VERSION ""

NS_ :

BS_:

BU_: ZCU_CL LRCF PAM ZCU_F HPC_MAIN_IVI

BO_ 121 FD15_ACK_EVT_DEF: 16 ZCU_CL
 SG_ ECU_Code_ACK : 15|8@0+ (1,0) [0|255] "" LRCF,PAM
 SG_ Rep_UCE : 7|1@0+ (1,0) [0|1] "" LRCF,PAM

BO_ 592 FD15_BSM_DATA_3: 32 ZCU_F
 SG_ ESC_STATUS : 132|3@0+ (1,0) [0|0] "" HPC_MAIN_IVI,LRCF,PAM
 SG_ TCS_STATUS : 22|1@0+ (1,0) [0|0] "" HPC_MAIN_IVI,LRCF,PAM
 SG_ DTC_STATE : 113|1@0+ (1,0) [0|0] "" HPC_MAIN_IVI,LRCF,PAM
 SG_ ESC_BRAKE_STATE : 112|1@0+ (1,0) [0|0] "" HPC_MAIN_IVI,LRCF,PAM
 SG_ ESC_TCS_STATE : 127|1@0+ (1,0) [0|0] "" HPC_MAIN_IVI,LRCF,PAM
 SG_ TCS_BRAKE_STATE : 126|1@0+ (1,0) [0|0] "" HPC_MAIN_IVI,LRCF,PAM
 SG_ TCS_STATE : 125|1@0+ (1,0) [0|0] "" HPC_MAIN_IVI,LRCF,PAM
 SG_ FREE_4 : 15|4@0+ (1,0) [0|0] "" HPC_MAIN_IVI,LRCF,PAM
 SG_ EPB_FAILSTATUS : 21|2@0+ (1,0) [0|0] "" HPC_MAIN_IVI,LRCF,PAM
 SG_ EPB_SECUREMENT_RELEASE_STATUS : 31|1@0+ (1,0) [0|0] "" HPC_MAIN_IVI,LRCF,PAM
 SG_ EPB_STATE : 19|4@0+ (1,0) [0|0] "" HPC_MAIN_IVI,LRCF,PAM
 SG_ EPB_SWITCH_POSITION_STATE : 30|2@0+ (1,0) [0|0] "" HPC_MAIN_IVI,LRCF,PAM
 SG_ VEHICLE_SECUREMENT_STATE : 28|2@0+ (1,0) [0|0] "" HPC_MAIN_IVI,LRCF,PAM
 SG_ E2E_ALIVE_BSM_DATA_3 : 11|4@0+ (1,0) [0|15] "-" HPC_MAIN_IVI,LRCF,PAM
 SG_ EPB_WHEEL_TORQUE_LIMITATION_REQ : 26|1@0+ (1,0) [0|0] "" HPC_MAIN_IVI,LRCF,PAM
 SG_ EPB_WHEEL_TORQUE_LIMITATION_VAL : 25|10@0+ (100,-51100) [-51100|51100] "N.m" HPC_MAIN_IVI,LRCF,PAM
 SG_ ROAD_SLOPE_ESTIMATED_VALUE : 47|8@0+ (1,-127) [-127|126] "%" HPC_MAIN_IVI,LRCF,PAM
 SG_ BRAKE_EMERGENCY_SIGNAL_REQUEST : 71|1@0+ (1,0) [0|0] "" HPC_MAIN_IVI,LRCF,PAM
 SG_ BRAKE_ASSISTANCE_FAILSTATUS : 57|2@0+ (1,0) [0|0] "" HPC_MAIN_IVI,LRCF,PAM
 SG_ AUTO_HOLD_STATE : 135|3@0+ (1,0) [0|0] "" HPC_MAIN_IVI,LRCF,PAM
 SG_ AEB_BRAKING_STATUS : 60|3@0+ (1,0) [0|0] "" HPC_MAIN_IVI,LRCF,PAM
 SG_ AEB_BRAKING_ACKNOWLEDGE : 63|3@0+ (1,0) [0|0] "" HPC_MAIN_IVI,LRCF,PAM
 SG_ DRIVERBRAKEPEDAL_WHEELTRQ_REQ : 55|8@0+ (50,-12650) [-12650|0] "N.m" HPC_MAIN_IVI,LRCF,PAM
 SG_ LXA_SAFETY_DYNVHL_STATE : 104|1@0+ (1,0) [0|0] "" HPC_MAIN_IVI,LRCF,PAM
 SG_ STEERING_COLLABORATI_YAWCTRL_REQ : 119|2@0+ (1,0) [0|0] "" HPC_MAIN_IVI,LRCF,PAM
 SG_ STEERING_CONTROL_AUTOMATIC_REQ : 117|2@0+ (1,0) [0|0] "" HPC_MAIN_IVI,LRCF,PAM
 SG_ STEERING_CONTROL_COLLABORATI_REQ : 115|2@0+ (1,0) [0|0] "" HPC_MAIN_IVI,LRCF,PAM
 SG_ VEHICLE_PATH_CURVATURE : 87|16@0+ (1E-05,-0.32766) [-0.32766|0.32767] "m-1" HPC_MAIN_IVI,LRCF,PAM
 SG_ STEERING_RACKPOSITI_YAWCTRL_STPT : 70|15@0+ (0.01,-164) [-164|163.65] "mm" HPC_MAIN_IVI,LRCF,PAM
 SG_ STEERING_RACKPOSITION_SETPOINT : 103|15@0+ (0.01,-164) [-164|163.65] "mm" HPC_MAIN_IVI,LRCF,PAM
 SG_ SBA_TRIGGER : 124|2@0+ (1,0) [0|0] "" HPC_MAIN_IVI,LRCF,PAM
 SG_ ACC_MOTION_CONTROL_STATE : 122|3@0+ (1,0) [0|0] "" HPC_MAIN_IVI,LRCF,PAM
 SG_ E2E_CRC_BSM_DATA_3 : 7|8@0+ (1,0) [0|0] "-" HPC_MAIN_IVI,LRCF,PAM

BO_ 337 FD15_BSM_DATA_4: 64 ZCU_F
 SG_ CARBODY_LAT_ACCEL_CORRECTED : 103|12@0+ (0.02,-40.94) [-40.94|40.92] "m/s2" HPC_MAIN_IVI,LRCF,PAM
 SG_ WHEEL_LONGI_SPEED_CALCUL_FL : 39|16@0+ (0.01,0) [0|655.33] "km/h" HPC_MAIN_IVI,LRCF,PAM
 SG_ WHEEL_LONGI_SPEED_CALCUL_FR : 55|16@0+ (0.01,0) [0|655.33] "km/h" HPC_MAIN_IVI,LRCF,PAM
 SG_ WHEEL_LONGI_SPEED_CALCUL_RL : 71|16@0+ (0.01,0) [0|655.33] "km/h" HPC_MAIN_IVI,LRCF,PAM
 SG_ WHEEL_LONGI_SPEED_CALCUL_RR : 87|16@0+ (0.01,0) [0|655.33] "km/h" HPC_MAIN_IVI,LRCF,PAM
 SG_ FREE_4 : 15|4@0+ (1,0) [0|0] "" HPC_MAIN_IVI,LRCF,PAM
 SG_ CARBODY_LONG_ACCEL_CORRECTED : 107|12@0+ (0.02,-40.94) [-40.94|40.92] "m/s2" HPC_MAIN_IVI,LRCF,PAM
 SG_ CARBODY_YAW_VELOCITY_FILTERED : 127|11@0+ (0.1,-102.4) [-102.4|102.1] "Degree/s" HPC_MAIN_IVI,LRCF,PAM
 SG_ VEHICLE_LONGI_ACCEL_CALCULATED : 215|10@0+ (0.08,-40.96) [-40.96|40.72] "m/s2" HPC_MAIN_IVI,LRCF,PAM
 SG_ VEHICLE_LONG_SPEED_COMPUTED_VAL : 143|16@0+ (0.01,0) [0|655.33] "km/h" HPC_MAIN_IVI,LRCF,PAM
 SG_ VEHICLE_LONG_SPEED_REFERENCE_VAL : 159|16@0+ (0.01,0) [0|655.33] "km/h" HPC_MAIN_IVI,LRCF,PAM
 SG_ VEHICLE_MOTION_DIRECTION : 254|3@0+ (1,0) [0|0] "" HPC_MAIN_IVI,LRCF,PAM
 SG_ WHEEL_ROLLING_DIRECTION_FL : 175|2@0+ (1,0) [0|0] "" HPC_MAIN_IVI,LRCF,PAM
 SG_ WHEEL_ROLLING_DIRECTION_FR : 173|2@0+ (1,0) [0|0] "" HPC_MAIN_IVI,LRCF,PAM
 SG_ WHEEL_ROLLING_DIRECTION_RL : 171|2@0+ (1,0) [0|0] "" HPC_MAIN_IVI,LRCF,PAM
 SG_ WHEEL_ROLLING_DIRECTION_RR : 169|2@0+ (1,0) [0|0] "" HPC_MAIN_IVI,LRCF,PAM
 SG_ WHEEL_ROTATION_PULSE_FL_COUNTER : 183|8@0+ (1,0) [0|253] "" HPC_MAIN_IVI,LRCF,PAM
 SG_ WHEEL_ROTATION_PULSE_FR_COUNTER : 191|8@0+ (1,0) [0|253] "" HPC_MAIN_IVI,LRCF,PAM
 SG_ WHEEL_ROTATION_PULSE_RL_COUNTER : 199|8@0+ (1,0) [0|253] "" HPC_MAIN_IVI,LRCF,PAM
 SG_ WHEEL_ROTATION_PULSE_RR_COUNTER : 207|8@0+ (1,0) [0|253] "" HPC_MAIN_IVI,LRCF,PAM
 SG_ WHEEL_ROTATION_PULSE_FL_FAIL_STS : 132|1@0+ (1,0) [0|0] "" HPC_MAIN_IVI,LRCF,PAM
 SG_ WHEEL_ROTATION_PULSE_FR_FAIL_STS : 131|1@0+ (1,0) [0|0] "" HPC_MAIN_IVI,LRCF,PAM
 SG_ WHEEL_ROTATION_PULSE_RL_FAIL_STS : 130|1@0+ (1,0) [0|0] "" HPC_MAIN_IVI,LRCF,PAM
 SG_ WHEEL_ROTATION_PULSE_RR_FAIL_STS : 129|1@0+ (1,0) [0|0] "" HPC_MAIN_IVI,LRCF,PAM
 SG_ E2E_ALIVE_BSM_DATA_4_151 : 11|4@0+ (1,0) [0|15] "-" HPC_MAIN_IVI,LRCF,PAM
 SG_ E2E_CRC_BSM_DATA_4_151 : 7|8@0+ (1,0) [0|0] "-" HPC_MAIN_IVI,LRCF,PAM
 SG_ BRAKE_STATE : 217|2@0+ (1,0) [0|0] "" HPC_MAIN_IVI,LRCF,PAM
 SG_ STOP_LIGHTS_ACTIVATION_REQUEST : 241|1@0+ (1,0) [0|0] "" HPC_MAIN_IVI,LRCF,PAM
 SG_ SAFESTOP_BRAKING_STATE : 228|3@0+ (1,0) [0|0] "" HPC_MAIN_IVI,LRCF,PAM
 SG_ BRAKE_PEDAL_PRESSED_STATE : 219|2@0+ (1,0) [0|0] "" HPC_MAIN_IVI,LRCF,PAM
 SG_ BAS_STATE : 25|1@0+ (1,0) [0|0] "" HPC_MAIN_IVI,LRCF,PAM
 SG_ ABS_STATE : 24|1@0+ (1,0) [0|0] "" HPC_MAIN_IVI,LRCF,PAM
 SG_ EBD_STATE : 128|1@0+ (1,0) [0|0] "" HPC_MAIN_IVI,LRCF,PAM
 SG_ ABS_WHEEL_FRONT_LEFT_STATE : 225|1@0+ (1,0) [0|0] "" HPC_MAIN_IVI,LRCF,PAM
 SG_ ABS_WHEEL_FRONT_RIGHT_STATE : 224|1@0+ (1,0) [0|0] "" HPC_MAIN_IVI,LRCF,PAM
 SG_ ABS_WHEEL_REAR_LEFT_STATE : 239|1@0+ (1,0) [0|0] "" HPC_MAIN_IVI,LRCF,PAM
 SG_ ABS_WHEEL_REAR_RIGHT_STATE : 238|1@0+ (1,0) [0|0] "" HPC_MAIN_IVI,LRCF,PAM
 SG_ BRAKE_ASSISTANCE_PRESSURE_VALUE : 237|12@0+ (0.1,-10) [-10|399.3] "bar" HPC_MAIN_IVI,LRCF,PAM
 SG_ ROAD_SLOPE_ACCURACY_STATE : 240|2@0+ (1,0) [0|0] "" HPC_MAIN_IVI,LRCF,PAM
 SG_ FREE_4_2 : 271|4@0+ (1,0) [0|0] "" HPC_MAIN_IVI,LRCF,PAM
 SG_ E2E_CRC_BSM_DATA_4_2 : 263|8@0+ (1,0) [0|0] "-" HPC_MAIN_IVI,LRCF,PAM
 SG_ E2E_ALIVE_BSM_DATA_4_2 : 267|4@0+ (1,0) [0|15] "-" HPC_MAIN_IVI,LRCF,PAM
 SG_ EBD_FAILSTATUS : 23|1@0+ (1,0) [0|0] "" HPC_MAIN_IVI,LRCF,PAM
 SG_ ABS_FAILSTATUS : 22|1@0+ (1,0) [0|0] "" HPC_MAIN_IVI,LRCF,PAM

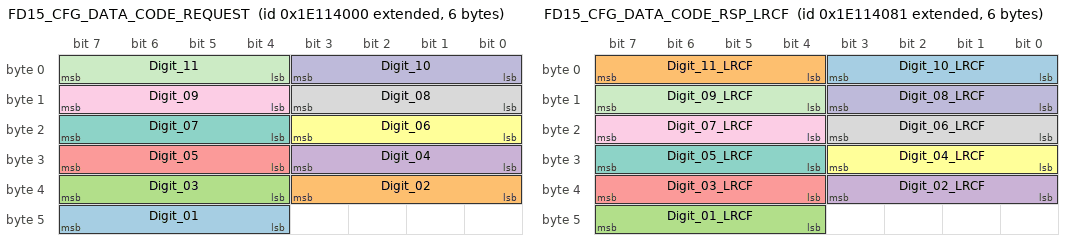
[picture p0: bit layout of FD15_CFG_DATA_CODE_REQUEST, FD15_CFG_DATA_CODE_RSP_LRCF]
BO_ 2651930624 FD15_CFG_DATA_CODE_REQUEST: 6 ZCU_CL
 SG_ Digit_01 : 47|4@0+ (1,0) [0|15] "" LRCF,PAM,ZCU_F
 SG_ Digit_02 : 35|4@0+ (1,0) [0|15] "" LRCF,PAM,ZCU_F
 SG_ Digit_03 : 39|4@0+ (1,0) [0|15] "" LRCF,PAM,ZCU_F
 SG_ Digit_04 : 27|4@0+ (1,0) [0|15] "" LRCF,PAM,ZCU_F
 SG_ Digit_05 : 31|4@0+ (1,0) [0|15] "" LRCF,PAM,ZCU_F
 SG_ Digit_06 : 19|4@0+ (1,0) [0|15] "" LRCF,PAM,ZCU_F
 SG_ Digit_07 : 23|4@0+ (1,0) [0|15] "" LRCF,PAM,ZCU_F
 SG_ Digit_08 : 11|4@0+ (1,0) [0|15] "" LRCF,PAM,ZCU_F
 SG_ Digit_09 : 15|4@0+ (1,0) [0|15] "" LRCF,PAM,ZCU_F
 SG_ Digit_10 : 3|4@0+ (1,0) [0|15] "" LRCF,PAM,ZCU_F
 SG_ Digit_11 : 7|4@0+ (1,0) [0|15] "" LRCF,PAM,ZCU_F

BO_ 2651930753 FD15_CFG_DATA_CODE_RSP_LRCF: 6 LRCF
 SG_ Digit_10_LRCF : 3|4@0+ (1,0) [0|15] "-" ZCU_CL
 SG_ Digit_11_LRCF : 7|4@0+ (1,0) [0|15] "-" ZCU_CL
 SG_ Digit_01_LRCF : 47|4@0+ (1,0) [0|15] "-" ZCU_CL
 SG_ Digit_02_LRCF : 35|4@0+ (1,0) [0|15] "-" ZCU_CL
 SG_ Digit_03_LRCF : 39|4@0+ (1,0) [0|15] "-" ZCU_CL
 SG_ Digit_04_LRCF : 27|4@0+ (1,0) [0|15] "-" ZCU_CL
 SG_ Digit_05_LRCF : 31|4@0+ (1,0) [0|15] "-" ZCU_CL
 SG_ Digit_06_LRCF : 19|4@0+ (1,0) [0|15] "-" ZCU_CL
 SG_ Digit_07_LRCF : 23|4@0+ (1,0) [0|15] "-" ZCU_CL
 SG_ Digit_08_LRCF : 11|4@0+ (1,0) [0|15] "-" ZCU_CL
 SG_ Digit_09_LRCF : 15|4@0+ (1,0) [0|15] "-" ZCU_CL

BO_ 2679898131 FD15_DEV_LRCF_1: 64 LRCF
 SG_ SIG_DEV_LRCF_1 : 7|512@0+ (1,0) [0|0] "" Vector__XXX

BO_ 2679898132 FD15_DEV_LRCF_2: 64 LRCF
 SG_ SIG_DEV_LRCF_2 : 7|512@0+ (1,0) [0|0] "" Vector__XXX

BO_ 2564476661 FD15_DIAG_REQUEST_FD_FOTA_LRCF: 64 HPC_MAIN_IVI
 SG_ N_PDU : 7|64@0+ (1,0) [0|0] "" LRCF

BO_ 2564484085 FD15_DIAG_REQUEST_FD_FOTA_SCRRL: 64 HPC_MAIN_IVI
 SG_ N_PDU : 7|64@0+ (1,0) [0|0] "" LRCF

BO_ 2564483829 FD15_DIAG_REQUEST_FD_FOTA_SCRRR: 64 HPC_MAIN_IVI
 SG_ N_PDU : 7|64@0+ (1,0) [0|0] "" LRCF

BO_ 2564481781 FD15_DIAG_REQUEST_FD_FOTA_SFRM: 64 HPC_MAIN_IVI
 SG_ N_PDU : 7|64@0+ (1,0) [0|0] "" LRCF

BO_ 2564554485 FD15_DIAG_REQUEST_FD_FUNC_FOTA: 64 HPC_MAIN_IVI
 SG_ N_PDU : 7|64@0+ (1,0) [0|0] "" LRCF,PAM,ZCU_F

BO_ 2564554482 FD15_DIAG_REQUEST_FD_FUNCTIONAL: 64 HPC_MAIN_IVI
 SG_ N_PDU : 7|64@0+ (1,0) [0|0] "" LRCF,PAM,ZCU_F

BO_ 2564476658 FD15_DIAG_REQUEST_FD_LRCF: 64 HPC_MAIN_IVI
 SG_ N_PDU : 7|64@0+ (1,0) [0|0] "" LRCF

BO_ 2564484082 FD15_DIAG_REQUEST_FD_SCRRL: 64 HPC_MAIN_IVI
 SG_ N_PDU : 7|64@0+ (1,0) [0|0] "" LRCF

BO_ 2564483826 FD15_DIAG_REQUEST_FD_SCRRR: 64 HPC_MAIN_IVI
 SG_ N_PDU : 7|64@0+ (1,0) [0|0] "" LRCF

BO_ 2564481778 FD15_DIAG_REQUEST_FD_SFRM: 64 HPC_MAIN_IVI
 SG_ N_PDU : 7|64@0+ (1,0) [0|0] "" LRCF

BO_ 2564486606 FD15_DIAG_RESPONSE_FD_FOTA_LRCF: 64 LRCF
 SG_ N_PDU : 7|64@0+ (1,0) [0|0] "" HPC_MAIN_IVI

BO_ 2564486635 FD15_DIAG_RESPONSE_FD_FOTA_SCRRL: 64 LRCF
 SG_ N_PDU : 7|64@0+ (1,0) [0|0] "" HPC_MAIN_IVI

BO_ 2564486634 FD15_DIAG_RESPONSE_FD_FOTA_SCRRR: 64 LRCF
 SG_ N_PDU : 7|64@0+ (1,0) [0|0] "" HPC_MAIN_IVI

BO_ 2564486626 FD15_DIAG_RESPONSE_FD_FOTA_SFRM: 64 LRCF
 SG_ N_PDU : 7|64@0+ (1,0) [0|0] "" HPC_MAIN_IVI

BO_ 2564485838 FD15_DIAG_RESPONSE_FD_LRCF: 64 LRCF
 SG_ N_PDU : 7|64@0+ (1,0) [0|0] "" HPC_MAIN_IVI

BO_ 2564485867 FD15_DIAG_RESPONSE_FD_SCRRL: 64 LRCF
 SG_ N_PDU : 7|64@0+ (1,0) [0|0] "" HPC_MAIN_IVI

BO_ 2564485866 FD15_DIAG_RESPONSE_FD_SCRRR: 64 LRCF
 SG_ N_PDU : 7|64@0+ (1,0) [0|0] "" HPC_MAIN_IVI

BO_ 2564485858 FD15_DIAG_RESPONSE_FD_SFRM: 64 LRCF
 SG_ N_PDU : 7|64@0+ (1,0) [0|0] "" HPC_MAIN_IVI

BO_ 2564682219 FD15_DIAGNOSTIC_ROE_SCRRL: 8 LRCF
 SG_ N_PDU : 7|64@0+ (1,0) [0|0] "" HPC_MAIN_IVI

BO_ 2564682218 FD15_DIAGNOSTIC_ROE_SCRRR: 8 LRCF
 SG_ N_PDU : 7|64@0+ (1,0) [0|0] "" HPC_MAIN_IVI

BO_ 2564682210 FD15_DIAGNOSTIC_ROE_SFRM: 8 LRCF
 SG_ N_PDU : 7|64@0+ (1,0) [0|0] "" HPC_MAIN_IVI

BO_ 340 FD15_EPS_DATA_1: 32 ZCU_F
 SG_ FREE_4 : 15|4@0+ (1,0) [0|0] "" LRCF
 SG_ STEERING_ASSIST_FAILSTATUS : 135|3@0+ (1,0) [0|0] "" LRCF
 SG_ STEERING_ASSIST_STATUS : 103|3@0+ (1,0) [0|0] "" LRCF
 SG_ STEERING_POWERSUPPLY_BOOST_REQ : 129|2@0+ (1,0) [0|0] "" LRCF
 SG_ LKA_STEERING_ACTUATION_STATE : 40|1@0+ (1,0) [0|0] "" LRCF
 SG_ LKA_STEERING_AVAILABILITY_STATE : 73|2@0+ (1,0) [0|0] "" LRCF
 SG_ LXA_STEERING_LIMITATION_STATE : 24|1@0+ (1,0) [0|0] "" LRCF
 SG_ LXA_STEERING_STATE : 91|2@0+ (1,0) [0|0] "" LRCF
 SG_ STEERINGWHEEL_ANGLE_CAL_FRT_STS : 89|2@0+ (1,0) [0|0] "" LRCF
 SG_ STEERINGWHEEL_ANGLE_REL_FRT_STE : 132|3@0+ (1,0) [0|0] "" LRCF
 SG_ STEERINGWHEEL_ANGLE_FRONT_TYPE : 57|2@0+ (1,0) [0|0] "" LRCF
 SG_ HANDWHEEL_STEERING_TRQ_MEASURED : 100|11@0+ (0.01,-10.2) [-10.2|10.27] "N.m" LRCF
 SG_ LXA_STEERING_TORQUE_ADDON_VALUE : 127|8@0+ (0.1,-12.5) [-12.5|13] "N.m" LRCF
 SG_ HANDWHEEL_STEERING_ANGLE_VALUE : 71|14@0+ (0.1,-820) [-820|818.2] "Degree" LRCF
 SG_ STEERINGWHEEL_ANGLE_FRT_ACCURACY : 105|10@0+ (0.1,-51) [-51|51.2] "Degree" LRCF
 SG_ STEERINGWHEEL_ANGLE_FRONT_VAL : 55|14@0+ (0.1,-820) [-820|818.2] "Degree" LRCF
 SG_ STEERINGWHEEL_ANGLE_REL_FRT_VA : 39|15@0+ (0.1,-1638) [-1638|1638.6] "Degree" LRCF
 SG_ WHEEL_STEERINGANGLE_FRONT_VAL : 23|15@0+ (0.005,-82) [-82|81.83] "Degree" LRCF
 SG_ STEERINGWHEEL_ROT_VELOCITY_FRT : 87|12@0+ (1,-2050) [-2050|2044] "Degree/s" LRCF
 SG_ E2E_CRC_EPS_DATA_1 : 7|8@0+ (1,0) [0|0] "-" LRCF
 SG_ E2E_ALIVE_EPS_DATA_1 : 11|4@0+ (1,0) [0|15] "-" LRCF

BO_ 596 FD15_EPS_DATA_2: 32 ZCU_F
 SG_ FREE_4 : 15|4@0+ (1,0) [0|0] "" LRCF
 SG_ STEERING_RACK_POSITION_VALUE : 23|15@0+ (0.01,-164) [-164|163.65] "mm" LRCF
 SG_ E2E_ALIVE_EPS_DATA_2 : 11|4@0+ (1,0) [0|15] "-" LRCF
 SG_ E2E_CRC_EPS_DATA_2 : 7|8@0+ (1,0) [0|0] "-" LRCF

BO_ 1406 FD15_FLT_EVT_LRCF: 24 LRCF
 SG_ ECU_CODE : 123|8@0+ (1,0) [0|255] "No Unit" ZCU_CL
 SG_ RELEVANCE_OF_DATE : 2|1@0+ (1,0) [0|0] "-" ZCU_CL
 SG_ NM_Frames : 7|2@0+ (1,0) [0|3] "" ZCU_CL
 SG_ Status_DTC : 3|1@0+ (1,0) [0|1] "" ZCU_CL
 SG_ Fault_Code : 15|24@0+ (1,0) [0|16777215] "" ZCU_CL
 SG_ DTC_Format_Identifier : 131|8@0+ (1,0) [0|255] "" ZCU_CL
 SG_ KM_DEH : 103|24@0+ (0.1,0) [0|1677721.4] "km" ZCU_CL
 SG_ Absolute_Defect_Event_Year : 39|16@0+ (1,0) [0|65534] "Year" ZCU_CL
 SG_ Absolute_Defect_Event_Month : 55|4@0+ (1,1) [1|15] "month" ZCU_CL
 SG_ Absolute_Defect_Event_Day : 63|5@0+ (1,1) [1|31] "day" ZCU_CL
 SG_ Absolute_Defect_Event_Hour : 71|5@0+ (1,0) [0|30] "h" ZCU_CL
 SG_ Absolute_Defect_Event_Minute : 79|6@0+ (1,0) [0|62] "min" ZCU_CL
 SG_ Absolute_Defect_Event_Second : 87|6@0+ (1,0) [0|62] "Sec" ZCU_CL
 SG_ Abs_Defect_Event_Tenth_Of_Sec : 95|8@0+ (0.1,0) [0|25.4] "Sec" ZCU_CL

BO_ 951 FD15_HPC_DATA_1: 32 ZCU_CL
 SG_ FREE_4 : 15|4@0+ (1,0) [0|0] "" LRCF,PAM,ZCU_F
 SG_ AEB_HAPTIC_REQUEST : 23|1@0+ (1,0) [0|0] "" LRCF,PAM,ZCU_F
 SG_ ACC_MODE_CHOICE_REQ : 55|2@0+ (1,0) [0|0] "" LRCF,PAM,ZCU_F
 SG_ ACC_AVAILABILITY_FOR_SWITCH : 71|1@0+ (1,0) [0|0] "" LRCF,PAM,ZCU_F
 SG_ ACC_TAKEOVER_REQUEST : 70|2@0+ (1,0) [0|0] "" LRCF,PAM,ZCU_F
 SG_ BLINDSPOTDETECTION_DRIVERREQUEST : 102|1@0+ (1,0) [0|0] "" LRCF,PAM,ZCU_F
 SG_ MAIN_LATERAL_ST_INFO : 22|3@0+ (1,0) [0|0] "" LRCF,PAM,ZCU_F
 SG_ MAIN_LONGITUDINAL_STINFO : 19|3@0+ (1,0) [0|0] "" LRCF,PAM,ZCU_F
 SG_ WPP_DRIVER_INHIBITION_REQUEST : 26|1@0+ (1,0) [0|0] "" LRCF,PAM,ZCU_F
 SG_ AEB_HMI_READY : 30|1@0+ (1,0) [0|0] "" LRCF,PAM,ZCU_F
 SG_ FCW_HMI_READY : 29|1@0+ (1,0) [0|0] "" LRCF,PAM,ZCU_F
 SG_ FCW_HMI_SETTING : 28|2@0+ (1,0) [0|0] "" LRCF,PAM,ZCU_F
 SG_ AEB_DRIVER_ATTENTIVE : 16|1@0+ (1,0) [0|0] "" LRCF,PAM,ZCU_F
 SG_ AEB_ROAD_FRICTION : 31|1@0+ (1,0) [0|0] "" LRCF,PAM,ZCU_F
 SG_ E2E_CRC_HPC_DATA_1 : 7|8@0+ (1,0) [0|0] "-" LRCF,PAM,ZCU_F
 SG_ E2E_ALIVE_HPC_DATA_1 : 11|4@0+ (1,0) [0|15] "-" LRCF,PAM,ZCU_F
 SG_ AEB_HMI_LIMITATION : 25|2@0+ (1,0) [0|0] "" LRCF,PAM,ZCU_F
 SG_ LONGITUDINAL_SPEED_SETPOINT : 39|15@0+ (0.01,0) [0|327.66] "km/h" LRCF,PAM,ZCU_F
 SG_ ELKS_SELECTION_REQ : 40|1@0+ (1,0) [0|0] "" LRCF,PAM,ZCU_F
 SG_ FCW_SETTING : 53|2@0+ (1,0) [0|0] "" LRCF,PAM,ZCU_F
 SG_ LRCF_CANCEL_REQ : 51|1@0+ (1,0) [0|0] "" LRCF,PAM,ZCU_F
 SG_ LRCF_DCTYPE : 49|2@0+ (1,0) [0|0] "" LRCF,PAM,ZCU_F
 SG_ LRCF_NUMBEROFDC : 63|8@0+ (1,0) [0|100] "" LRCF,PAM,ZCU_F
 SG_ LRCF_TRANSFER_READINESS_REQ : 50|1@0+ (1,0) [0|0] "" LRCF,PAM,ZCU_F
 SG_ LPA_STATE_INFO : 73|2@0+ (1,0) [0|0] "" LRCF,PAM,ZCU_F
 SG_ VHL_DL_OR_TX_ACTIVE : 68|2@0+ (1,0) [0|0] "" LRCF,PAM,ZCU_F
 SG_ OTA_UPDATE_STATUS : 66|4@0+ (1,0) [0|0] "" LRCF,PAM,ZCU_F
 SG_ ELKS_COCKPIT_FAILURE : 78|1@0+ (1,0) [0|0] "" LRCF,PAM,ZCU_F
 SG_ ACC_MAIN_ST_INFO : 77|4@0+ (1,0) [0|0] "" LRCF,PAM,ZCU_F
 SG_ ALERT_SOUND_LOCALIZATION : 87|4@0+ (1,0) [0|0] "" LRCF,PAM,ZCU_F
 SG_ ALERT_SOUND_LEVEL : 83|8@0+ (1,0) [0|255] "" LRCF,PAM,ZCU_F
 SG_ ALERT_SOUND_NUMBER : 91|5@0+ (1,0) [0|30] "" LRCF,PAM,ZCU_F
 SG_ SL_SPEED_SETPOINT_DUA : 107|8@0+ (1,0) [0|254] "km/h" LRCF,PAM,ZCU_F
 SG_ SL_ACTIVATION_REQUEST : 108|1@0+ (1,0) [0|1] "" LRCF,PAM,ZCU_F
 SG_ CC_ACTIVATION_REQUEST : 101|1@0+ (1,0) [0|1] "" LRCF,PAM,ZCU_F
 SG_ CC_SPEED_SETPOINT_DUA : 100|8@0+ (1,0) [0|254] "km/h" LRCF,PAM,ZCU_F
 SG_ REGULATION_LONGI_TYPE : 115|2@0+ (1,0) [0|3] "" LRCF,PAM,ZCU_F
 SG_ LPA_ST_INFO : 113|2@0+ (1,0) [0|3] "" LRCF,PAM,ZCU_F
 SG_ DDMS_STATE : 127|3@0+ (1,0) [0|7] "" LRCF,PAM,ZCU_F
 SG_ DDMS_FOV_AREA : 124|3@0+ (1,0) [0|7] "" LRCF,PAM,ZCU_F
 SG_ DDMS_EYE_STATUS : 121|3@0+ (1,0) [0|7] "" LRCF,PAM,ZCU_F
 SG_ DDMS_DROWSINESS_LEVEL : 134|3@0+ (1,0) [0|7] "" LRCF,PAM,ZCU_F
 SG_ DDMS_DISTRACTION_LEVEL : 131|3@0+ (1,0) [0|7] "" LRCF,PAM,ZCU_F
 SG_ DDM_SAFETY_MODE_REQUEST : 128|3@0+ (1,0) [0|7] "" LRCF,PAM,ZCU_F

BO_ 1719 FD15_HPC_DATA_2: 32 ZCU_CL
 SG_ RCTA_DRIVER_INHIBITION_REQUEST : 56|1@0+ (1,0) [0|0] "" LRCF,PAM
 SG_ ACC_TIV_SETPOINT : 22|2@0+ (1,0) [0|0] "" LRCF,PAM
 SG_ MAIN_AUTOMATION_ST_INFO : 20|3@0+ (1,0) [0|0] "" LRCF,PAM
 SG_ COUNTRY_CODE_MERGED : 31|24@0+ (1,0) [0|16777215] "" LRCF,PAM
 SG_ ACC_SPEED_SET_POINT : 55|15@0+ (0.01,0) [0|327.67] "km/h" LRCF,PAM

BO_ 633 FD15_HPC_DATA_3: 32 ZCU_CL
 SG_ ACC_STATE_INFO_FOR_CHASSIS : 33|2@0+ (1,0) [0|0] "" LRCF
 SG_ PACC_ACCEL_LONGI_REQUEST : 28|10@0+ (0.01,-5) [-5|5.23] "m/s2" LRCF
 SG_ PACC_BEVENT_IN_PROGRESS : 34|1@0+ (1,0) [0|0] "" LRCF
 SG_ GPAC_BINHIB_ACCEL_BEND_REQ : 29|1@0+ (0,0) [0|0] "" LRCF
 SG_ PACC_POTACCEL_LONGI_REQUEST : 23|10@0+ (0.01,-5) [-5|5.23] "m/s2" LRCF

BO_ 1154 FD15_LRCF_DATA_10: 64 LRCF
 SG_ IHM_R2_POSITION : 279|6@0+ (1,0) [0|0] "" ZCU_CL
 SG_ FRONTCAM_EGO_OBJ_TYPE : 299|3@0+ (1,0) [0|0] "" ZCU_CL
 SG_ FRONTCAM_EGO2_OBJ_TYPE : 296|3@0+ (1,0) [0|0] "" ZCU_CL
 SG_ FRONTCAM_L1_OBJ_TYPE : 309|3@0+ (1,0) [0|0] "" ZCU_CL
 SG_ FRONTCAM_L2_OBJ_TYPE : 306|3@0+ (1,0) [0|0] "" ZCU_CL
 SG_ FRONTCAM_L3_OBJ_TYPE : 319|3@0+ (1,0) [0|0] "" ZCU_CL
 SG_ FRONTCAM_R1_OBJ_TYPE : 316|3@0+ (1,0) [0|0] "" ZCU_CL
 SG_ FRONTCAM_R2_OBJ_TYPE : 313|3@0+ (1,0) [0|0] "" ZCU_CL
 SG_ FRONTCAM_R3_OBJ_TYPE : 326|3@0+ (1,0) [0|0] "" ZCU_CL
 SG_ FRONTCAM_EGO_OBJ_CONFID_OBJ : 283|2@0+ (1,0) [0|0] "" ZCU_CL
 SG_ FRONTCAM_EGO2_OBJ_CONFID_OBJ : 281|2@0+ (1,0) [0|0] "" ZCU_CL
 SG_ FRONTCAM_L1_OBJ_CONFID_OBJ : 295|2@0+ (1,0) [0|0] "" ZCU_CL
 SG_ FRONTCAM_L2_OBJ_CONFID_OBJ : 293|2@0+ (1,0) [0|0] "" ZCU_CL
 SG_ FRONTCAM_L3_OBJ_CONFID_OBJ : 291|2@0+ (1,0) [0|0] "" ZCU_CL
 SG_ FRONTCAM_R1_OBJ_CONFID_OBJ : 289|2@0+ (1,0) [0|0] "" ZCU_CL
 SG_ FRONTCAM_R2_OBJ_CONFID_OBJ : 303|2@0+ (1,0) [0|0] "" ZCU_CL
 SG_ FRONTCAM_R3_OBJ_CONFID_OBJ : 301|2@0+ (1,0) [0|0] "" ZCU_CL
 SG_ FRONTCAM_EGO_OBJ_LAT_DISTANCE : 29|6@0+ (0.5,-16) [-16|15.5] "m" ZCU_CL
 SG_ FRONTCAM_EGO2_OBJ_LAT_DISTANCE : 45|6@0+ (0.5,-16) [-16|15.5] "m" ZCU_CL
 SG_ FRONTCAM_L1_OBJ_LAT_DISTANCE : 61|6@0+ (0.5,-16) [-16|15.5] "m" ZCU_CL
 SG_ FRONTCAM_L2_OBJ_LAT_DISTANCE : 77|6@0+ (0.5,-16) [-16|15.5] "m" ZCU_CL
 SG_ FRONTCAM_L3_OBJ_LAT_DISTANCE : 93|6@0+ (0.5,-16) [-16|15.5] "m" ZCU_CL
 SG_ FRONTCAM_R1_OBJ_LAT_DISTANCE : 109|6@0+ (0.5,-16) [-16|15.5] "m" ZCU_CL
 SG_ FRONTCAM_R2_OBJ_LAT_DISTANCE : 125|6@0+ (0.5,-16) [-16|15.5] "m" ZCU_CL
 SG_ FRONTCAM_R3_OBJ_LAT_DISTANCE : 141|6@0+ (0.5,-16) [-16|15.5] "m" ZCU_CL
 SG_ FRONTCAM_EGO_OBJ_LONGI_REL_SPD : 23|10@0+ (0.5,-256) [-256|255.5] "m/s" ZCU_CL
 SG_ FRONTCAM_EGO2_OBJ_LONGI_REL_SPD : 39|10@0+ (0.5,-256) [-256|255.5] "m/s" ZCU_CL
 SG_ FRONTCAM_L1_OBJ_LONGI_REL_SPD : 55|10@0+ (0.5,-256) [-256|255.5] "m/s" ZCU_CL
 SG_ FRONTCAM_L2_OBJ_LONGI_REL_SPD : 71|10@0+ (0.5,-256) [-256|255.5] "m/s" ZCU_CL
 SG_ FRONTCAM_L3_OBJ_LONGI_REL_SPD : 87|10@0+ (0.5,-256) [-256|255.5] "m/s" ZCU_CL
 SG_ FRONTCAM_R1_OBJ_LONGI_REL_SPD : 103|10@0+ (0.5,-256) [-256|255.5] "m/s" ZCU_CL
 SG_ FRONTCAM_R2_OBJ_LONGI_REL_SPD : 119|10@0+ (0.5,-256) [-256|255.5] "m/s" ZCU_CL
 SG_ FRONTCAM_R3_OBJ_LONGI_REL_SPD : 135|10@0+ (0.5,-256) [-256|255.5] "m/s" ZCU_CL
 SG_ FRONTCAM_L2_OBJ_LAT_REL_SPD : 151|7@0+ (0.5,-32) [-32|31.5] "m/s" ZCU_CL
 SG_ FRONTCAM_L3_OBJ_LAT_REL_SPD : 190|7@0+ (0.5,-32) [-32|31.5] "m/s" ZCU_CL
 SG_ FRONTCAM_R1_OBJ_LAT_REL_SPD : 154|7@0+ (0.5,-32) [-32|31.5] "m/s" ZCU_CL
 SG_ FRONTCAM_R2_OBJ_LAT_REL_SPD : 163|7@0+ (0.5,-32) [-32|31.5] "m/s" ZCU_CL
 SG_ FRONTCAM_R3_OBJ_LAT_REL_SPD : 172|7@0+ (0.5,-32) [-32|31.5] "m/s" ZCU_CL
 SG_ FRONTCAM_EGO_OBJ_HANDLE : 181|7@0+ (1,0) [0|127] "" ZCU_CL
 SG_ FRONTCAM_EGO2_OBJ_HANDLE : 199|7@0+ (1,0) [0|127] "" ZCU_CL
 SG_ FRONTCAM_L1_OBJ_HANDLE : 192|7@0+ (1,0) [0|127] "" ZCU_CL
 SG_ FRONTCAM_L2_OBJ_HANDLE : 201|7@0+ (1,0) [0|127] "" ZCU_CL
 SG_ FRONTCAM_L3_OBJ_HANDLE : 210|7@0+ (1,0) [0|127] "" ZCU_CL
 SG_ FRONTCAM_R1_OBJ_HANDLE : 219|7@0+ (1,0) [0|127] "" ZCU_CL
 SG_ FRONTCAM_R2_OBJ_HANDLE : 228|7@0+ (1,0) [0|127] "" ZCU_CL
 SG_ FRONTCAM_R3_OBJ_HANDLE : 247|7@0+ (1,0) [0|127] "" ZCU_CL
 SG_ IHM_EGO_POSITION : 273|6@0+ (1,0) [0|0] "" ZCU_CL
 SG_ IHM_L1_POSITION : 255|6@0+ (1,0) [0|0] "" ZCU_CL
 SG_ IHM_L2_POSITION : 144|6@0+ (1,0) [0|0] "" ZCU_CL
 SG_ IHM_R1_POSITION : 237|6@0+ (1,0) [0|0] "" ZCU_CL

BO_ 661 FD15_LRCF_DATA_11: 64 LRCF
 SG_ FCAM_VRU4_TYPE : 500|2@0+ (1,0) [0|0] "" ZCU_CL
 SG_ FCAM_VRU5_TYPE : 498|2@0+ (1,0) [0|0] "" ZCU_CL
 SG_ FCAM_VRU1_TYPE : 490|2@0+ (1,0) [0|0] "" ZCU_CL
 SG_ FCAM_VRU2_TYPE : 488|2@0+ (1,0) [0|0] "" ZCU_CL
 SG_ FCAM_VRU3_TYPE : 502|2@0+ (1,0) [0|0] "" ZCU_CL
 SG_ FCAM_VRU4_LONG_DIST : 439|8@0+ (0.5,0) [0|127.5] "m" ZCU_CL
 SG_ FCAM_VRU2_LONG_DIST : 423|8@0+ (0.5,0) [0|127.5] "m" ZCU_CL
 SG_ FCAM_VRU3_LAT_DIST : 459|6@0+ (0.5,-16) [-16|15.5] "" ZCU_CL
 SG_ FCAM_VRU5_LAT_DIST : 479|6@0+ (0.5,-16) [-16|15.5] "" ZCU_CL
 SG_ FCAM_VRU1_LONG_DIST : 415|8@0+ (0.5,0) [0|127.5] "m" ZCU_CL
 SG_ FCAM_VRU3_LONG_DIST : 431|8@0+ (0.5,0) [0|127.5] "m" ZCU_CL
 SG_ FCAM_VRU5_LONG_DIST : 447|8@0+ (0.5,0) [0|127.5] "m" ZCU_CL
 SG_ FCAM_VRU1_LAT_DIST : 455|6@0+ (0.5,-16) [-16|15.5] "" ZCU_CL
 SG_ FCAM_VRU2_LAT_DIST : 449|6@0+ (0.5,-16) [-16|15.5] "" ZCU_CL
 SG_ FCAM_VRU4_LAT_DIST : 469|6@0+ (0.5,-16) [-16|15.5] "" ZCU_CL
 SG_ EGO_DIR_ROAD_LANENUMBER : 20|3@0+ (1,0) [0|7] "" ZCU_CL
 SG_ FCAM_LEFTRIGHT_CONFIDENCE_MEA : 31|7@0+ (0.01,0) [0|1.27] "" ZCU_CL
 SG_ FCAM_LEFTRIGHT_LINE_DIS_ACTUAL : 71|11@0+ (0.016,-16.384) [-16.384|16.336] "m" ZCU_CL
 SG_ FCAM_LEFTRIGHT_LINE_LAT_DIST : 63|6@0+ (0.5,-16) [-16|15.5] "m" ZCU_CL
 SG_ FCAM_LEFTRIGHT_LINECOLOR : 17|2@0+ (1,0) [0|3] "" ZCU_CL
 SG_ FCAM_LEFTRIGHT_LINECURVATURE_EST : 47|16@0+ (2E-06,-0.065536) [-0.065536|0.065530] "m-1" ZCU_CL
 SG_ FCAM_LEFTRIGHT_LINECURVATURE_DER : 87|17@0+ (4E-09,-0.000131072) [-0.000131072|0.00013106] "m-2" ZCU_CL
 SG_ FCAM_LLANE_ROADEDG_CURVATURE_DER : 119|17@0+ (4E-09,-0.000131072) [-0.000131072|0.00013106] "m-2" ZCU_CL
 SG_ FCAM_RIGHTLEFT_LINECURVATURE_DER : 303|17@0+ (4E-09,-0.000131072) [-0.000131072|0.00013106] "m-2" ZCU_CL
 SG_ FCAM_RLANE_ROADEDG_CURVATURE_DER : 279|17@0+ (4E-09,-0.000131072) [-0.000131072|0.00013106] "m-2" ZCU_CL
 SG_ FCAM_LLANE_ROADEDG_CURVATURE_EST : 143|16@0+ (2E-06,-0.065536) [-0.065536|0.065530] "m-1" ZCU_CL
 SG_ FCAM_RIGHTLEFT_LINECURVATURE_EST : 327|16@0+ (2E-06,-0.065536) [-0.065536|0.065530] "m-1" ZCU_CL
 SG_ FCAM_RLANE_ROADEDG_CURVATURE_EST : 343|16@0+ (2E-06,-0.065536) [-0.065536|0.065530] "m-1" ZCU_CL
 SG_ FCAM_LLANE_ROADEDG_DIST_ACTUAL : 153|11@0+ (0.016,-16.384) [-16.384|16.336] "m" ZCU_CL
 SG_ FCAM_RIGHTLEFT_LINE_DIST_ACTUAL : 247|11@0+ (0.016,-16.384) [-16.384|16.336] "m" ZCU_CL
 SG_ FCAM_RLANE_ROADEDG_DIST_ACTUAL : 359|11@0+ (0.016,-16.384) [-16.384|16.336] "m" ZCU_CL
 SG_ FCAM_LEFTRIGHT_LINEHEADINGANGLE : 102|12@0+ (0.015,-30) [-30|31.395] "Degree" ZCU_CL
 SG_ FCAM_LLANE_ROADEDG_HEADINGANGLE : 174|12@0+ (0.015,-30) [-30|31.395] "Degree" ZCU_CL
 SG_ FCAM_RIGHTLEFT_LINEHEADINGANGLE : 391|12@0+ (0.015,-30) [-30|31.395] "Degree" ZCU_CL
 SG_ FCAM_RLANE_ROADEDG_HEADINGANGLE : 395|12@0+ (0.015,-30) [-30|31.395] "Degree" ZCU_CL
 SG_ FCAM_RIGHTLEFT_LINE_LAT_DIST : 159|6@0+ (0.5,-16) [-16|15.5] "m" ZCU_CL
 SG_ FCAM_LEFTRIGHT_LINEVIEW_RANGEEND : 231|9@0+ (0.5,0) [0|255.5] "m" ZCU_CL
 SG_ FCAM_LEFTRIGHT_LINEVIEW_RANGESTR : 238|7@0+ (0.5,0) [0|63.5] "m" ZCU_CL
 SG_ FCAM_LLANE_ROADEDG_CONFIDENC_MEA : 191|7@0+ (0.01,0) [0|1.27] "" ZCU_CL
 SG_ FCAM_LLANE_ROADEDG_VIEW_RANGEEND : 199|9@0+ (0.5,0) [0|255.5] "m" ZCU_CL
 SG_ FCAM_LLINE_CONFIDENCE_MEA : 206|7@0+ (0.01,0) [0|1.27] "" ZCU_CL
 SG_ FCAM_NEXTLEFTLINE_CONFIDENCE_MEA : 134|7@0+ (0.01,0) [0|1.27] "" ZCU_CL
 SG_ FCAM_NEXTRIGHTLINE_CONFIDENC_MEA : 294|7@0+ (0.01,0) [0|1.27] "" ZCU_CL
 SG_ FCAM_RIGHTLEFT_CONFIDENCE_MEA : 318|7@0+ (0.01,0) [0|1.27] "" ZCU_CL
 SG_ FCAM_RLANE_ROADEDG_CONFIDENC_MEA : 382|7@0+ (0.01,0) [0|1.27] "" ZCU_CL
 SG_ FCAM_RLANE_ROADEDG_VIEW_RANGEEND : 375|9@0+ (0.5,0) [0|255.5] "m" ZCU_CL
 SG_ FCAM_RLINE_CONFIDENCE_MEA : 472|7@0+ (0.01,0) [0|1.27] "" ZCU_CL
 SG_ FCAM_LEFTRIGHT_LINEDETECTIONSTS : 24|1@0+ (1,0) [0|1] "" ZCU_CL
 SG_ FCAM_LEFTRIGHT_LINEMARKERQUALITY : 57|2@0+ (1,0) [0|3] "" ZCU_CL
 SG_ FCAM_LEFTRIGHT_LINETYPE : 23|3@0+ (1,0) [0|7] "" ZCU_CL
 SG_ FCAM_RIGHTLEFT_LINETYPE : 252|3@0+ (1,0) [0|7] "" ZCU_CL
 SG_ FCAM_RIGHTLEFT_LINEDETECTIONSTS : 364|1@0+ (1,0) [0|1] "" ZCU_CL
 SG_ FCAM_RIGHTLEFT_LINECOLOR : 249|2@0+ (1,0) [0|3] "" ZCU_CL
 SG_ FCAM_LLANE_ROADEDG_MARKERQUALITY : 73|2@0+ (1,0) [0|3] "" ZCU_CL
 SG_ FCAM_RIGHTLEFT_LINEMARKERQUALITY : 363|2@0+ (1,0) [0|3] "" ZCU_CL
 SG_ FCAM_RLANE_ROADEDG_MARKERQUALITY : 361|2@0+ (1,0) [0|3] "" ZCU_CL
 SG_ FCAM_LLANE_ROADEDG_DET_STATUS : 32|1@0+ (1,0) [0|1] "" ZCU_CL
 SG_ FCAM_LLANE_ROADEDG_VIEW_RANSTART : 39|7@0+ (0.5,0) [0|63.5] "m" ZCU_CL
 SG_ FCAM_RLANE_ROADEDG_VIEW_RANSTART : 481|7@0+ (0.5,0) [0|63.5] "m" ZCU_CL
 SG_ FCAM_LLANE_ROADEDGETYPE : 76|3@0+ (1,0) [0|7] "" ZCU_CL
 SG_ FCAM_LLINE_VALIDFORLKA : 184|1@0+ (1,0) [0|1] "" ZCU_CL
 SG_ FCAM_RIGHTLEFT_LINEVIEW_RANGEEND : 215|9@0+ (0.5,0) [0|255.5] "m" ZCU_CL
 SG_ FCAM_RIGHTLEFT_LINEVIEW_RANGESTR : 222|7@0+ (0.5,0) [0|63.5] "m" ZCU_CL
 SG_ FCAM_OBJECTCROSSING : 178|2@0+ (1,0) [0|3] "" ZCU_CL
 SG_ FCAM_RLANE_ROADEDG_DET_STATUS : 176|1@0+ (1,0) [0|1] "" ZCU_CL
 SG_ FCAM_RLANE_ROADEDGETYPE : 106|3@0+ (1,0) [0|7] "" ZCU_CL
 SG_ FCAM_RLINE_VALIDFORLKA : 473|1@0+ (1,0) [0|1] "" ZCU_CL

BO_ 641 FD15_LRCF_DATA_2: 32 LRCF
 SG_ FREE_4 : 15|4@0+ (1,0) [0|0] "" ZCU_CL,ZCU_F
 SG_ AEB_PREFILL_REQUEST : 19|1@0+ (1,0) [0|0] "" ZCU_CL,ZCU_F
 SG_ AEB_STATE_A : 22|3@0+ (1,0) [0|0] "" ZCU_CL,ZCU_F
 SG_ ADAS_LONGI_ACCEL_REQUEST : 31|11@0+ (0.01,-12) [-12|8.47] "m/s2" ZCU_CL,ZCU_F
 SG_ E2E_ALIVE_LRCF_DATA_2 : 11|4@0+ (1,0) [0|15] "-" ZCU_CL,ZCU_F
 SG_ E2E_CRC_LRCF_DATA_2 : 7|8@0+ (1,0) [0|0] "-" ZCU_CL,ZCU_F
 SG_ DRIVER_STEERING_WHEEL_INTERACT : 34|3@0+ (1,0) [0|0] "" ZCU_CL,ZCU_F
 SG_ YAW_RATE_REQUEST_SETPOINT : 47|11@0+ (0.05,-50) [-50|52.25] "Degree/s" ZCU_CL,ZCU_F
 SG_ TORQUE_FACTOR_REQUEST : 52|7@0+ (0.01,0) [0|1.25] "" ZCU_CL,ZCU_F
 SG_ DST_WIDTH_EGO_LINE : 69|11@0+ (0.01,0) [0|20.45] "m" ZCU_CL,ZCU_F
 SG_ ACTIVATED_LATERAL_ASSIST_MODE : 87|1@0+ (1,0) [0|0] "" ZCU_CL,ZCU_F
 SG_ PERCEPTION_SYSTEM_STATE : 61|4@0+ (1,0) [0|0] "" ZCU_CL,ZCU_F
 SG_ LANE_ASSIST_STATE : 74|3@0+ (1,0) [0|0] "" ZCU_CL,ZCU_F
 SG_ PERCEPTION_STATE : 57|4@0+ (1,0) [0|0] "" ZCU_CL,ZCU_F
 SG_ ACC_POTENTIAL_ACCELERATION_REQ : 95|11@0+ (0.01,-11) [-11|9.47] "m/s2" ZCU_CL,ZCU_F
 SG_ ACC_JERK_MIN_SETPOINT : 84|5@0+ (0.2,-5) [-5|1.2] "m/s3" ZCU_CL,ZCU_F
 SG_ ADAS_LONGI_ACCEL_TYPE : 18|3@0+ (1,0) [0|0] "" ZCU_CL,ZCU_F
 SG_ LPA_PERCEPTION_STATE : 36|2@0+ (1,0) [0|0] "" ZCU_CL,ZCU_F

BO_ 1153 FD15_LRCF_DATA_3: 32 LRCF
 SG_ FREE_4 : 15|4@0+ (1,0) [0|0] "" ZCU_CL
 SG_ AEB_LIMITED : 23|1@0+ (1,0) [0|0] "" ZCU_CL
 SG_ FCW2_REQUEST : 16|1@0+ (1,0) [0|0] "" ZCU_CL
 SG_ FRONT_CAMERA_BLIND : 31|1@0+ (1,0) [0|0] "" ZCU_CL
 SG_ FRONT_RADAR_BLIND : 30|1@0+ (1,0) [0|0] "" ZCU_CL
 SG_ HMI_AEB_BRAKING_ACTIVE : 29|1@0+ (1,0) [0|0] "" ZCU_CL
 SG_ FCW2_SIDEALERT : 22|2@0+ (1,0) [0|0] "" ZCU_CL
 SG_ FCW_STATE_A : 20|3@0+ (1,0) [0|0] "" ZCU_CL
 SG_ EBF_ACCELERATION_TYPE : 28|3@0+ (1,0) [0|0] "" ZCU_CL
 SG_ E2E_CRC_LRCF_DATA_3 : 7|8@0+ (1,0) [0|0] "-" ZCU_CL
 SG_ E2E_ALIVE_LRCF_DATA_3 : 11|4@0+ (1,0) [0|15] "-" ZCU_CL
 SG_ FCW1_TARGET_PRESENT : 24|1@0+ (1,0) [0|0] "" ZCU_CL
 SG_ FCW1_TARGET_SPEED : 39|8@0+ (1,0) [0|255] "" ZCU_CL
 SG_ FCW1_HEADWAY : 47|8@0+ (0.02,0) [0|5.1] "" ZCU_CL
 SG_ AEB_HAPTIC_CRITICAL : 25|1@0+ (1,0) [0|0] "" ZCU_CL
 SG_ AEB_DETECTION_LIMITED : 17|1@0+ (1,0) [0|0] "" ZCU_CL
 SG_ DATA_TRANSFER_STATUS : 50|2@0+ (1,0) [0|0] "" ZCU_CL
 SG_ ERROR_TYPE : 61|2@0+ (1,0) [0|0] "" ZCU_CL
 SG_ READINESS_STATUS : 48|1@0+ (1,0) [0|0] "" ZCU_CL
 SG_ ERROR_REASON : 63|2@0+ (1,0) [0|0] "" ZCU_CL
 SG_ SAFETY_LRCF_READY_STATE : 59|1@0+ (1,0) [0|1] "" ZCU_CL
 SG_ LRCF_UPDATE_STATUS : 52|2@0+ (1,0) [0|3] "" ZCU_CL

BO_ 1409 FD15_LRCF_DATA_4: 32 LRCF
 SG_ LKA_STATE : 128|3@0+ (1,0) [0|0] "" HPC_MAIN_IVI,ZCU_CL,ZCU_F
 SG_ RCTA_STATE : 39|3@0+ (1,0) [0|0] "" HPC_MAIN_IVI,ZCU_CL,ZCU_F
 SG_ FREE_4 : 15|4@0+ (1,0) [0|0] "" ZCU_CL,ZCU_F
 SG_ RCTA_WARNINGSTATE_LEFT : 27|2@0+ (1,0) [0|0] "" ZCU_CL,ZCU_F
 SG_ RCTA_WARNINGSTATE_RIGHT : 25|2@0+ (1,0) [0|0] "" ZCU_CL,ZCU_F
 SG_ BLINDSPOT_DETECTION_STATUS : 118|3@0+ (1,0) [0|0] "" ZCU_CL,ZCU_F
 SG_ BLINDSPOTDETECTIONLEFTALERTRQST : 115|2@0+ (1,0) [0|0] "" ZCU_CL,ZCU_F
 SG_ BLINDSPOTDETECTIONRIGHTALERTRQST : 113|2@0+ (1,0) [0|0] "" ZCU_CL,ZCU_F
 SG_ FRONT_CAMERA_SPEED_LIMIT : 47|8@0+ (1,0) [0|255] "" ZCU_CL,ZCU_F
 SG_ FRONT_CAMERA_TRAFFIC_SIGN_DIST : 79|9@0+ (0.5,-210) [-210|45] "" ZCU_CL,ZCU_F
 SG_ FRONT_CAMERA_SPEED_LIMIT_AGE : 111|9@0+ (20,0) [0|10220] "" ZCU_CL,ZCU_F
 SG_ FRONT_CAMERA_SPEED_LIMIT_SOURCE : 103|3@0+ (1,0) [0|0] "" ZCU_CL,ZCU_F
 SG_ FRONT_CAMERA_SPEED_LIMIT_SHAPE : 100|3@0+ (1,0) [0|0] "" ZCU_CL,ZCU_F
 SG_ FRONT_CAMERA_CONDSPEED_LIMIT : 95|8@0+ (1,0) [0|255] "" ZCU_CL,ZCU_F
 SG_ FRONT_CAMERA_CONDSPEED_LIMIT_AGE : 63|9@0+ (20,0) [0|10220] "" ZCU_CL,ZCU_F
 SG_ FRONT_CAMERA_CONDSPEED_LIMIT_TYP : 36|5@0+ (1,0) [0|0] "" ZCU_CL,ZCU_F
 SG_ FRONT_CAMERA_SIGN_STATUS : 65|2@0+ (1,0) [0|0] "" ZCU_CL,ZCU_F
 SG_ FRONT_CAMERA_TRAFFICSIGN_RAW : 55|8@0+ (1,0) [0|255] "" ZCU_CL,ZCU_F
 SG_ FRONT_CAMERA_TRAFFICSIGN_RAW_SUP : 70|5@0+ (1,0) [0|31] "" ZCU_CL,ZCU_F
 SG_ FRONT_CAMERA_ROAD_TYPE_RAW : 97|2@0+ (1,0) [0|0] "" ZCU_CL,ZCU_F
 SG_ FRONT_CAMERA_ROAD_TYPE : 86|4@0+ (1,0) [0|0] "" ZCU_CL,ZCU_F
 SG_ FRONT_CAMERA_TRAFFIC_SIGN : 82|3@0+ (1,0) [0|0] "" ZCU_CL,ZCU_F
 SG_ LONGITUDINAL_DRIVING_STINFO : 127|4@0+ (1,0) [0|0] "" ZCU_CL,ZCU_F
 SG_ LAS_LEFT_LINE_STATE : 134|3@0+ (1,0) [0|0] "" ZCU_CL,ZCU_F
 SG_ LAS_RIGHT_LINE_STATE : 121|3@0+ (1,0) [0|0] "" ZCU_CL,ZCU_F
 SG_ LAS_INTERRUPT_ALERT : 131|1@0+ (1,0) [0|0] "" ZCU_CL,ZCU_F
 SG_ LAS_DRIVER_CONTROL_ALERT : 130|2@0+ (1,0) [0|0] "" ZCU_CL,ZCU_F
 SG_ HIGH_BEAM_ASSIST_REQ_FROM_CAMERA : 141|1@0+ (1,0) [0|0] "" ZCU_CL,ZCU_F
 SG_ HIGH_BEAM_ASSIST_CONDITION : 140|1@0+ (1,0) [0|0] "" ZCU_CL,ZCU_F
 SG_ HIGH_BEAM_ASSIST_FAULT : 139|1@0+ (1,0) [0|0] "" ZCU_CL,ZCU_F
 SG_ LIGHTED_ZONE_DETECTED : 138|3@0+ (1,0) [0|0] "" ZCU_CL,ZCU_F
 SG_ LAS_FRONT_SENSOR_BLOCKAGE_STATUS : 151|2@0+ (1,0) [0|0] "" ZCU_CL,ZCU_F
 SG_ LAS_REAR_SENSOR_BLOKAGE_STS : 147|2@0+ (1,0) [0|0] "" ZCU_CL,ZCU_F
 SG_ LAS_HAPTIC_ALERT_REQ : 149|2@0+ (1,0) [0|0] "" ZCU_CL,ZCU_F
 SG_ E2E_CRC_LRCF_DATA_4 : 7|8@0+ (1,0) [0|0] "-" ZCU_CL,ZCU_F
 SG_ E2E_ALIVE_LRCF_DATA_4 : 11|4@0+ (1,0) [0|15] "-" ZCU_CL,ZCU_F
 SG_ VRU_IN_EXTENDED_FRONT_AREA : 31|1@0+ (1,0) [0|0] "" ZCU_CL,ZCU_F

CM_ "Standard_STLA Brain V1";
CM_ SG_ 121 ECU_Code_ACK "ECU code of the defect sender";
CM_ SG_ 121 Rep_UCE "Acknowledgement of a request for read the defect event history";
CM_ SG_ 592 ESC_STATUS "It provides the status of Active Trajectory Control deactivation in standard use phase.";
CM_ SG_ 592 TCS_STATUS "it provides the status of Traction Control deactivation in standard use phase";
CM_ SG_ 592 DTC_STATE "Indicates that a DTC regulation by Engine System is on going";
CM_ SG_ 592 ESC_BRAKE_STATE "It indicates that an ESC regulation by Braking System is on going";
CM_ SG_ 592 ESC_TCS_STATE "It indicates that an ESC or TCS regulation by Braking System or Engine System is on going.";
CM_ SG_ 592 TCS_BRAKE_STATE "Indicates that a TCS regulation by Braking System is on going";
CM_ SG_ 592 TCS_STATE "it indicates that a TCS regulation by Braking System or Engine System is on going";
CM_ SG_ 592 EPB_FAILSTATUS "It provides the failure status of the EPB system or a part of the system.";
CM_ SG_ 592 EPB_SECUREMENT_RELEASE_STATUS "it provides the EPB system approval to leave the vehicle motion securement.";
CM_ SG_ 592 EPB_STATE "It provides the state of the EPB.";
CM_ SG_ 592 EPB_SWITCH_POSITION_STATE "It provides the position of the EPB switch.";
CM_ SG_ 592 VEHICLE_SECUREMENT_STATE "it provides the information if the vehicle motion is secure or not.";
CM_ SG_ 592 E2E_ALIVE_BSM_DATA_3 " E2E Process Counter for FD14_BSM_DATA_3 frame";
CM_ SG_ 592 EPB_WHEEL_TORQUE_LIMITATION_REQ "It provides the request of EPB system to limit the wheel torque during the automatic EPB release stage.";
CM_ SG_ 592 EPB_WHEEL_TORQUE_LIMITATION_VAL "It provides the value of the wheel torque limitation requested by the EPB system.";
CM_ SG_ 592 ROAD_SLOPE_ESTIMATED_VALUE "Value of the estimated road slope";
CM_ SG_ 592 BRAKE_EMERGENCY_SIGNAL_REQUEST "emergency braking signalisation request according to the braking situation and vehicle deceleration";
CM_ SG_ 592 BRAKE_ASSISTANCE_FAILSTATUS "It provides the fail status of the braking assistance and the braking system
";
CM_ SG_ 592 AUTO_HOLD_STATE "It provides the Auto Hold hydraulic maintain state
";
CM_ SG_ 592 AEB_BRAKING_STATUS "It provides the status of the AEB function for Brake contribution
";
CM_ SG_ 592 AEB_BRAKING_ACKNOWLEDGE " acknowlegement value of the AEB function for Brake contribution";
CM_ SG_ 592 DRIVERBRAKEPEDAL_WHEELTRQ_REQ "wheel brake torque requested by the driver at brake pedal";
CM_ SG_ 592 LXA_SAFETY_DYNVHL_STATE "LxA safety mechanism state relative to the Vehicle Motion Yaw Controller.
Inactive : the safety mechanism has not been triggered.
Active : the safety mechanism has been triggered.";
CM_ SG_ 592 STEERING_COLLABORATI_YAWCTRL_REQ "state request from ESC to EPS for perform the yaw control by rack position control";
CM_ SG_ 592 STEERING_CONTROL_AUTOMATIC_REQ "BSM CPK status.";
CM_ SG_ 592 STEERING_CONTROL_COLLABORATI_REQ "BSM LxA status.";
CM_ SG_ 592 VEHICLE_PATH_CURVATURE "image of the vehicle path curvature at the midle of the rear axle. Positive when vehicle turn right.";
CM_ SG_ 592 STEERING_RACKPOSITI_YAWCTRL_STPT "It provides the steering rack position setpoint for yaw rate control";
CM_ SG_ 592 STEERING_RACKPOSITION_SETPOINT "It provides the steering rack position setpoint for Yaw Rate or Automatic control.";
CM_ SG_ 592 SBA_TRIGGER "It provides the SBA trigger of the AEB function for assessment of the deceleration requested
";
CM_ SG_ 592 ACC_MOTION_CONTROL_STATE "It provides the state of ACC vehicle motion control by brake/chassis”";
CM_ SG_ 592 E2E_CRC_BSM_DATA_3 "Description : 
DATA_ID =0x00CB
From byte 1 to byte 32(PSA Convention) / DATA_ID = 0x00CB
From byte 1 to byte 32 (PSA Convention)
 / 

Commentaires : 
Please refer to reference specification. / Please refer to reference specification.";
CM_ SG_ 337 CARBODY_LAT_ACCEL_CORRECTED "Calculated Carbody Lateral acceleration based on the IMU Raw value, with the static offset corrected in plant and  with all the dynamic information (including vehicle banking impact, ...).";
CM_ SG_ 337 WHEEL_LONGI_SPEED_CALCUL_FL "it provides the calculated unfiltered speed of the front left wheel";
CM_ SG_ 337 WHEEL_LONGI_SPEED_CALCUL_FR "it provides the calculated unfiltered speed of the front right wheel";
CM_ SG_ 337 WHEEL_LONGI_SPEED_CALCUL_RL "it provides the calculated unfiltered speed of the rear left wheel";
CM_ SG_ 337 WHEEL_LONGI_SPEED_CALCUL_RR "it provides the calculated unfiltered speed of the rear right wheel";
CM_ SG_ 337 CARBODY_LONG_ACCEL_CORRECTED " Calculated Carbody Longitudinal acceleration based on the IMU Raw value, with the static offset corrected in plant and  with all the dynamic information.";
CM_ SG_ 337 CARBODY_YAW_VELOCITY_FILTERED "Calculated Carbody Yaw Velocity based on IMU raw value with the static offset corrected in plant and a permanent high filter to remove the static drifting, and with all the dynamic information (including vehicle banking impact, ...).";
CM_ SG_ 337 VEHICLE_LONGI_ACCEL_CALCULATED "Calculated Vehicle Longitudinal acceleration based on the derivated vehicle speed computed by the wheel speed sensors.";
CM_ SG_ 337 VEHICLE_LONG_SPEED_COMPUTED_VAL "Longitudinal speed of the Vehicle calculated from the wheel speed on the front or rear drive axle depending on the maximum traction level and selected by Proxy (xF approach)";
CM_ SG_ 337 VEHICLE_LONG_SPEED_REFERENCE_VAL "Longitudinal speed of the vehicle calculated by ESC supplier, for powertrain functions management, mainly improved for traction features and AWD road situations";
CM_ SG_ 337 VEHICLE_MOTION_DIRECTION "It provides the direction of vehicle movement
";
CM_ SG_ 337 WHEEL_ROLLING_DIRECTION_FL "direction of motion of the front left wheel";
CM_ SG_ 337 WHEEL_ROLLING_DIRECTION_FR "direction of motion of the front right wheel";
CM_ SG_ 337 WHEEL_ROLLING_DIRECTION_RL "direction of motion of the rear left wheel";
CM_ SG_ 337 WHEEL_ROLLING_DIRECTION_RR "direction of motion of the rear right wheel";
CM_ SG_ 337 WHEEL_ROTATION_PULSE_FL_COUNTER "Pulse counter on the front left wheel (96 counts/rev)";
CM_ SG_ 337 WHEEL_ROTATION_PULSE_FR_COUNTER "Pulse counter on the front right wheel (96 counts/rev)";
CM_ SG_ 337 WHEEL_ROTATION_PULSE_RL_COUNTER "Pulse counter on the right left wheel (96 counts/rev)";
CM_ SG_ 337 WHEEL_ROTATION_PULSE_RR_COUNTER "Pulse counter on the rear right wheel (96 counts/rev)";
CM_ SG_ 337 WHEEL_ROTATION_PULSE_FL_FAIL_STS "Front left wheel pulses counter failure status";
CM_ SG_ 337 WHEEL_ROTATION_PULSE_FR_FAIL_STS "Front right wheel pulses counter failure status";
CM_ SG_ 337 WHEEL_ROTATION_PULSE_RL_FAIL_STS "Rear left wheel pulses counter failure status";
CM_ SG_ 337 WHEEL_ROTATION_PULSE_RR_FAIL_STS "Rear right wheel pulses counter failure status";
CM_ SG_ 337 E2E_ALIVE_BSM_DATA_4_151 " E2E Process Counter for FD14_BSM_DATA_4 frame";
CM_ SG_ 337 E2E_CRC_BSM_DATA_4_151 "Description : 
DATA_ID = 0x00CC
From byte 1 to byte 32(PSA Convention) / DATA_ID = 0x00CC
From byte 1 to byte 32 (PSA Convention)
 / 

Commentaires : 
Please refer to reference specification. / Please refer to reference specification.";
CM_ SG_ 337 BRAKE_STATE "It provides the Brake state of activation (Braking in progress or not) regardless of the requester.
";
CM_ SG_ 337 STOP_LIGHTS_ACTIVATION_REQUEST "rear stop lights activation request";
CM_ SG_ 337 SAFESTOP_BRAKING_STATE " state of the SafeStop function for Brake contribution";
CM_ SG_ 337 BRAKE_PEDAL_PRESSED_STATE "Brake Pedal State";
CM_ SG_ 337 BAS_STATE "It indicates that an BAS regulation is on going";
CM_ SG_ 337 ABS_STATE " ABS regulation is on going";
CM_ SG_ 337 EBD_STATE "indicates that a REF distribution by Braking System is on going";
CM_ SG_ 337 ABS_WHEEL_FRONT_LEFT_STATE "It indicates that an ABS regulation is on going at front left wheel";
CM_ SG_ 337 ABS_WHEEL_FRONT_RIGHT_STATE "It indicates that an ABS regulation is on going at front right wheel";
CM_ SG_ 337 ABS_WHEEL_REAR_LEFT_STATE "It indicates that an ABS regulation is on going at Rear left wheel";
CM_ SG_ 337 ABS_WHEEL_REAR_RIGHT_STATE "It indicates that an ABS regulation is on going at rear right wheel";
CM_ SG_ 337 BRAKE_ASSISTANCE_PRESSURE_VALUE "braking hydraulic pressure generated by driver or automatic function request and after amplification (booster). ";
CM_ SG_ 337 ROAD_SLOPE_ACCURACY_STATE "It provides the accuracy of the road slope estimated";
CM_ SG_ 337 E2E_CRC_BSM_DATA_4_2 "Description : 
DATA_ID = 0x0121
From byte 33 to byte 64(PSA Convention) / DATA_ID = 0x0121
From byte 33 to byte 64 (PSA Convention)
 / 

Commentaires : 
Please refer to reference specification. / Please refer to reference specification.";
CM_ SG_ 337 E2E_ALIVE_BSM_DATA_4_2 " E2E Process Counter for FD14_BSM_DATA_4 frame";
CM_ SG_ 337 EBD_FAILSTATUS "It provides the failure status of the EBD (REF) function, request to turn the telltale ON for example.";
CM_ SG_ 337 ABS_FAILSTATUS "It provides the failure status of the ABS function, request to turn the telltale ON for example.";
CM_ SG_ 2564476661 N_PDU "This signal is used for diagnostic purposes";
CM_ SG_ 2564484085 N_PDU "This signal is used for diagnostic purposes";
CM_ SG_ 2564483829 N_PDU "This signal is used for diagnostic purposes";
CM_ SG_ 2564481781 N_PDU "This signal is used for diagnostic purposes";
CM_ SG_ 2564554485 N_PDU "This signal is used for diagnostic purposes";
CM_ SG_ 2564554482 N_PDU "This signal is used for diagnostic purposes";
CM_ SG_ 2564476658 N_PDU "This signal is used for diagnostic purposes";
CM_ SG_ 2564484082 N_PDU "This signal is used for diagnostic purposes";
CM_ SG_ 2564483826 N_PDU "This signal is used for diagnostic purposes";
CM_ SG_ 2564481778 N_PDU "This signal is used for diagnostic purposes";
CM_ SG_ 2564486606 N_PDU "This signal is used for diagnostic purposes";
CM_ SG_ 2564486635 N_PDU "This signal is used for diagnostic purposes";
CM_ SG_ 2564486634 N_PDU "This signal is used for diagnostic purposes";
CM_ SG_ 2564486626 N_PDU "This signal is used for diagnostic purposes";
CM_ SG_ 2564485838 N_PDU "This signal is used for diagnostic purposes";
CM_ SG_ 2564485867 N_PDU "This signal is used for diagnostic purposes";
CM_ SG_ 2564485866 N_PDU "This signal is used for diagnostic purposes";
CM_ SG_ 2564485858 N_PDU "This signal is used for diagnostic purposes";
CM_ SG_ 2564682219 N_PDU "This signal is used for diagnostic purposes";
CM_ SG_ 2564682218 N_PDU "This signal is used for diagnostic purposes";
CM_ SG_ 2564682210 N_PDU "This signal is used for diagnostic purposes";
CM_ SG_ 340 STEERING_ASSIST_FAILSTATUS "failure status of the steering system";
CM_ SG_ 340 STEERING_ASSIST_STATUS " functional state of the Steering system";
CM_ SG_ 340 STEERING_POWERSUPPLY_BOOST_REQ "steering system request for a power supply boost";
CM_ SG_ 340 LKA_STEERING_ACTUATION_STATE "state of torque actuation for the LKA function from a steering system";
CM_ SG_ 340 LKA_STEERING_AVAILABILITY_STATE "ynthesis of steering system availability for the LKA function";
CM_ SG_ 340 LXA_STEERING_LIMITATION_STATE "State of torque limitation for the LxA function from Steering System.";
CM_ SG_ 340 LXA_STEERING_STATE "EPS/SBW LxA status.";
CM_ SG_ 340 STEERINGWHEEL_ANGLE_CAL_FRT_STS " learning status of the front steering wheel angle whatever the type is Absolute or Relative";
CM_ SG_ 340 STEERINGWHEEL_ANGLE_REL_FRT_STE "Steering System request to Brake System to know if Brake System Offset calculator is ready. Validated back by Brake System acknowledgement.";
CM_ SG_ 340 STEERINGWHEEL_ANGLE_FRONT_TYPE "Type of technology for front steering wheel angle information production.";
CM_ SG_ 340 HANDWHEEL_STEERING_TRQ_MEASURED " Steering Column Torque applied and measured at the steering actuator level";
CM_ SG_ 340 LXA_STEERING_TORQUE_ADDON_VALUE "torque add on value for the LxA rack position control";
CM_ SG_ 340 HANDWHEEL_STEERING_ANGLE_VALUE " Handwheel rotation angle applied by the drive.
Only for Steering By Wire";
CM_ SG_ 340 STEERINGWHEEL_ANGLE_FRT_ACCURACY "accuracy of the Steering Wheel Angle";
CM_ SG_ 340 STEERINGWHEEL_ANGLE_FRONT_VAL "Front steering wheel angle (absolute value or Relative value corrected). Counterclockwise positive.";
CM_ SG_ 340 STEERINGWHEEL_ANGLE_REL_FRT_VA "Front relative steering wheel angle with no correction (raw).";
CM_ SG_ 340 WHEEL_STEERINGANGLE_FRONT_VAL "Average front wheels steering angle calculated by extrapolation of rack position (bicycle model calibration in Steering System).";
CM_ SG_ 340 STEERINGWHEEL_ROT_VELOCITY_FRT "Front steering wheel velocity angle (Absolute value or Relative value corrected).";
CM_ SG_ 340 E2E_CRC_EPS_DATA_1 "Description : 
DATA_ID = 0x00D5
From byte 1 to byte 32(PSA Convention) / DATA_ID = 0x00D5
From byte 1 to byte 32 (PSA Convention)
 ";
CM_ SG_ 340 E2E_ALIVE_EPS_DATA_1 " E2E Process Counter for FD14_EPS_DATA_1 frame";
CM_ SG_ 596 STEERING_RACK_POSITION_VALUE "Estimated absolute value of the steering rack position.";
CM_ SG_ 596 E2E_ALIVE_EPS_DATA_2 " E2E Process Counter for FD14_EPS_DATA_2 frame";
CM_ SG_ 596 E2E_CRC_EPS_DATA_2 "Description : 
DATA_ID = 0x00D6
From byte 1 to byte 32(PSA Convention) / DATA_ID = 0x00D6
From byte 1 to byte 32 (PSA Convention)
 ";
CM_ SG_ 1406 ECU_CODE "Description : 
DATA_ID = Not applicable 
 
Code station / ECU code

Commentaires : 
0 / 0";
CM_ SG_ 1406 RELEVANCE_OF_DATE "Description : 
DATA_ID = Not applicable 
 
Pertinence de l'information date bit (b2) pour les message evenements defaut 2010 / Relevance of the Date information \" bit (b2) for the 2010 Fault Event Message

Commentaires : 
0 / 0";
CM_ SG_ 1406 NM_Frames "Number of The frames";
CM_ SG_ 1406 Status_DTC "Default state";
CM_ SG_ 1406 Fault_Code "The default encoding is:
The fault code conforms to SAE J2012:
Octet 1 : MSB,
Octet 2 : LSB (for KWP),
Octet 3 : LSB (for UDS), 0x00 (for KWP)";
CM_ SG_ 1406 DTC_Format_Identifier "DTC_Format";
CM_ SG_ 1406 KM_DEH "Absolute distance is done by the vehicle";
CM_ SG_ 1406 Absolute_Defect_Event_Year "Year";
CM_ SG_ 1406 Absolute_Defect_Event_Month "Month";
CM_ SG_ 1406 Absolute_Defect_Event_Day "Day";
CM_ SG_ 1406 Absolute_Defect_Event_Hour "Hour";
CM_ SG_ 1406 Absolute_Defect_Event_Minute "Minute";
CM_ SG_ 1406 Absolute_Defect_Event_Second "Second";
CM_ SG_ 1406 Abs_Defect_Event_Tenth_Of_Sec "tenth of second";
CM_ SG_ 951 ACC_MODE_CHOICE_REQ "ACC/NCC choice";
CM_ SG_ 951 ACC_AVAILABILITY_FOR_SWITCH "ACC availability for ACC/NCC switch";
CM_ SG_ 951 ACC_TAKEOVER_REQUEST "Take over request to the driver following failure";
CM_ SG_ 951 BLINDSPOTDETECTION_DRIVERREQUEST "Specifies the status of Blind Spot Detection function activation request";
CM_ SG_ 951 MAIN_LONGITUDINAL_STINFO "Comfort Longitudinal Control State";
CM_ SG_ 951 WPP_DRIVER_INHIBITION_REQUEST "Driver request to enable/inhibit WPP";
CM_ SG_ 951 AEB_HMI_READY "HMI Authorisation to run AEB from a cockpit standpoint";
CM_ SG_ 951 FCW_HMI_READY "HMI Authorisation to run FCW from a cockpit standpoint";
CM_ SG_ 951 FCW_HMI_SETTING "Customer selection of sensitivity for FCW from HMI system";
CM_ SG_ 951 E2E_CRC_HPC_DATA_1 "Description : 
DATA_ID = 0x0100
From byte 1 to byte 32(PSA Convention) / DATA_ID = 0x0100
From byte 1 to byte 32 (PSA Convention)
 / 
";
CM_ SG_ 951 E2E_ALIVE_HPC_DATA_1 " E2E Process Counter for FD15_HPC_DATA_1 frame";
CM_ SG_ 951 AEB_HMI_LIMITATION "Limitation request of AEB deceleration from
 cockpit";
CM_ SG_ 951 LONGITUDINAL_SPEED_SETPOINT "ACC speed setpoint";
CM_ SG_ 951 ELKS_SELECTION_REQ "Description:
User ELKS selection request status";
CM_ SG_ 951 FCW_SETTING "Flow to communicate the distance setting for FCW";
CM_ SG_ 951 LRCF_CANCEL_REQ "Request for LRCF Update Cancellation";
CM_ SG_ 951 LRCF_DCTYPE "Inform about the type of the DC";
CM_ SG_ 951 LRCF_NUMBEROFDC "Inform about the number of DCs";
CM_ SG_ 951 LRCF_TRANSFER_READINESS_REQ "Indicate that there is PackageAvailable to transfert and request if the ECU is ready to start the transfert";
CM_ SG_ 951 LPA_STATE_INFO "Indicates the current state of the LPA";
CM_ SG_ 951 VHL_DL_OR_TX_ACTIVE "To inform about the start of the download or transfert phase
";
CM_ SG_ 951 OTA_UPDATE_STATUS "Providing status for OTA update 
";
CM_ SG_ 951 ELKS_COCKPIT_FAILURE "ELKS cockpit failure
";
CM_ SG_ 951 ALERT_SOUND_LOCALIZATION "Localization of sound requested";
CM_ SG_ 951 ALERT_SOUND_LEVEL "level of sound requested";
CM_ SG_ 951 ALERT_SOUND_NUMBER "represents the number of sound to play";
CM_ SG_ 951 SL_SPEED_SETPOINT_DUA "speed limiter speed setpoint Duaplicated";
CM_ SG_ 951 SL_ACTIVATION_REQUEST "It indicates the state of SL function
";
CM_ SG_ 951 CC_ACTIVATION_REQUEST "Cruise Control activation request
";
CM_ SG_ 951 CC_SPEED_SETPOINT_DUA "speed limiter speed setpoint Duaplicated";
CM_ SG_ 951 REGULATION_LONGI_TYPE "it indicates which type is the longitudinal regulation";
CM_ SG_ 951 LPA_ST_INFO "0: Inhibited 1: Waiting 2: Active 3: Defect";
CM_ SG_ 951 DDMS_STATE "0: Unavailable
1: DMS_INITIALIZATION
2: DMS_UNSELECTED
3: DMS_FULLY_OPERATIONAL
4: DMS_OPERATIONAL_FROZEN
5: DMS_OPERATIONAL_DEGRADED
6: DMS_FAULT
7: RESERVED";
CM_ SG_ 951 DDMS_FOV_AREA "0: Unavailable
1: TSA
2:DRTA
3: NDRTA
4: RESERVED_1
5: RESERVED_2
6: RESERVED_3
7: INVALID";
CM_ SG_ 951 DDMS_EYE_STATUS "0: Unavailable
1: OpenEyesDetected
2:ClosedEyesDetected
3: MicroSleepDetected
4: SleepDetected
5: RESERVED_1
6: RESERVED_2
7: INVALID";
CM_ SG_ 951 DDMS_DROWSINESS_LEVEL "0: Unavailable
1: Level1
2:Level2
3:Level3
4: Level4
5: RESERVED_1
6: RESERVED_2
7: INVALID";
CM_ SG_ 951 DDMS_DISTRACTION_LEVEL "0: Unavailable
1: Level1
2:Level2
3:Level3
4: Level4
5: RESERVED_1
6: RESERVED_2
7: INVALID";
CM_ SG_ 951 DDM_SAFETY_MODE_REQUEST "0: NotRequested
1: RequestedDueToDistraction
2: RequestedDueToDrowsiness
3: RESERVED";
CM_ SG_ 1719 ACC_TIV_SETPOINT "ACC TIV setpoint";
CM_ SG_ 1719 COUNTRY_CODE_MERGED "Country code";
CM_ SG_ 1719 ACC_SPEED_SET_POINT "ACC speed setpoint";
CM_ SG_ 633 ACC_STATE_INFO_FOR_CHASSIS "FT0 state to control FT2's VMC Inactive : 0 Active : 1 ActiveBrakeOnly : 2 ActiveStandstill : 3";
CM_ SG_ 633 PACC_ACCEL_LONGI_REQUEST "PACC acceleration set point";
CM_ SG_ 633 PACC_BEVENT_IN_PROGRESS "PACC acceleration request flag";
CM_ SG_ 633 GPAC_BINHIB_ACCEL_BEND_REQ "Deactivation of ACC bend strategy when the PACC is regulating";
CM_ SG_ 633 PACC_POTACCEL_LONGI_REQUEST "Acceleration setpoint requested by the vehicle";
CM_ SG_ 1154 IHM_R2_POSITION "Longitudinal position of Target R2 object based on 64 positions scale of the second target on the right side lane";
CM_ SG_ 1154 FRONTCAM_EGO_OBJ_TYPE "Classification of the ego objects target";
CM_ SG_ 1154 FRONTCAM_EGO2_OBJ_TYPE "Classification of the second objects target on the ego lane";
CM_ SG_ 1154 FRONTCAM_L1_OBJ_TYPE "Classification of the first target on the left side lane";
CM_ SG_ 1154 FRONTCAM_L2_OBJ_TYPE "Classification of the second target on the left side lane";
CM_ SG_ 1154 FRONTCAM_L3_OBJ_TYPE "Classification of the third target on the left side lane";
CM_ SG_ 1154 FRONTCAM_R1_OBJ_TYPE "Classification of the first target on the right side lane";
CM_ SG_ 1154 FRONTCAM_R2_OBJ_TYPE "Classification of the second target on the right side lane";
CM_ SG_ 1154 FRONTCAM_R3_OBJ_TYPE "Classification of the third  target on the right side lane";
CM_ SG_ 1154 FRONTCAM_EGO_OBJ_CONFID_OBJ "Confidence of Target Front object measured";
CM_ SG_ 1154 FRONTCAM_EGO2_OBJ_CONFID_OBJ "Confidence of Second Target Front object measured";
CM_ SG_ 1154 FRONTCAM_L1_OBJ_CONFID_OBJ "Confidence of Target L1 object measured";
CM_ SG_ 1154 FRONTCAM_L2_OBJ_CONFID_OBJ "Confidence of Target L2 object measured";
CM_ SG_ 1154 FRONTCAM_L3_OBJ_CONFID_OBJ "Confidence of Target L3 objectmeasured";
CM_ SG_ 1154 FRONTCAM_R1_OBJ_CONFID_OBJ "Confidence of Target R1 object measured";
CM_ SG_ 1154 FRONTCAM_R2_OBJ_CONFID_OBJ "Confidence of Target R2 object measured";
CM_ SG_ 1154 FRONTCAM_R3_OBJ_CONFID_OBJ "Confidence of Target R3 object  measured";
CM_ SG_ 1154 FRONTCAM_EGO_OBJ_LAT_DISTANCE "Lateral distance of the Target Front with respect to the Forward-Facing Camera coordinate system";
CM_ SG_ 1154 FRONTCAM_EGO2_OBJ_LAT_DISTANCE "Lateral distance of the Second Target Front  with respect to the Forward-Facing Camera coordinate system";
CM_ SG_ 1154 FRONTCAM_L1_OBJ_LAT_DISTANCE "Lateral distance of the Target L1 object with respect to the Forward-Facing Camera coordinate system";
CM_ SG_ 1154 FRONTCAM_L2_OBJ_LAT_DISTANCE "Lateral distance of the Target L2 object with respect to the Forward-Facing Camera coordinate system";
CM_ SG_ 1154 FRONTCAM_L3_OBJ_LAT_DISTANCE "Lateral distance of the Target L3 object with respect to the Forward-Facing Camera coordinate system";
CM_ SG_ 1154 FRONTCAM_R1_OBJ_LAT_DISTANCE "Lateral distance of the Target R1 object with respect to the Forward-Facing Camera coordinate system";
CM_ SG_ 1154 FRONTCAM_R2_OBJ_LAT_DISTANCE "Lateral distance of the Target R2 object with respect to the Forward-Facing Camera coordinate system";
CM_ SG_ 1154 FRONTCAM_R3_OBJ_LAT_DISTANCE "Lateral distance of the Target R3 object with respect to the Forward-Facing Camera coordinate system";
CM_ SG_ 1154 FRONTCAM_EGO_OBJ_LONGI_REL_SPD "Relative longitudinal velocity of measured Target Front with respect to host vehicle";
CM_ SG_ 1154 FRONTCAM_EGO2_OBJ_LONGI_REL_SPD "Relative longitudinal velocity of measured  Second Target Front  with respect to host vehicle";
CM_ SG_ 1154 FRONTCAM_L1_OBJ_LONGI_REL_SPD "Relative longitudinal velocity of measured Target L1 Front  with respect to host vehicle";
CM_ SG_ 1154 FRONTCAM_L2_OBJ_LONGI_REL_SPD "Relative longitudinal velocity of measured Target L2 Front  with respect to host vehicle";
CM_ SG_ 1154 FRONTCAM_L3_OBJ_LONGI_REL_SPD "Relative longitudinal velocity of measured Target L3 Front  with respect to host vehicle";
CM_ SG_ 1154 FRONTCAM_R1_OBJ_LONGI_REL_SPD "Relative longitudinal velocity of measured Target R1 Front  with respect to host vehicle";
CM_ SG_ 1154 FRONTCAM_R2_OBJ_LONGI_REL_SPD "Relative longitudinal velocity of measured Target R2 with respect to host vehicle";
CM_ SG_ 1154 FRONTCAM_R3_OBJ_LONGI_REL_SPD "Relative longitudinal velocity of measured Target R3 with respect to host vehicle";
CM_ SG_ 1154 FRONTCAM_L2_OBJ_LAT_REL_SPD "Relative lateral velocity of Measured Target L2 Front with respect to host vehicle";
CM_ SG_ 1154 FRONTCAM_L3_OBJ_LAT_REL_SPD "Relative lateral velocity of Measured Target L3  Front  with respect to host vehicle";
CM_ SG_ 1154 FRONTCAM_R1_OBJ_LAT_REL_SPD "Relative lateral velocity of Measured Target R1 Front with respect to host vehicle";
CM_ SG_ 1154 FRONTCAM_R2_OBJ_LAT_REL_SPD "Relative lateral velocity of Measured Target R2 Front  with respect to host vehicle";
CM_ SG_ 1154 FRONTCAM_R3_OBJ_LAT_REL_SPD "Relative lateral velocity of Measured Target R3 Front  with respect to host vehicle";
CM_ SG_ 1154 FRONTCAM_EGO_OBJ_HANDLE "Track ID for the Target Front";
CM_ SG_ 1154 FRONTCAM_EGO2_OBJ_HANDLE "Track ID for the Second Target Front";
CM_ SG_ 1154 FRONTCAM_L1_OBJ_HANDLE "Track ID for the Target L1";
CM_ SG_ 1154 FRONTCAM_L2_OBJ_HANDLE "Track ID for the Target L2";
CM_ SG_ 1154 FRONTCAM_L3_OBJ_HANDLE "Track ID for the Target L3";
CM_ SG_ 1154 FRONTCAM_R1_OBJ_HANDLE "Track ID for the Target R1";
CM_ SG_ 1154 FRONTCAM_R2_OBJ_HANDLE "Track ID for the Target R2";
CM_ SG_ 1154 FRONTCAM_R3_OBJ_HANDLE "Track ID for the Target R3";
CM_ SG_ 1154 IHM_EGO_POSITION "Longitudinal position of Target Front object based on 64 positions scale of the first  target on the ego lane";
CM_ SG_ 1154 IHM_L1_POSITION "Longitudinal position of Target L1 object based on 64 positions scale of the first  target on the left side lane";
CM_ SG_ 1154 IHM_L2_POSITION "Longitudinal position of Target L2 object based on 64 positions scale of the second  target on the left side lane";
CM_ SG_ 1154 IHM_R1_POSITION "Longitudinal position of Target R1 object based on 64 positions scale of the first  target on the right side lane";
CM_ SG_ 661 FCAM_VRU4_TYPE "Classification of the fourth VRU";
CM_ SG_ 661 FCAM_VRU5_TYPE "Classification of the fifth VRU";
CM_ SG_ 661 FCAM_VRU1_TYPE "Classification of the first VRU";
CM_ SG_ 661 FCAM_VRU2_TYPE "Classification of the second VRU";
CM_ SG_ 661 FCAM_VRU3_TYPE "Classification of the third VRU";
CM_ SG_ 661 FCAM_VRU4_LONG_DIST "Longitudinal distance of the fourth VRU";
CM_ SG_ 661 FCAM_VRU2_LONG_DIST "Longitudinal distance of the second VRU";
CM_ SG_ 661 FCAM_VRU3_LAT_DIST "Lateral distance of the third VRU";
CM_ SG_ 661 FCAM_VRU5_LAT_DIST "Lateral distance of the fifth VRU";
CM_ SG_ 661 FCAM_VRU1_LONG_DIST "Longitudinal distance of the first VRU";
CM_ SG_ 661 FCAM_VRU3_LONG_DIST "Longitudinal distance of the third VRU";
CM_ SG_ 661 FCAM_VRU5_LONG_DIST "Longitudinal distance of the fifth VRU";
CM_ SG_ 661 FCAM_VRU1_LAT_DIST "Lateral distance of the first VRU";
CM_ SG_ 661 FCAM_VRU2_LAT_DIST "Lateral distance of the second VRU";
CM_ SG_ 661 FCAM_VRU4_LAT_DIST "Lateral distance of the forth VRU";
CM_ SG_ 661 EGO_DIR_ROAD_LANENUMBER "Road lane number in the same direction of EGO";
CM_ SG_ 661 FCAM_LEFTRIGHT_CONFIDENCE_MEA "The confidence indicates the probability that the lane mark actually exists";
CM_ SG_ 661 FCAM_LEFTRIGHT_LINE_DIS_ACTUAL "Distance: Center of the vehicle to inner edge 
of the road's LeftRight line (Polynomial C0)";
CM_ SG_ 661 FCAM_LEFTRIGHT_LINE_LAT_DIST "Lateral distance of the LeftRight (considering the inner part of the line) line with respect to the Forward-Facing Camera coordinate system";
CM_ SG_ 661 FCAM_LEFTRIGHT_LINECOLOR "Color of the LeftRight line";
CM_ SG_ 661 FCAM_LEFTRIGHT_LINECURVATURE_EST "Estimated curvature of LeftRight line marking (Polynomial C2, unit: 1/m)";
CM_ SG_ 661 FCAM_LEFTRIGHT_LINECURVATURE_DER "Derivative of LeftRight line marking curvature 
(Polynomial C3, unit: 1/m^2)";
CM_ SG_ 661 FCAM_LLANE_ROADEDG_CURVATURE_DER "Derivative of left lane roadedge  marking curvature 
(Polynomial C3, unit: 1/m^2)";
CM_ SG_ 661 FCAM_RIGHTLEFT_LINECURVATURE_DER "Derivative of RightLeft line marking curvature 
(Polynomial C3, unit: 1/m^2)";
CM_ SG_ 661 FCAM_RLANE_ROADEDG_CURVATURE_DER "Derivative of  right roadedge marking curvature 
(Polynomial C3, unit: 1/m^2)";
CM_ SG_ 661 FCAM_LLANE_ROADEDG_CURVATURE_EST "Estimated curvature of left lane roadedge (Polynomial C2, unit: 1/m)";
CM_ SG_ 661 FCAM_RIGHTLEFT_LINECURVATURE_EST "Estimated curvature of RightLeft line marking (Polynomial C2, unit: 1/m)";
CM_ SG_ 661 FCAM_RLANE_ROADEDG_CURVATURE_EST "Estimated curvature of  right roadedge marking (Polynomial C2, unit: 1/m)";
CM_ SG_ 661 FCAM_LLANE_ROADEDG_DIST_ACTUAL "Front camera center to inner edge left roadedge (C0 parameter of line equation)";
CM_ SG_ 661 FCAM_RIGHTLEFT_LINE_DIST_ACTUAL "Distance: Center of the vehicle to inner edge 
of the road's LeftRight line (Polynomial C0)";
CM_ SG_ 661 FCAM_RLANE_ROADEDG_DIST_ACTUAL "Front camera center to inner edge left roadedge (C0 parameter of line equation)";
CM_ SG_ 661 FCAM_LEFTRIGHT_LINEHEADINGANGLE "C1: Heading angle of vehicle with the LeftRight line 
(angle between vehicle direction and lane limit direction, unit: ° (deg))";
CM_ SG_ 661 FCAM_LLANE_ROADEDG_HEADINGANGLE "C1: Heading angle of vehicle with the left lane roadedge 
(angle between vehicle direction and lane limit direction, unit: ° (deg))";
CM_ SG_ 661 FCAM_RIGHTLEFT_LINEHEADINGANGLE "C1: Heading angle of vehicle with the  RightLeft line
(angle between vehicle direction and lane limit direction, unit: ° (deg))";
CM_ SG_ 661 FCAM_RLANE_ROADEDG_HEADINGANGLE "C1: Heading angle of vehicle with the  right roadedge
(angle between vehicle direction and lane limit direction, unit: ° (deg))";
CM_ SG_ 661 FCAM_RIGHTLEFT_LINE_LAT_DIST "Lateral distance of the RightLeft (considering the inner part of the line) line with respect to the Forward-Facing Camera coordinate system";
CM_ SG_ 661 FCAM_LEFTRIGHT_LINEVIEW_RANGEEND "LeftRight host lane’s line marking View Range ends  at this distance";
CM_ SG_ 661 FCAM_LEFTRIGHT_LINEVIEW_RANGESTR "LeftRight host lane’s line marking View Range starts at this distance";
CM_ SG_ 661 FCAM_LLANE_ROADEDG_CONFIDENC_MEA "The confidence indicates the probability that the lane mark actually exists";
CM_ SG_ 661 FCAM_LLANE_ROADEDG_VIEW_RANGEEND "Left roadedge marking View Range ends  at this distance";
CM_ SG_ 661 FCAM_LLINE_CONFIDENCE_MEA "The confidence indicates the probability that the lane mark actually exists";
CM_ SG_ 661 FCAM_NEXTLEFTLINE_CONFIDENCE_MEA "The confidence indicates the probability that the lane mark actually exists";
CM_ SG_ 661 FCAM_NEXTRIGHTLINE_CONFIDENC_MEA "The confidence indicates the probability that the lane mark actually exists";
CM_ SG_ 661 FCAM_RIGHTLEFT_CONFIDENCE_MEA "The confidence indicates the probability that the lane mark actually exists";
CM_ SG_ 661 FCAM_RLANE_ROADEDG_CONFIDENC_MEA "The confidence indicates the probability that the lane mark actually exists";
CM_ SG_ 661 FCAM_RLANE_ROADEDG_VIEW_RANGEEND "Left roadedge marking View Range ends  at this distance";
CM_ SG_ 661 FCAM_RLINE_CONFIDENCE_MEA "The confidence indicates the probability that the lane mark actually exists";
CM_ SG_ 661 FCAM_LEFTRIGHT_LINEDETECTIONSTS "Validity-flag for detection of the road's next right line 
according to line history, contrast, lane coherence, 
view range, camera-state and lane width changes";
CM_ SG_ 661 FCAM_LEFTRIGHT_LINEMARKERQUALITY "The lane mark can be detected, predicted or unavailable. The lane mark is considered predicted only if no segment is detected from the image.";
CM_ SG_ 661 FCAM_LEFTRIGHT_LINETYPE "This signal indicates the type of the LeftRight  ego line marking ";
CM_ SG_ 661 FCAM_RIGHTLEFT_LINETYPE "This signal indicates the type of the RightLeft ego line marking ";
CM_ SG_ 661 FCAM_RIGHTLEFT_LINEDETECTIONSTS "Validity-flag for detection of the road's next right line 
according to line history, contrast, lane coherence, 
view range, camera-state and lane width changes";
CM_ SG_ 661 FCAM_RIGHTLEFT_LINECOLOR "Color of the RightLeft line";
CM_ SG_ 661 FCAM_LLANE_ROADEDG_MARKERQUALITY "The lane mark can be detected, predicted or unavailable. The lane mark is considered predicted only if no segment is detected from the image.";
CM_ SG_ 661 FCAM_RIGHTLEFT_LINEMARKERQUALITY "The lane mark can be detected, predicted or unavailable. The lane mark is considered predicted only if no segment is detected from the image.";
CM_ SG_ 661 FCAM_RLANE_ROADEDG_MARKERQUALITY "The lane mark can be detected, predicted or unavailable. The lane mark is considered predicted only if no segment is detected from the image.";
CM_ SG_ 661 FCAM_LLANE_ROADEDG_DET_STATUS "Validity-flag for detection of the road's  left roadedge
according to line history, contrast, lane coherence, 
view range, camera-state and lane width changes";
CM_ SG_ 661 FCAM_LLANE_ROADEDG_VIEW_RANSTART "left RoadEdge marking View Range starts at this distance";
CM_ SG_ 661 FCAM_RLANE_ROADEDG_VIEW_RANSTART "Next RoadEdge marking View Range starts at this distance";
CM_ SG_ 661 FCAM_LLANE_ROADEDGETYPE "Type of the Left Line roadedge  : 
Flat =  transition from asphalt to grass or gravel
Elevated_Structure =Higher objects like road bariers)
Curb : Generally curbs with different colors and sizes
Cones_poles : All kinds of road cones
Parking_cars=Cars parked in a line on the side of the road
No_Roadegde";
CM_ SG_ 661 FCAM_LLINE_VALIDFORLKA "A binary indication, provides guidance on whether the lane boundary can be use for LKA application
For safety cases such as LKA, this is the recommended signal to use. When the flag is false, the lane should be ignored. For comfort applications, for example HMI, the lanes can still be used even if the flag is false.";
CM_ SG_ 661 FCAM_RIGHTLEFT_LINEVIEW_RANGEEND "RightLeft host lane’s line marking View Range ends  at this distance";
CM_ SG_ 661 FCAM_RIGHTLEFT_LINEVIEW_RANGESTR "RightLeft host lane’s line marking View Range starts at this distance";
CM_ SG_ 661 FCAM_OBJECTCROSSING "This flow indicates the change of the reference for the object when the ego made a change of lane.";
CM_ SG_ 661 FCAM_RLANE_ROADEDG_DET_STATUS "Validity-flag for detection of the road's right roadedge
according to line history, contrast, lane coherence, 
view range, camera-state and lane width changes";
CM_ SG_ 661 FCAM_RLANE_ROADEDGETYPE "Type of the Right$t Line roadedge  : 
Flat =  transition from asphalt to grass or gravel
Elevated_Structure =Higher objects like road bariers)
Curb : Generally curbs with different colors and sizes
Cones_poles : All kinds of road cones
Parking_cars=Cars parked in a line on the side of the road
No_Roadegde";
CM_ SG_ 661 FCAM_RLINE_VALIDFORLKA "A binary indication, provides guidance on whether the lane boundary can be use for LKA application For safety cases such as LKA, this is the recommended signal to use. When the flag is false, the lane should be ignored. For comfort applications, for example HMI, the lanes can still be used even if the flag is false.";
CM_ SG_ 641 AEB_STATE_A "ADAS state of AEB state machine";
CM_ SG_ 641 ADAS_LONGI_ACCEL_REQUEST "Acceleration level requested by ADAS for AEB (after arbitration with ACC...)";
CM_ SG_ 641 E2E_ALIVE_LRCF_DATA_2 " E2E Process Counter for FD15_LRCF_DATA_2 frame";
CM_ SG_ 641 E2E_CRC_LRCF_DATA_2 "Description : 
DATA_ID = 0x00DE
From byte 1 to byte 32(PSA Convention) / DATA_ID = 0x00DE
From byte 1 to byte 32 (PSA Convention)
 / 
";
CM_ SG_ 641 YAW_RATE_REQUEST_SETPOINT "Yaw rate speed °/s";
CM_ SG_ 641 DST_WIDTH_EGO_LINE "Decription:
Width of the ego line at X=0";
CM_ SG_ 641 ACTIVATED_LATERAL_ASSIST_MODE "Description:
";
CM_ SG_ 641 PERCEPTION_SYSTEM_STATE "Description:
Perception state (sensing) of objects in front area of the ego vehicle";
CM_ SG_ 641 PERCEPTION_STATE "Description:
Perception state (sensing) of road geometry in front of the ego vehicle.";
CM_ SG_ 641 ACC_POTENTIAL_ACCELERATION_REQ "Potential acceleration requested by the vehicle";
CM_ SG_ 641 ACC_JERK_MIN_SETPOINT "Min of Longitudinal Jerk";
CM_ SG_ 1153 AEB_LIMITED "ADAS Request to illuminate AEB Telltale, as AEB works with certain limitation";
CM_ SG_ 1153 FCW2_REQUEST "ADAS Request for acoustic and visual forward collision alert (AEB)";
CM_ SG_ 1153 FRONT_CAMERA_BLIND "ADAS Request for HMI to clean front camera";
CM_ SG_ 1153 FRONT_RADAR_BLIND "ADAS Request for HMI to clean front radar";
CM_ SG_ 1153 HMI_AEB_BRAKING_ACTIVE "ADAS Request to flash AEB Telltale during AEB braking";
CM_ SG_ 1153 FCW2_SIDEALERT "ADAS Request for the sound location for forward collision alert";
CM_ SG_ 1153 FCW_STATE_A "ADAS state of FCW state machine";
CM_ SG_ 1153 EBF_ACCELERATION_TYPE "state of Longitidunal control  ouput of ArbitrateLongitudinalCommand";
CM_ SG_ 1153 E2E_CRC_LRCF_DATA_3 "Description : 
DATA_ID = 0x0112
From byte 1 to byte 32(PSA Convention) / DATA_ID = 0x0112
From byte 1 to byte 32 (PSA Convention)
 / 
";
CM_ SG_ 1153 E2E_ALIVE_LRCF_DATA_3 " E2E Process Counter for FD14_HPC_DATA_7 frame";
CM_ SG_ 1153 FCW1_TARGET_PRESENT "Internal boolean flow to determine FCW1 target is selected
";
CM_ SG_ 1153 AEB_HAPTIC_CRITICAL "Internal boolean flow determining Haptic Critical condition for AEB";
CM_ SG_ 1153 AEB_DETECTION_LIMITED "Inform the driver about a limitation of the detection capability of the primary AEB sensor due to weather conditions";
CM_ SG_ 1153 DATA_TRANSFER_STATUS "LRCF Communicate the Status of the transfer
";
CM_ SG_ 1153 ERROR_TYPE "To indicate potentially the nature of Error";
CM_ SG_ 1153 READINESS_STATUS "LRCF Autorise or not the start of Transfer";
CM_ SG_ 1153 ERROR_REASON "To indicate if fatale error or not, and put potentially the nature of Error
";
CM_ SG_ 1153 SAFETY_LRCF_READY_STATE "Installation readiness response after FotaSafeState conditions checkup";
CM_ SG_ 1153 LRCF_UPDATE_STATUS "Functional flow to report the update status of the Big target ECU";
CM_ SG_ 1409 LKA_STATE "Description : 
Etat global de la fonction LKA / General state of LKA function

Commentaires : 
0 / 0";
CM_ SG_ 1409 RCTA_STATE "Description : 
State of the RCTA function / State of the RCTA function
 / 

Commentaires : 
0 / 0";
CM_ SG_ 1409 BLINDSPOT_DETECTION_STATUS "Blind Spot State ";
CM_ SG_ 1409 BLINDSPOTDETECTIONLEFTALERTRQST "Obstacle presence detected on the left";
CM_ SG_ 1409 BLINDSPOTDETECTIONRIGHTALERTRQST "Obstacle presence detected on the right";
CM_ SG_ 1409 FRONT_CAMERA_SPEED_LIMIT "Current Speed Limit";
CM_ SG_ 1409 FRONT_CAMERA_TRAFFIC_SIGN_DIST "Sends out traffic sign relevant for customer (no sign, no entry, stop, yield, overtaking forbidden, overtaking allowed)";
CM_ SG_ 1409 FRONT_CAMERA_SPEED_LIMIT_AGE "Distance in meters since last conditional sign";
CM_ SG_ 1409 FRONT_CAMERA_CONDSPEED_LIMIT_AGE "Distance in meters since last conditional sign";
CM_ SG_ 1409 FRONT_CAMERA_TRAFFICSIGN_RAW "Sends out the traffic sign after passing, e.g. highway entry, pedestrian crossing, … (ME sign list) (for 3 frames)";
CM_ SG_ 1409 FRONT_CAMERA_TRAFFICSIGN_RAW_SUP "Sends out the supplementary traffic sign after passing, e.g. highway entry, pedestrian crossing, … (ME sign list)";
CM_ SG_ 1409 FRONT_CAMERA_ROAD_TYPE_RAW "Road Type information from MobilEye";
CM_ SG_ 1409 LONGITUDINAL_DRIVING_STINFO "Indicate ADCAM's ACC Status";
CM_ SG_ 1409 LAS_INTERRUPT_ALERT "Description:
Indicates, when LKA/ELK has been interrupted due to certain events and therefore requests a popup in the HMI";
CM_ SG_ 1409 LAS_DRIVER_CONTROL_ALERT "Description:
Requests a hands-off alert";
CM_ SG_ 1409 HIGH_BEAM_ASSIST_CONDITION "Define if high beam can be requested by the camera depending on luminosity, weather and speed.";
CM_ SG_ 1409 HIGH_BEAM_ASSIST_FAULT "Indicates if an internal failure is present";
CM_ SG_ 1409 LIGHTED_ZONE_DETECTED "Indicates the presence of the host vehicle in a lit area.";
CM_ SG_ 1409 LAS_FRONT_SENSOR_BLOCKAGE_STATUS "Indicates if the LAS front sensor is blocked";
CM_ SG_ 1409 LAS_REAR_SENSOR_BLOKAGE_STS "Description:
Indicates if the the rear sensor is blocked so that LAS cannot operate
";
CM_ SG_ 1409 LAS_HAPTIC_ALERT_REQ "Description:
The ADAS request for a haptic warning request for LAS (calibratable)";
CM_ SG_ 1409 E2E_CRC_LRCF_DATA_4 "Description : 
DATA_ID = 0x011F
From byte 1 to byte 32(PSA Convention) / DATA_ID = 0x011F
From byte 1 to byte 32 (PSA Convention)
 / 
";
CM_ SG_ 1409 E2E_ALIVE_LRCF_DATA_4 " E2E Process Counter for FD14_LRCF_DATA_4 frame";
CM_ SG_ 1409 VRU_IN_EXTENDED_FRONT_AREA "This signal indicates if a VRU is detected on Extended_Front_Area";

BA_DEF_ SG_ "Accuracy" STRING ;
BA_DEF_ SG_ "Event trans." ENUM "Yes","No";
BA_DEF_ SG_ "GenSigStartValue" INT 0 9223372036854775807;
BA_DEF_ SG_ "GenSigSendType" ENUM "cyclicAndSpontaneousWithDelay","cyclic","spontaneousWithDelay","N_A","";
BA_DEF_ BO_ "DiagRequest" ENUM "No","Yes";
BA_DEF_ BO_ "Period [ms]" INT 0 65535;
BA_DEF_ BO_ "Type" ENUM "P","P+E","E","-";
BA_DEF_ BO_ "DiagResponse" ENUM "No","Yes";
BA_DEF_ BO_ "NmMessage" ENUM "No","Yes";
BA_DEF_ BO_ "GenMsgSendType" ENUM "cyclic","cyclicAndSpontaneousWithDelay","spontaneousWithDelay","N_A";
BA_DEF_ BO_ "GenMsgILSupport" ENUM "No","Yes";
BA_DEF_ BO_ "GenMsgStartDelayTime" INT 0 65535;
BA_DEF_ BO_ "GenMsgCycleTime" INT 0 65535;
BA_DEF_ BO_ "GenMsgDelayTime" INT 0 65535;
BA_DEF_ BO_ "DiagState" ENUM "No","Yes";
BA_DEF_ BO_ "VFrameFormat" ENUM "StandardCAN","ExtendedCAN","reserved","reserved","reserved","reserved","reserved","reserved","reserved","reserved","reserved","reserved","reserved","reserved","StandardCAN_FD","ExtendedCAN_FD";
BA_DEF_ BO_ "CANFD_BRS" ENUM "0","1";
BA_DEF_ "Manufacturer" STRING ;
BA_DEF_ "NmType" STRING ;
BA_DEF_ "BusType" STRING ;

BA_DEF_ "DBName" STRING ;
BA_DEF_ "Version" HEX 0 255;
BA_DEF_ "VersionWeek" INT 0 53;
BA_DEF_ "VersionYear" INT 0 99;
BA_DEF_ BU_ "NodeLayerModules" STRING ;
BA_DEF_ BU_ "NmStationAddress" HEX 0 255;
BA_DEF_ BU_ "NmNode" ENUM "No","Yes";
BA_DEF_ BU_ "ILUsed" ENUM "No","Yes";
BA_DEF_DEF_ "DiagRequest" "No";
BA_DEF_DEF_ "Period [ms]" 0;
BA_DEF_DEF_ "Type" "-";
BA_DEF_DEF_ "DiagResponse" "No";
BA_DEF_DEF_ "NmMessage" "No";
BA_DEF_DEF_ "GenMsgSendType" "N_A";
BA_DEF_DEF_ "GenMsgILSupport" "No";
BA_DEF_DEF_ "GenMsgStartDelayTime" 0;
BA_DEF_DEF_ "GenMsgCycleTime" 0;
BA_DEF_DEF_ "GenMsgDelayTime" 0;
BA_DEF_DEF_ "DiagState" "No";
BA_DEF_DEF_ "VFrameFormat" "StandardCAN_FD";
BA_DEF_DEF_ "CANFD_BRS" "0";
BA_DEF_DEF_ "Manufacturer" "Fiat";
BA_DEF_DEF_ "NmType" "";
BA_DEF_DEF_ "BusType" "CAN";

BA_DEF_DEF_ "DBName" "CAN";
BA_DEF_DEF_ "Version" 160;
BA_DEF_DEF_ "VersionWeek" 48;
BA_DEF_DEF_ "VersionYear" 25;
BA_DEF_DEF_ "NodeLayerModules" "Osek_TP.dll";
BA_DEF_DEF_ "NmStationAddress" 0;
BA_DEF_DEF_ "NmNode" "Yes";
BA_DEF_DEF_ "ILUsed" "Yes";
BA_DEF_DEF_ "Accuracy" "";
BA_DEF_DEF_ "Event trans." "No";
BA_DEF_DEF_ "GenSigStartValue" 0;
BA_DEF_DEF_ "GenSigSendType" "";
BA_ "NmStationAddress" BU_ ZCU_CL 10;
BA_ "NmStationAddress" BU_ LRCF 129;
BA_ "NmStationAddress" BU_ PAM 24;
BA_ "NmStationAddress" BU_ ZCU_F 12;
BA_ "NmStationAddress" BU_ HPC_MAIN_IVI 4;
BA_ "GenMsgSendType" BO_ 121 2;
BA_ "GenMsgILSupport" BO_ 121 1;
BA_ "GenMsgDelayTime" BO_ 121 10;
BA_ "CANFD_BRS" BO_ 121 1;
BA_ "Period [ms]" BO_ 592 20;
BA_ "GenMsgSendType" BO_ 592 0;
BA_ "GenMsgILSupport" BO_ 592 1;
BA_ "GenMsgCycleTime" BO_ 592 20;
BA_ "CANFD_BRS" BO_ 592 1;
BA_ "Period [ms]" BO_ 337 10;
BA_ "GenMsgSendType" BO_ 337 0;
BA_ "GenMsgILSupport" BO_ 337 1;
BA_ "GenMsgCycleTime" BO_ 337 10;
BA_ "CANFD_BRS" BO_ 337 1;
BA_ "GenMsgSendType" BO_ 2651930624 2;
BA_ "GenMsgILSupport" BO_ 2651930624 1;
BA_ "GenMsgDelayTime" BO_ 2651930624 10;
BA_ "VFrameFormat" BO_ 2651930624 15;
BA_ "CANFD_BRS" BO_ 2651930624 1;
BA_ "GenMsgSendType" BO_ 2651930753 2;
BA_ "GenMsgILSupport" BO_ 2651930753 1;
BA_ "GenMsgDelayTime" BO_ 2651930753 10;
BA_ "VFrameFormat" BO_ 2651930753 15;
BA_ "CANFD_BRS" BO_ 2651930753 1;
BA_ "GenMsgSendType" BO_ 2679898131 2;
BA_ "GenMsgDelayTime" BO_ 2679898131 10;
BA_ "VFrameFormat" BO_ 2679898131 15;
BA_ "CANFD_BRS" BO_ 2679898131 1;
BA_ "GenMsgSendType" BO_ 2679898132 2;
BA_ "GenMsgDelayTime" BO_ 2679898132 10;
BA_ "VFrameFormat" BO_ 2679898132 15;
BA_ "CANFD_BRS" BO_ 2679898132 1;
BA_ "DiagRequest" BO_ 2564476661 1;
BA_ "GenMsgSendType" BO_ 2564476661 2;
BA_ "VFrameFormat" BO_ 2564476661 15;
BA_ "CANFD_BRS" BO_ 2564476661 1;
BA_ "DiagRequest" BO_ 2564484085 1;
BA_ "GenMsgSendType" BO_ 2564484085 2;
BA_ "VFrameFormat" BO_ 2564484085 15;
BA_ "CANFD_BRS" BO_ 2564484085 1;
BA_ "DiagRequest" BO_ 2564483829 1;
BA_ "GenMsgSendType" BO_ 2564483829 2;
BA_ "VFrameFormat" BO_ 2564483829 15;
BA_ "CANFD_BRS" BO_ 2564483829 1;
BA_ "DiagRequest" BO_ 2564481781 1;
BA_ "GenMsgSendType" BO_ 2564481781 2;
BA_ "VFrameFormat" BO_ 2564481781 15;
BA_ "CANFD_BRS" BO_ 2564481781 1;
BA_ "GenMsgSendType" BO_ 2564554485 2;
BA_ "DiagState" BO_ 2564554485 1;
BA_ "VFrameFormat" BO_ 2564554485 15;
BA_ "CANFD_BRS" BO_ 2564554485 1;
BA_ "GenMsgSendType" BO_ 2564554482 2;
BA_ "DiagState" BO_ 2564554482 1;
BA_ "VFrameFormat" BO_ 2564554482 15;
BA_ "CANFD_BRS" BO_ 2564554482 1;
BA_ "DiagRequest" BO_ 2564476658 1;
BA_ "GenMsgSendType" BO_ 2564476658 2;
BA_ "VFrameFormat" BO_ 2564476658 15;
BA_ "CANFD_BRS" BO_ 2564476658 1;
BA_ "DiagRequest" BO_ 2564484082 1;
BA_ "GenMsgSendType" BO_ 2564484082 2;
BA_ "VFrameFormat" BO_ 2564484082 15;
BA_ "CANFD_BRS" BO_ 2564484082 1;
BA_ "DiagRequest" BO_ 2564483826 1;
BA_ "GenMsgSendType" BO_ 2564483826 2;
BA_ "VFrameFormat" BO_ 2564483826 15;
BA_ "CANFD_BRS" BO_ 2564483826 1;
BA_ "DiagRequest" BO_ 2564481778 1;
BA_ "GenMsgSendType" BO_ 2564481778 2;
BA_ "VFrameFormat" BO_ 2564481778 15;
BA_ "CANFD_BRS" BO_ 2564481778 1;
BA_ "DiagResponse" BO_ 2564486606 1;
BA_ "GenMsgSendType" BO_ 2564486606 2;
BA_ "VFrameFormat" BO_ 2564486606 15;
BA_ "CANFD_BRS" BO_ 2564486606 1;
BA_ "DiagResponse" BO_ 2564486635 1;
BA_ "GenMsgSendType" BO_ 2564486635 2;
BA_ "VFrameFormat" BO_ 2564486635 15;
BA_ "CANFD_BRS" BO_ 2564486635 1;
BA_ "DiagResponse" BO_ 2564486634 1;
BA_ "GenMsgSendType" BO_ 2564486634 2;
BA_ "VFrameFormat" BO_ 2564486634 15;
BA_ "CANFD_BRS" BO_ 2564486634 1;
BA_ "DiagResponse" BO_ 2564486626 1;
BA_ "GenMsgSendType" BO_ 2564486626 2;
BA_ "VFrameFormat" BO_ 2564486626 15;
BA_ "CANFD_BRS" BO_ 2564486626 1;
BA_ "DiagResponse" BO_ 2564485838 1;
BA_ "GenMsgSendType" BO_ 2564485838 2;
BA_ "VFrameFormat" BO_ 2564485838 15;
BA_ "CANFD_BRS" BO_ 2564485838 1;
BA_ "DiagResponse" BO_ 2564485867 1;
BA_ "GenMsgSendType" BO_ 2564485867 2;
BA_ "VFrameFormat" BO_ 2564485867 15;
BA_ "CANFD_BRS" BO_ 2564485867 1;
BA_ "DiagResponse" BO_ 2564485866 1;
BA_ "GenMsgSendType" BO_ 2564485866 2;
BA_ "VFrameFormat" BO_ 2564485866 15;
BA_ "CANFD_BRS" BO_ 2564485866 1;
BA_ "DiagResponse" BO_ 2564485858 1;
BA_ "GenMsgSendType" BO_ 2564485858 2;
BA_ "VFrameFormat" BO_ 2564485858 15;
BA_ "CANFD_BRS" BO_ 2564485858 1;
BA_ "DiagResponse" BO_ 2564682219 1;
BA_ "GenMsgSendType" BO_ 2564682219 2;
BA_ "VFrameFormat" BO_ 2564682219 1;
BA_ "DiagResponse" BO_ 2564682218 1;
BA_ "GenMsgSendType" BO_ 2564682218 2;
BA_ "VFrameFormat" BO_ 2564682218 1;
BA_ "DiagResponse" BO_ 2564682210 1;
BA_ "GenMsgSendType" BO_ 2564682210 2;
BA_ "VFrameFormat" BO_ 2564682210 1;
BA_ "Period [ms]" BO_ 340 10;
BA_ "GenMsgSendType" BO_ 340 0;
BA_ "GenMsgILSupport" BO_ 340 1;
BA_ "GenMsgCycleTime" BO_ 340 10;
BA_ "CANFD_BRS" BO_ 340 1;
BA_ "Period [ms]" BO_ 596 20;
BA_ "GenMsgSendType" BO_ 596 0;
BA_ "GenMsgILSupport" BO_ 596 1;
BA_ "GenMsgCycleTime" BO_ 596 20;
BA_ "CANFD_BRS" BO_ 596 1;
BA_ "GenMsgSendType" BO_ 1406 2;
BA_ "GenMsgILSupport" BO_ 1406 1;
BA_ "GenMsgDelayTime" BO_ 1406 10;
BA_ "CANFD_BRS" BO_ 1406 1;
BA_ "Period [ms]" BO_ 951 100;
BA_ "GenMsgSendType" BO_ 951 1;
BA_ "GenMsgILSupport" BO_ 951 1;
BA_ "GenMsgCycleTime" BO_ 951 100;
BA_ "GenMsgDelayTime" BO_ 951 10;
BA_ "CANFD_BRS" BO_ 951 1;
BA_ "Period [ms]" BO_ 1719 500;
BA_ "GenMsgSendType" BO_ 1719 1;
BA_ "GenMsgILSupport" BO_ 1719 1;
BA_ "GenMsgCycleTime" BO_ 1719 500;
BA_ "GenMsgDelayTime" BO_ 1719 10;
BA_ "CANFD_BRS" BO_ 1719 1;
BA_ "Period [ms]" BO_ 633 20;
BA_ "GenMsgSendType" BO_ 633 0;
BA_ "GenMsgILSupport" BO_ 633 1;
BA_ "GenMsgCycleTime" BO_ 633 20;
BA_ "CANFD_BRS" BO_ 633 1;
BA_ "Period [ms]" BO_ 1154 50;
BA_ "GenMsgSendType" BO_ 1154 0;
BA_ "GenMsgILSupport" BO_ 1154 1;
BA_ "GenMsgStartDelayTime" BO_ 1154 40;
BA_ "GenMsgCycleTime" BO_ 1154 50;
BA_ "CANFD_BRS" BO_ 1154 1;
BA_ "Period [ms]" BO_ 661 50;
BA_ "GenMsgSendType" BO_ 661 0;
BA_ "GenMsgILSupport" BO_ 661 1;
BA_ "GenMsgStartDelayTime" BO_ 661 10;
BA_ "GenMsgCycleTime" BO_ 661 50;
BA_ "CANFD_BRS" BO_ 661 1;
BA_ "Period [ms]" BO_ 641 20;
BA_ "GenMsgSendType" BO_ 641 1;
BA_ "GenMsgILSupport" BO_ 641 1;
BA_ "GenMsgStartDelayTime" BO_ 641 10;
BA_ "GenMsgCycleTime" BO_ 641 20;
BA_ "GenMsgDelayTime" BO_ 641 10;
BA_ "CANFD_BRS" BO_ 641 1;
BA_ "Period [ms]" BO_ 1153 100;
BA_ "GenMsgSendType" BO_ 1153 1;
BA_ "GenMsgILSupport" BO_ 1153 1;
BA_ "GenMsgStartDelayTime" BO_ 1153 85;
BA_ "GenMsgCycleTime" BO_ 1153 100;
BA_ "GenMsgDelayTime" BO_ 1153 10;
BA_ "CANFD_BRS" BO_ 1153 1;
BA_ "Period [ms]" BO_ 1409 200;
BA_ "GenMsgSendType" BO_ 1409 1;
BA_ "GenMsgILSupport" BO_ 1409 1;
BA_ "GenMsgStartDelayTime" BO_ 1409 100;
BA_ "GenMsgCycleTime" BO_ 1409 200;
BA_ "GenMsgDelayTime" BO_ 1409 10;
BA_ "CANFD_BRS" BO_ 1409 1;
BA_ "GenSigSendType" SG_ 121 ECU_Code_ACK 2;
BA_ "GenSigSendType" SG_ 121 Rep_UCE 2;
BA_ "GenSigStartValue" SG_ 592 ESC_STATUS 1;
BA_ "GenSigSendType" SG_ 592 ESC_STATUS 1;
BA_ "GenSigStartValue" SG_ 592 TCS_STATUS 1;
BA_ "GenSigSendType" SG_ 592 TCS_STATUS 1;
BA_ "GenSigSendType" SG_ 592 DTC_STATE 1;
BA_ "GenSigSendType" SG_ 592 ESC_BRAKE_STATE 1;
BA_ "GenSigSendType" SG_ 592 ESC_TCS_STATE 1;
BA_ "GenSigSendType" SG_ 592 TCS_BRAKE_STATE 1;
BA_ "GenSigSendType" SG_ 592 TCS_STATE 1;
BA_ "GenSigSendType" SG_ 592 FREE_4 1;
BA_ "GenSigSendType" SG_ 592 EPB_FAILSTATUS 1;
BA_ "GenSigSendType" SG_ 592 EPB_SECUREMENT_RELEASE_STATUS 1;
BA_ "GenSigSendType" SG_ 592 EPB_STATE 1;
BA_ "GenSigSendType" SG_ 592 EPB_SWITCH_POSITION_STATE 1;
BA_ "GenSigSendType" SG_ 592 VEHICLE_SECUREMENT_STATE 1;
BA_ "GenSigSendType" SG_ 592 E2E_ALIVE_BSM_DATA_3 1;
BA_ "GenSigSendType" SG_ 592 EPB_WHEEL_TORQUE_LIMITATION_REQ 1;
BA_ "GenSigStartValue" SG_ 592 EPB_WHEEL_TORQUE_LIMITATION_VAL 511;
BA_ "GenSigSendType" SG_ 592 EPB_WHEEL_TORQUE_LIMITATION_VAL 1;
BA_ "GenSigStartValue" SG_ 592 ROAD_SLOPE_ESTIMATED_VALUE 255;
BA_ "GenSigSendType" SG_ 592 ROAD_SLOPE_ESTIMATED_VALUE 1;
BA_ "GenSigSendType" SG_ 592 BRAKE_EMERGENCY_SIGNAL_REQUEST 1;
BA_ "GenSigSendType" SG_ 592 BRAKE_ASSISTANCE_FAILSTATUS 1;
BA_ "GenSigSendType" SG_ 592 AUTO_HOLD_STATE 1;
BA_ "GenSigStartValue" SG_ 592 AEB_BRAKING_STATUS 3;
BA_ "GenSigSendType" SG_ 592 AEB_BRAKING_STATUS 1;
BA_ "GenSigSendType" SG_ 592 AEB_BRAKING_ACKNOWLEDGE 1;
BA_ "GenSigStartValue" SG_ 592 DRIVERBRAKEPEDAL_WHEELTRQ_REQ 253;
BA_ "GenSigSendType" SG_ 592 DRIVERBRAKEPEDAL_WHEELTRQ_REQ 1;
BA_ "GenSigStartValue" SG_ 592 LXA_SAFETY_DYNVHL_STATE 1;
BA_ "GenSigSendType" SG_ 592 LXA_SAFETY_DYNVHL_STATE 1;
BA_ "GenSigSendType" SG_ 592 STEERING_COLLABORATI_YAWCTRL_REQ 1;
BA_ "GenSigSendType" SG_ 592 STEERING_CONTROL_AUTOMATIC_REQ 1;
BA_ "GenSigSendType" SG_ 592 STEERING_CONTROL_COLLABORATI_REQ 1;
BA_ "GenSigStartValue" SG_ 592 VEHICLE_PATH_CURVATURE 65535;
BA_ "GenSigSendType" SG_ 592 VEHICLE_PATH_CURVATURE 1;
BA_ "GenSigStartValue" SG_ 592 STEERING_RACKPOSITI_YAWCTRL_STPT 32767;
BA_ "GenSigSendType" SG_ 592 STEERING_RACKPOSITI_YAWCTRL_STPT 1;
BA_ "GenSigStartValue" SG_ 592 STEERING_RACKPOSITION_SETPOINT 32767;
BA_ "GenSigSendType" SG_ 592 STEERING_RACKPOSITION_SETPOINT 1;
BA_ "GenSigSendType" SG_ 592 SBA_TRIGGER 1;
BA_ "GenSigSendType" SG_ 592 ACC_MOTION_CONTROL_STATE 1;
BA_ "GenSigSendType" SG_ 592 E2E_CRC_BSM_DATA_3 1;
BA_ "GenSigStartValue" SG_ 337 CARBODY_LAT_ACCEL_CORRECTED 4095;
BA_ "GenSigSendType" SG_ 337 CARBODY_LAT_ACCEL_CORRECTED 1;
BA_ "GenSigStartValue" SG_ 337 WHEEL_LONGI_SPEED_CALCUL_FL 65535;
BA_ "GenSigSendType" SG_ 337 WHEEL_LONGI_SPEED_CALCUL_FL 1;
BA_ "GenSigStartValue" SG_ 337 WHEEL_LONGI_SPEED_CALCUL_FR 65535;
BA_ "GenSigSendType" SG_ 337 WHEEL_LONGI_SPEED_CALCUL_FR 1;
BA_ "GenSigStartValue" SG_ 337 WHEEL_LONGI_SPEED_CALCUL_RL 65535;
BA_ "GenSigSendType" SG_ 337 WHEEL_LONGI_SPEED_CALCUL_RL 1;
BA_ "GenSigStartValue" SG_ 337 WHEEL_LONGI_SPEED_CALCUL_RR 65535;
BA_ "GenSigSendType" SG_ 337 WHEEL_LONGI_SPEED_CALCUL_RR 1;
BA_ "GenSigSendType" SG_ 337 FREE_4 1;
BA_ "GenSigStartValue" SG_ 337 CARBODY_LONG_ACCEL_CORRECTED 4095;
BA_ "GenSigSendType" SG_ 337 CARBODY_LONG_ACCEL_CORRECTED 1;
BA_ "GenSigStartValue" SG_ 337 CARBODY_YAW_VELOCITY_FILTERED 2047;
BA_ "GenSigSendType" SG_ 337 CARBODY_YAW_VELOCITY_FILTERED 1;
BA_ "GenSigStartValue" SG_ 337 VEHICLE_LONGI_ACCEL_CALCULATED 1023;
BA_ "GenSigSendType" SG_ 337 VEHICLE_LONGI_ACCEL_CALCULATED 1;
BA_ "GenSigStartValue" SG_ 337 VEHICLE_LONG_SPEED_COMPUTED_VAL 65535;
BA_ "GenSigSendType" SG_ 337 VEHICLE_LONG_SPEED_COMPUTED_VAL 1;
BA_ "GenSigStartValue" SG_ 337 VEHICLE_LONG_SPEED_REFERENCE_VAL 65535;
BA_ "GenSigSendType" SG_ 337 VEHICLE_LONG_SPEED_REFERENCE_VAL 1;
BA_ "GenSigSendType" SG_ 337 VEHICLE_MOTION_DIRECTION 1;
BA_ "GenSigSendType" SG_ 337 WHEEL_ROLLING_DIRECTION_FL 1;
BA_ "GenSigSendType" SG_ 337 WHEEL_ROLLING_DIRECTION_FR 1;
BA_ "GenSigSendType" SG_ 337 WHEEL_ROLLING_DIRECTION_RL 1;
BA_ "GenSigSendType" SG_ 337 WHEEL_ROLLING_DIRECTION_RR 1;
BA_ "GenSigSendType" SG_ 337 WHEEL_ROTATION_PULSE_FL_COUNTER 1;
BA_ "GenSigSendType" SG_ 337 WHEEL_ROTATION_PULSE_FR_COUNTER 1;
BA_ "GenSigSendType" SG_ 337 WHEEL_ROTATION_PULSE_RL_COUNTER 1;
BA_ "GenSigSendType" SG_ 337 WHEEL_ROTATION_PULSE_RR_COUNTER 1;
BA_ "GenSigSendType" SG_ 337 WHEEL_ROTATION_PULSE_FL_FAIL_STS 1;
BA_ "GenSigSendType" SG_ 337 WHEEL_ROTATION_PULSE_FR_FAIL_STS 1;
BA_ "GenSigSendType" SG_ 337 WHEEL_ROTATION_PULSE_RL_FAIL_STS 1;
BA_ "GenSigSendType" SG_ 337 WHEEL_ROTATION_PULSE_RR_FAIL_STS 1;
BA_ "GenSigSendType" SG_ 337 E2E_ALIVE_BSM_DATA_4_151 1;
BA_ "GenSigSendType" SG_ 337 E2E_CRC_BSM_DATA_4_151 1;
BA_ "GenSigStartValue" SG_ 337 BRAKE_STATE 1;
BA_ "GenSigSendType" SG_ 337 BRAKE_STATE 1;
BA_ "GenSigSendType" SG_ 337 STOP_LIGHTS_ACTIVATION_REQUEST 1;
BA_ "GenSigSendType" SG_ 337 SAFESTOP_BRAKING_STATE 1;
BA_ "GenSigSendType" SG_ 337 BRAKE_PEDAL_PRESSED_STATE 1;
BA_ "GenSigSendType" SG_ 337 BAS_STATE 1;
BA_ "GenSigSendType" SG_ 337 ABS_STATE 1;
BA_ "GenSigSendType" SG_ 337 EBD_STATE 1;
BA_ "GenSigSendType" SG_ 337 ABS_WHEEL_FRONT_LEFT_STATE 1;
BA_ "GenSigSendType" SG_ 337 ABS_WHEEL_FRONT_RIGHT_STATE 1;
BA_ "GenSigSendType" SG_ 337 ABS_WHEEL_REAR_LEFT_STATE 1;
BA_ "GenSigSendType" SG_ 337 ABS_WHEEL_REAR_RIGHT_STATE 1;
BA_ "GenSigStartValue" SG_ 337 BRAKE_ASSISTANCE_PRESSURE_VALUE 4095;
BA_ "GenSigSendType" SG_ 337 BRAKE_ASSISTANCE_PRESSURE_VALUE 1;
BA_ "GenSigStartValue" SG_ 337 ROAD_SLOPE_ACCURACY_STATE 3;
BA_ "GenSigSendType" SG_ 337 ROAD_SLOPE_ACCURACY_STATE 1;
BA_ "GenSigSendType" SG_ 337 FREE_4_2 1;
BA_ "GenSigSendType" SG_ 337 E2E_CRC_BSM_DATA_4_2 1;
BA_ "GenSigSendType" SG_ 337 E2E_ALIVE_BSM_DATA_4_2 1;
BA_ "GenSigSendType" SG_ 337 EBD_FAILSTATUS 1;
BA_ "GenSigSendType" SG_ 337 ABS_FAILSTATUS 1;
BA_ "GenSigSendType" SG_ 2651930624 Digit_01 2;
BA_ "GenSigSendType" SG_ 2651930624 Digit_02 2;
BA_ "GenSigSendType" SG_ 2651930624 Digit_03 2;
BA_ "GenSigSendType" SG_ 2651930624 Digit_04 2;
BA_ "GenSigSendType" SG_ 2651930624 Digit_05 2;
BA_ "GenSigSendType" SG_ 2651930624 Digit_06 2;
BA_ "GenSigSendType" SG_ 2651930624 Digit_07 2;
BA_ "GenSigSendType" SG_ 2651930624 Digit_08 2;
BA_ "GenSigSendType" SG_ 2651930624 Digit_09 2;
BA_ "GenSigSendType" SG_ 2651930624 Digit_10 2;
BA_ "GenSigSendType" SG_ 2651930624 Digit_11 2;
BA_ "Accuracy" SG_ 2651930753 Digit_10_LRCF "-";
BA_ "GenSigSendType" SG_ 2651930753 Digit_10_LRCF 2;
BA_ "Accuracy" SG_ 2651930753 Digit_11_LRCF "-";
BA_ "GenSigSendType" SG_ 2651930753 Digit_11_LRCF 2;
BA_ "Accuracy" SG_ 2651930753 Digit_01_LRCF "-";
BA_ "GenSigSendType" SG_ 2651930753 Digit_01_LRCF 2;
BA_ "Accuracy" SG_ 2651930753 Digit_02_LRCF "-";
BA_ "GenSigSendType" SG_ 2651930753 Digit_02_LRCF 2;
BA_ "Accuracy" SG_ 2651930753 Digit_03_LRCF "-";
BA_ "GenSigSendType" SG_ 2651930753 Digit_03_LRCF 2;
BA_ "Accuracy" SG_ 2651930753 Digit_04_LRCF "-";
BA_ "GenSigSendType" SG_ 2651930753 Digit_04_LRCF 2;
BA_ "Accuracy" SG_ 2651930753 Digit_05_LRCF "-";
BA_ "GenSigSendType" SG_ 2651930753 Digit_05_LRCF 2;
BA_ "Accuracy" SG_ 2651930753 Digit_06_LRCF "-";
BA_ "GenSigSendType" SG_ 2651930753 Digit_06_LRCF 2;
BA_ "Accuracy" SG_ 2651930753 Digit_07_LRCF "-";
BA_ "GenSigSendType" SG_ 2651930753 Digit_07_LRCF 2;
BA_ "Accuracy" SG_ 2651930753 Digit_08_LRCF "-";
BA_ "GenSigSendType" SG_ 2651930753 Digit_08_LRCF 2;
BA_ "Accuracy" SG_ 2651930753 Digit_09_LRCF "-";
BA_ "GenSigSendType" SG_ 2651930753 Digit_09_LRCF 2;
BA_ "GenSigSendType" SG_ 2679898131 SIG_DEV_LRCF_1 2;
BA_ "GenSigSendType" SG_ 2679898132 SIG_DEV_LRCF_2 2;
BA_ "GenSigSendType" SG_ 2564476661 N_PDU 2;
BA_ "GenSigSendType" SG_ 2564484085 N_PDU 2;
BA_ "GenSigSendType" SG_ 2564483829 N_PDU 2;
BA_ "GenSigSendType" SG_ 2564481781 N_PDU 2;
BA_ "GenSigSendType" SG_ 2564554485 N_PDU 2;
BA_ "GenSigSendType" SG_ 2564554482 N_PDU 2;
BA_ "GenSigSendType" SG_ 2564476658 N_PDU 2;
BA_ "GenSigSendType" SG_ 2564484082 N_PDU 2;
BA_ "GenSigSendType" SG_ 2564483826 N_PDU 2;
BA_ "GenSigSendType" SG_ 2564481778 N_PDU 2;
BA_ "GenSigSendType" SG_ 2564486606 N_PDU 2;
BA_ "GenSigSendType" SG_ 2564486635 N_PDU 2;
BA_ "GenSigSendType" SG_ 2564486634 N_PDU 2;
BA_ "GenSigSendType" SG_ 2564486626 N_PDU 2;
BA_ "GenSigSendType" SG_ 2564485838 N_PDU 2;
BA_ "GenSigSendType" SG_ 2564485867 N_PDU 2;
BA_ "GenSigSendType" SG_ 2564485866 N_PDU 2;
BA_ "GenSigSendType" SG_ 2564485858 N_PDU 2;
BA_ "GenSigSendType" SG_ 2564682219 N_PDU 2;
BA_ "GenSigSendType" SG_ 2564682218 N_PDU 2;
BA_ "GenSigSendType" SG_ 2564682210 N_PDU 2;
BA_ "GenSigSendType" SG_ 340 FREE_4 1;
BA_ "GenSigSendType" SG_ 340 STEERING_ASSIST_FAILSTATUS 1;
BA_ "GenSigSendType" SG_ 340 STEERING_ASSIST_STATUS 1;
BA_ "GenSigSendType" SG_ 340 STEERING_POWERSUPPLY_BOOST_REQ 1;
BA_ "GenSigSendType" SG_ 340 LKA_STEERING_ACTUATION_STATE 1;
BA_ "GenSigSendType" SG_ 340 LKA_STEERING_AVAILABILITY_STATE 1;
BA_ "GenSigSendType" SG_ 340 LXA_STEERING_LIMITATION_STATE 1;
BA_ "GenSigSendType" SG_ 340 LXA_STEERING_STATE 1;
BA_ "GenSigSendType" SG_ 340 STEERINGWHEEL_ANGLE_CAL_FRT_STS 1;
BA_ "GenSigSendType" SG_ 340 STEERINGWHEEL_ANGLE_REL_FRT_STE 1;
BA_ "GenSigSendType" SG_ 340 STEERINGWHEEL_ANGLE_FRONT_TYPE 1;
BA_ "GenSigStartValue" SG_ 340 HANDWHEEL_STEERING_TRQ_MEASURED 1020;
BA_ "GenSigSendType" SG_ 340 HANDWHEEL_STEERING_TRQ_MEASURED 1;
BA_ "GenSigStartValue" SG_ 340 LXA_STEERING_TORQUE_ADDON_VALUE 125;
BA_ "GenSigSendType" SG_ 340 LXA_STEERING_TORQUE_ADDON_VALUE 1;
BA_ "GenSigStartValue" SG_ 340 HANDWHEEL_STEERING_ANGLE_VALUE 16383;
BA_ "GenSigSendType" SG_ 340 HANDWHEEL_STEERING_ANGLE_VALUE 1;
BA_ "GenSigStartValue" SG_ 340 STEERINGWHEEL_ANGLE_FRT_ACCURACY 1023;
BA_ "GenSigSendType" SG_ 340 STEERINGWHEEL_ANGLE_FRT_ACCURACY 1;
BA_ "GenSigStartValue" SG_ 340 STEERINGWHEEL_ANGLE_FRONT_VAL 16383;
BA_ "GenSigSendType" SG_ 340 STEERINGWHEEL_ANGLE_FRONT_VAL 1;
BA_ "GenSigStartValue" SG_ 340 STEERINGWHEEL_ANGLE_REL_FRT_VA 32767;
BA_ "GenSigSendType" SG_ 340 STEERINGWHEEL_ANGLE_REL_FRT_VA 1;
BA_ "GenSigStartValue" SG_ 340 WHEEL_STEERINGANGLE_FRONT_VAL 32767;
BA_ "GenSigSendType" SG_ 340 WHEEL_STEERINGANGLE_FRONT_VAL 1;
BA_ "GenSigStartValue" SG_ 340 STEERINGWHEEL_ROT_VELOCITY_FRT 2050;
BA_ "GenSigSendType" SG_ 340 STEERINGWHEEL_ROT_VELOCITY_FRT 1;
BA_ "GenSigSendType" SG_ 340 E2E_CRC_EPS_DATA_1 1;
BA_ "GenSigSendType" SG_ 340 E2E_ALIVE_EPS_DATA_1 1;
BA_ "GenSigSendType" SG_ 596 FREE_4 1;
BA_ "GenSigStartValue" SG_ 596 STEERING_RACK_POSITION_VALUE 32767;
BA_ "GenSigSendType" SG_ 596 STEERING_RACK_POSITION_VALUE 1;
BA_ "GenSigSendType" SG_ 596 E2E_ALIVE_EPS_DATA_2 1;
BA_ "GenSigSendType" SG_ 596 E2E_CRC_EPS_DATA_2 1;
BA_ "Event trans." SG_ 1406 ECU_CODE 0;
BA_ "GenSigSendType" SG_ 1406 ECU_CODE 2;
BA_ "Event trans." SG_ 1406 RELEVANCE_OF_DATE 0;
BA_ "GenSigSendType" SG_ 1406 RELEVANCE_OF_DATE 2;
BA_ "Event trans." SG_ 1406 NM_Frames 0;
BA_ "GenSigSendType" SG_ 1406 NM_Frames 2;
BA_ "Event trans." SG_ 1406 Status_DTC 0;
BA_ "GenSigSendType" SG_ 1406 Status_DTC 2;
BA_ "Event trans." SG_ 1406 Fault_Code 0;
BA_ "GenSigSendType" SG_ 1406 Fault_Code 2;
BA_ "Event trans." SG_ 1406 DTC_Format_Identifier 0;
BA_ "GenSigStartValue" SG_ 1406 DTC_Format_Identifier 1;
BA_ "GenSigSendType" SG_ 1406 DTC_Format_Identifier 2;
BA_ "Event trans." SG_ 1406 KM_DEH 0;
BA_ "GenSigSendType" SG_ 1406 KM_DEH 2;
BA_ "Event trans." SG_ 1406 Absolute_Defect_Event_Year 0;
BA_ "GenSigStartValue" SG_ 1406 Absolute_Defect_Event_Year 65535;
BA_ "GenSigSendType" SG_ 1406 Absolute_Defect_Event_Year 2;
BA_ "Event trans." SG_ 1406 Absolute_Defect_Event_Month 0;
BA_ "GenSigStartValue" SG_ 1406 Absolute_Defect_Event_Month 15;
BA_ "GenSigSendType" SG_ 1406 Absolute_Defect_Event_Month 2;
BA_ "Event trans." SG_ 1406 Absolute_Defect_Event_Day 0;
BA_ "GenSigStartValue" SG_ 1406 Absolute_Defect_Event_Day 31;
BA_ "GenSigSendType" SG_ 1406 Absolute_Defect_Event_Day 2;
BA_ "Event trans." SG_ 1406 Absolute_Defect_Event_Hour 0;
BA_ "GenSigStartValue" SG_ 1406 Absolute_Defect_Event_Hour 31;
BA_ "GenSigSendType" SG_ 1406 Absolute_Defect_Event_Hour 2;
BA_ "Event trans." SG_ 1406 Absolute_Defect_Event_Minute 0;
BA_ "GenSigStartValue" SG_ 1406 Absolute_Defect_Event_Minute 63;
BA_ "GenSigSendType" SG_ 1406 Absolute_Defect_Event_Minute 2;
BA_ "Event trans." SG_ 1406 Absolute_Defect_Event_Second 0;
BA_ "GenSigStartValue" SG_ 1406 Absolute_Defect_Event_Second 63;
BA_ "GenSigSendType" SG_ 1406 Absolute_Defect_Event_Second 2;
BA_ "Event trans." SG_ 1406 Abs_Defect_Event_Tenth_Of_Sec 0;
BA_ "GenSigStartValue" SG_ 1406 Abs_Defect_Event_Tenth_Of_Sec 255;
BA_ "GenSigSendType" SG_ 1406 Abs_Defect_Event_Tenth_Of_Sec 2;
BA_ "GenSigSendType" SG_ 951 FREE_4 0;
BA_ "Event trans." SG_ 951 AEB_HAPTIC_REQUEST 0;
BA_ "GenSigSendType" SG_ 951 AEB_HAPTIC_REQUEST 0;
BA_ "Event trans." SG_ 951 ACC_MODE_CHOICE_REQ 0;
BA_ "GenSigSendType" SG_ 951 ACC_MODE_CHOICE_REQ 0;
BA_ "Event trans." SG_ 951 ACC_AVAILABILITY_FOR_SWITCH 0;
BA_ "GenSigSendType" SG_ 951 ACC_AVAILABILITY_FOR_SWITCH 0;
BA_ "Event trans." SG_ 951 ACC_TAKEOVER_REQUEST 0;
BA_ "GenSigSendType" SG_ 951 ACC_TAKEOVER_REQUEST 0;
BA_ "GenSigStartValue" SG_ 951 BLINDSPOTDETECTION_DRIVERREQUEST 1;
BA_ "GenSigSendType" SG_ 951 BLINDSPOTDETECTION_DRIVERREQUEST 0;
BA_ "GenSigSendType" SG_ 951 MAIN_LATERAL_ST_INFO 0;
BA_ "GenSigSendType" SG_ 951 MAIN_LONGITUDINAL_STINFO 0;
BA_ "Event trans." SG_ 951 WPP_DRIVER_INHIBITION_REQUEST 0;
BA_ "GenSigSendType" SG_ 951 WPP_DRIVER_INHIBITION_REQUEST 0;
BA_ "Event trans." SG_ 951 AEB_HMI_READY 0;
BA_ "GenSigStartValue" SG_ 951 AEB_HMI_READY 1;
BA_ "GenSigSendType" SG_ 951 AEB_HMI_READY 0;
BA_ "Event trans." SG_ 951 FCW_HMI_READY 0;
BA_ "GenSigStartValue" SG_ 951 FCW_HMI_READY 1;
BA_ "GenSigSendType" SG_ 951 FCW_HMI_READY 0;
BA_ "Event trans." SG_ 951 FCW_HMI_SETTING 0;
BA_ "GenSigSendType" SG_ 951 FCW_HMI_SETTING 0;
BA_ "GenSigSendType" SG_ 951 AEB_DRIVER_ATTENTIVE 0;
BA_ "GenSigSendType" SG_ 951 AEB_ROAD_FRICTION 0;
BA_ "GenSigSendType" SG_ 951 E2E_CRC_HPC_DATA_1 0;
BA_ "GenSigSendType" SG_ 951 E2E_ALIVE_HPC_DATA_1 0;
BA_ "Event trans." SG_ 951 AEB_HMI_LIMITATION 0;
BA_ "GenSigStartValue" SG_ 951 AEB_HMI_LIMITATION 3;
BA_ "GenSigSendType" SG_ 951 AEB_HMI_LIMITATION 0;
BA_ "Event trans." SG_ 951 LONGITUDINAL_SPEED_SETPOINT 0;
BA_ "GenSigStartValue" SG_ 951 LONGITUDINAL_SPEED_SETPOINT 32767;
BA_ "GenSigSendType" SG_ 951 LONGITUDINAL_SPEED_SETPOINT 0;
BA_ "Event trans." SG_ 951 ELKS_SELECTION_REQ 0;
BA_ "GenSigStartValue" SG_ 951 ELKS_SELECTION_REQ 1;
BA_ "GenSigSendType" SG_ 951 ELKS_SELECTION_REQ 0;
BA_ "GenSigStartValue" SG_ 951 FCW_SETTING 1;
BA_ "GenSigSendType" SG_ 951 FCW_SETTING 0;
BA_ "GenSigSendType" SG_ 951 LRCF_CANCEL_REQ 0;
BA_ "GenSigStartValue" SG_ 951 LRCF_DCTYPE 3;
BA_ "GenSigSendType" SG_ 951 LRCF_DCTYPE 0;
BA_ "GenSigSendType" SG_ 951 LRCF_NUMBEROFDC 0;
BA_ "GenSigSendType" SG_ 951 LRCF_TRANSFER_READINESS_REQ 0;
BA_ "GenSigSendType" SG_ 951 LPA_STATE_INFO 0;
BA_ "Event trans." SG_ 951 VHL_DL_OR_TX_ACTIVE 0;
BA_ "GenSigSendType" SG_ 951 VHL_DL_OR_TX_ACTIVE 0;
BA_ "Event trans." SG_ 951 OTA_UPDATE_STATUS 0;
BA_ "GenSigSendType" SG_ 951 OTA_UPDATE_STATUS 0;
BA_ "GenSigSendType" SG_ 951 ELKS_COCKPIT_FAILURE 0;
BA_ "GenSigSendType" SG_ 951 ACC_MAIN_ST_INFO 0;
BA_ "GenSigSendType" SG_ 951 ALERT_SOUND_LOCALIZATION 0;
BA_ "GenSigSendType" SG_ 951 ALERT_SOUND_LEVEL 0;
BA_ "GenSigStartValue" SG_ 951 ALERT_SOUND_NUMBER 30;
BA_ "GenSigSendType" SG_ 951 ALERT_SOUND_NUMBER 0;
BA_ "GenSigSendType" SG_ 951 SL_SPEED_SETPOINT_DUA 0;
BA_ "GenSigSendType" SG_ 951 SL_ACTIVATION_REQUEST 0;
BA_ "Event trans." SG_ 951 CC_ACTIVATION_REQUEST 0;
BA_ "GenSigSendType" SG_ 951 CC_ACTIVATION_REQUEST 0;
BA_ "Event trans." SG_ 951 CC_SPEED_SETPOINT_DUA 0;
BA_ "GenSigSendType" SG_ 951 CC_SPEED_SETPOINT_DUA 0;
BA_ "Event trans." SG_ 951 REGULATION_LONGI_TYPE 0;
BA_ "GenSigSendType" SG_ 951 REGULATION_LONGI_TYPE 0;
BA_ "Event trans." SG_ 951 LPA_ST_INFO 0;
BA_ "GenSigSendType" SG_ 951 LPA_ST_INFO 0;
BA_ "Event trans." SG_ 951 DDMS_STATE 0;
BA_ "GenSigSendType" SG_ 951 DDMS_STATE 0;
BA_ "Event trans." SG_ 951 DDMS_FOV_AREA 0;
BA_ "GenSigSendType" SG_ 951 DDMS_FOV_AREA 0;
BA_ "Event trans." SG_ 951 DDMS_EYE_STATUS 0;
BA_ "GenSigSendType" SG_ 951 DDMS_EYE_STATUS 0;
BA_ "Event trans." SG_ 951 DDMS_DROWSINESS_LEVEL 0;
BA_ "GenSigSendType" SG_ 951 DDMS_DROWSINESS_LEVEL 0;
BA_ "Event trans." SG_ 951 DDMS_DISTRACTION_LEVEL 0;
BA_ "GenSigSendType" SG_ 951 DDMS_DISTRACTION_LEVEL 0;
BA_ "Event trans." SG_ 951 DDM_SAFETY_MODE_REQUEST 0;
BA_ "GenSigSendType" SG_ 951 DDM_SAFETY_MODE_REQUEST 0;
BA_ "Event trans." SG_ 1719 RCTA_DRIVER_INHIBITION_REQUEST 0;
BA_ "GenSigSendType" SG_ 1719 RCTA_DRIVER_INHIBITION_REQUEST 0;
BA_ "Event trans." SG_ 1719 ACC_TIV_SETPOINT 0;
BA_ "GenSigSendType" SG_ 1719 ACC_TIV_SETPOINT 0;
BA_ "GenSigSendType" SG_ 1719 MAIN_AUTOMATION_ST_INFO 0;
BA_ "GenSigSendType" SG_ 1719 COUNTRY_CODE_MERGED 0;
BA_ "Event trans." SG_ 1719 ACC_SPEED_SET_POINT 0;
BA_ "GenSigStartValue" SG_ 1719 ACC_SPEED_SET_POINT 25401;
BA_ "GenSigSendType" SG_ 1719 ACC_SPEED_SET_POINT 0;
BA_ "GenSigSendType" SG_ 633 ACC_STATE_INFO_FOR_CHASSIS 1;
BA_ "GenSigStartValue" SG_ 633 PACC_ACCEL_LONGI_REQUEST 500;
BA_ "GenSigSendType" SG_ 633 PACC_ACCEL_LONGI_REQUEST 1;
BA_ "GenSigSendType" SG_ 633 PACC_BEVENT_IN_PROGRESS 1;
BA_ "GenSigSendType" SG_ 633 GPAC_BINHIB_ACCEL_BEND_REQ 1;
BA_ "GenSigSendType" SG_ 633 PACC_POTACCEL_LONGI_REQUEST 1;
BA_ "GenSigSendType" SG_ 1154 IHM_R2_POSITION 1;
BA_ "GenSigSendType" SG_ 1154 FRONTCAM_EGO_OBJ_TYPE 1;
BA_ "GenSigSendType" SG_ 1154 FRONTCAM_EGO2_OBJ_TYPE 1;
BA_ "GenSigSendType" SG_ 1154 FRONTCAM_L1_OBJ_TYPE 1;
BA_ "GenSigSendType" SG_ 1154 FRONTCAM_L2_OBJ_TYPE 1;
BA_ "GenSigSendType" SG_ 1154 FRONTCAM_L3_OBJ_TYPE 1;
BA_ "GenSigSendType" SG_ 1154 FRONTCAM_R1_OBJ_TYPE 1;
BA_ "GenSigSendType" SG_ 1154 FRONTCAM_R2_OBJ_TYPE 1;
BA_ "GenSigSendType" SG_ 1154 FRONTCAM_R3_OBJ_TYPE 1;
BA_ "GenSigSendType" SG_ 1154 FRONTCAM_EGO_OBJ_CONFID_OBJ 1;
BA_ "GenSigSendType" SG_ 1154 FRONTCAM_EGO2_OBJ_CONFID_OBJ 1;
BA_ "GenSigSendType" SG_ 1154 FRONTCAM_L1_OBJ_CONFID_OBJ 1;
BA_ "GenSigSendType" SG_ 1154 FRONTCAM_L2_OBJ_CONFID_OBJ 1;
BA_ "GenSigSendType" SG_ 1154 FRONTCAM_L3_OBJ_CONFID_OBJ 1;
BA_ "GenSigSendType" SG_ 1154 FRONTCAM_R1_OBJ_CONFID_OBJ 1;
BA_ "GenSigSendType" SG_ 1154 FRONTCAM_R2_OBJ_CONFID_OBJ 1;
BA_ "GenSigSendType" SG_ 1154 FRONTCAM_R3_OBJ_CONFID_OBJ 1;
BA_ "GenSigStartValue" SG_ 1154 FRONTCAM_EGO_OBJ_LAT_DISTANCE 63;
BA_ "GenSigSendType" SG_ 1154 FRONTCAM_EGO_OBJ_LAT_DISTANCE 1;
BA_ "GenSigStartValue" SG_ 1154 FRONTCAM_EGO2_OBJ_LAT_DISTANCE 63;
BA_ "GenSigSendType" SG_ 1154 FRONTCAM_EGO2_OBJ_LAT_DISTANCE 1;
BA_ "GenSigStartValue" SG_ 1154 FRONTCAM_L1_OBJ_LAT_DISTANCE 63;
BA_ "GenSigSendType" SG_ 1154 FRONTCAM_L1_OBJ_LAT_DISTANCE 1;
BA_ "GenSigStartValue" SG_ 1154 FRONTCAM_L2_OBJ_LAT_DISTANCE 63;
BA_ "GenSigSendType" SG_ 1154 FRONTCAM_L2_OBJ_LAT_DISTANCE 1;
BA_ "GenSigStartValue" SG_ 1154 FRONTCAM_L3_OBJ_LAT_DISTANCE 63;
BA_ "GenSigSendType" SG_ 1154 FRONTCAM_L3_OBJ_LAT_DISTANCE 1;
BA_ "GenSigStartValue" SG_ 1154 FRONTCAM_R1_OBJ_LAT_DISTANCE 63;
BA_ "GenSigSendType" SG_ 1154 FRONTCAM_R1_OBJ_LAT_DISTANCE 1;
BA_ "GenSigStartValue" SG_ 1154 FRONTCAM_R2_OBJ_LAT_DISTANCE 63;
BA_ "GenSigSendType" SG_ 1154 FRONTCAM_R2_OBJ_LAT_DISTANCE 1;
BA_ "GenSigStartValue" SG_ 1154 FRONTCAM_R3_OBJ_LAT_DISTANCE 63;
BA_ "GenSigSendType" SG_ 1154 FRONTCAM_R3_OBJ_LAT_DISTANCE 1;
BA_ "GenSigStartValue" SG_ 1154 FRONTCAM_EGO_OBJ_LONGI_REL_SPD 1023;
BA_ "GenSigSendType" SG_ 1154 FRONTCAM_EGO_OBJ_LONGI_REL_SPD 1;
BA_ "GenSigStartValue" SG_ 1154 FRONTCAM_EGO2_OBJ_LONGI_REL_SPD 1023;
BA_ "GenSigSendType" SG_ 1154 FRONTCAM_EGO2_OBJ_LONGI_REL_SPD 1;
BA_ "GenSigStartValue" SG_ 1154 FRONTCAM_L1_OBJ_LONGI_REL_SPD 1023;
BA_ "GenSigSendType" SG_ 1154 FRONTCAM_L1_OBJ_LONGI_REL_SPD 1;
BA_ "GenSigStartValue" SG_ 1154 FRONTCAM_L2_OBJ_LONGI_REL_SPD 1023;
BA_ "GenSigSendType" SG_ 1154 FRONTCAM_L2_OBJ_LONGI_REL_SPD 1;
BA_ "GenSigStartValue" SG_ 1154 FRONTCAM_L3_OBJ_LONGI_REL_SPD 1023;
BA_ "GenSigSendType" SG_ 1154 FRONTCAM_L3_OBJ_LONGI_REL_SPD 1;
BA_ "GenSigStartValue" SG_ 1154 FRONTCAM_R1_OBJ_LONGI_REL_SPD 1023;
BA_ "GenSigSendType" SG_ 1154 FRONTCAM_R1_OBJ_LONGI_REL_SPD 1;
BA_ "GenSigStartValue" SG_ 1154 FRONTCAM_R2_OBJ_LONGI_REL_SPD 1023;
BA_ "GenSigSendType" SG_ 1154 FRONTCAM_R2_OBJ_LONGI_REL_SPD 1;
BA_ "GenSigStartValue" SG_ 1154 FRONTCAM_R3_OBJ_LONGI_REL_SPD 1023;
BA_ "GenSigSendType" SG_ 1154 FRONTCAM_R3_OBJ_LONGI_REL_SPD 1;
BA_ "GenSigStartValue" SG_ 1154 FRONTCAM_L2_OBJ_LAT_REL_SPD 127;
BA_ "GenSigSendType" SG_ 1154 FRONTCAM_L2_OBJ_LAT_REL_SPD 1;
BA_ "GenSigStartValue" SG_ 1154 FRONTCAM_L3_OBJ_LAT_REL_SPD 127;
BA_ "GenSigSendType" SG_ 1154 FRONTCAM_L3_OBJ_LAT_REL_SPD 1;
BA_ "GenSigStartValue" SG_ 1154 FRONTCAM_R1_OBJ_LAT_REL_SPD 127;
BA_ "GenSigSendType" SG_ 1154 FRONTCAM_R1_OBJ_LAT_REL_SPD 1;
BA_ "GenSigStartValue" SG_ 1154 FRONTCAM_R2_OBJ_LAT_REL_SPD 127;
BA_ "GenSigSendType" SG_ 1154 FRONTCAM_R2_OBJ_LAT_REL_SPD 1;
BA_ "GenSigStartValue" SG_ 1154 FRONTCAM_R3_OBJ_LAT_REL_SPD 127;
BA_ "GenSigSendType" SG_ 1154 FRONTCAM_R3_OBJ_LAT_REL_SPD 1;
BA_ "GenSigSendType" SG_ 1154 FRONTCAM_EGO_OBJ_HANDLE 1;
BA_ "GenSigSendType" SG_ 1154 FRONTCAM_EGO2_OBJ_HANDLE 1;
BA_ "GenSigSendType" SG_ 1154 FRONTCAM_L1_OBJ_HANDLE 1;
BA_ "GenSigSendType" SG_ 1154 FRONTCAM_L2_OBJ_HANDLE 1;
BA_ "GenSigSendType" SG_ 1154 FRONTCAM_L3_OBJ_HANDLE 1;
BA_ "GenSigSendType" SG_ 1154 FRONTCAM_R1_OBJ_HANDLE 1;
BA_ "GenSigSendType" SG_ 1154 FRONTCAM_R2_OBJ_HANDLE 1;
BA_ "GenSigSendType" SG_ 1154 FRONTCAM_R3_OBJ_HANDLE 1;
BA_ "GenSigSendType" SG_ 1154 IHM_EGO_POSITION 1;
BA_ "GenSigSendType" SG_ 1154 IHM_L1_POSITION 1;
BA_ "GenSigSendType" SG_ 1154 IHM_L2_POSITION 1;
BA_ "GenSigSendType" SG_ 1154 IHM_R1_POSITION 1;
BA_ "GenSigSendType" SG_ 661 FCAM_VRU4_TYPE 1;
BA_ "GenSigSendType" SG_ 661 FCAM_VRU5_TYPE 1;
BA_ "GenSigSendType" SG_ 661 FCAM_VRU1_TYPE 1;
BA_ "GenSigSendType" SG_ 661 FCAM_VRU2_TYPE 1;
BA_ "GenSigSendType" SG_ 661 FCAM_VRU3_TYPE 1;
BA_ "GenSigStartValue" SG_ 661 FCAM_VRU4_LONG_DIST 255;
BA_ "GenSigSendType" SG_ 661 FCAM_VRU4_LONG_DIST 1;
BA_ "GenSigStartValue" SG_ 661 FCAM_VRU2_LONG_DIST 255;
BA_ "GenSigSendType" SG_ 661 FCAM_VRU2_LONG_DIST 1;
BA_ "GenSigStartValue" SG_ 661 FCAM_VRU3_LAT_DIST 63;
BA_ "GenSigSendType" SG_ 661 FCAM_VRU3_LAT_DIST 1;
BA_ "GenSigStartValue" SG_ 661 FCAM_VRU5_LAT_DIST 63;
BA_ "GenSigSendType" SG_ 661 FCAM_VRU5_LAT_DIST 1;
BA_ "GenSigStartValue" SG_ 661 FCAM_VRU1_LONG_DIST 255;
BA_ "GenSigSendType" SG_ 661 FCAM_VRU1_LONG_DIST 1;
BA_ "GenSigStartValue" SG_ 661 FCAM_VRU3_LONG_DIST 255;
BA_ "GenSigSendType" SG_ 661 FCAM_VRU3_LONG_DIST 1;
BA_ "GenSigStartValue" SG_ 661 FCAM_VRU5_LONG_DIST 255;
BA_ "GenSigSendType" SG_ 661 FCAM_VRU5_LONG_DIST 1;
BA_ "GenSigStartValue" SG_ 661 FCAM_VRU1_LAT_DIST 63;
BA_ "GenSigSendType" SG_ 661 FCAM_VRU1_LAT_DIST 1;
BA_ "GenSigStartValue" SG_ 661 FCAM_VRU2_LAT_DIST 63;
BA_ "GenSigSendType" SG_ 661 FCAM_VRU2_LAT_DIST 1;
BA_ "GenSigStartValue" SG_ 661 FCAM_VRU4_LAT_DIST 63;
BA_ "GenSigSendType" SG_ 661 FCAM_VRU4_LAT_DIST 1;
BA_ "GenSigSendType" SG_ 661 EGO_DIR_ROAD_LANENUMBER 1;
BA_ "GenSigSendType" SG_ 661 FCAM_LEFTRIGHT_CONFIDENCE_MEA 1;
BA_ "GenSigStartValue" SG_ 661 FCAM_LEFTRIGHT_LINE_DIS_ACTUAL 2047;
BA_ "GenSigSendType" SG_ 661 FCAM_LEFTRIGHT_LINE_DIS_ACTUAL 1;
BA_ "GenSigStartValue" SG_ 661 FCAM_LEFTRIGHT_LINE_LAT_DIST 63;
BA_ "GenSigSendType" SG_ 661 FCAM_LEFTRIGHT_LINE_LAT_DIST 1;
BA_ "GenSigSendType" SG_ 661 FCAM_LEFTRIGHT_LINECOLOR 1;
BA_ "GenSigStartValue" SG_ 661 FCAM_LEFTRIGHT_LINECURVATURE_EST 65535;
BA_ "GenSigSendType" SG_ 661 FCAM_LEFTRIGHT_LINECURVATURE_EST 1;
BA_ "GenSigStartValue" SG_ 661 FCAM_LEFTRIGHT_LINECURVATURE_DER 131071;
BA_ "GenSigSendType" SG_ 661 FCAM_LEFTRIGHT_LINECURVATURE_DER 1;
BA_ "GenSigStartValue" SG_ 661 FCAM_LLANE_ROADEDG_CURVATURE_DER 131071;
BA_ "GenSigSendType" SG_ 661 FCAM_LLANE_ROADEDG_CURVATURE_DER 1;
BA_ "GenSigStartValue" SG_ 661 FCAM_RIGHTLEFT_LINECURVATURE_DER 131071;
BA_ "GenSigSendType" SG_ 661 FCAM_RIGHTLEFT_LINECURVATURE_DER 1;
BA_ "GenSigStartValue" SG_ 661 FCAM_RLANE_ROADEDG_CURVATURE_DER 131071;
BA_ "GenSigSendType" SG_ 661 FCAM_RLANE_ROADEDG_CURVATURE_DER 1;
BA_ "GenSigStartValue" SG_ 661 FCAM_LLANE_ROADEDG_CURVATURE_EST 65535;
BA_ "GenSigSendType" SG_ 661 FCAM_LLANE_ROADEDG_CURVATURE_EST 1;
BA_ "GenSigStartValue" SG_ 661 FCAM_RIGHTLEFT_LINECURVATURE_EST 65535;
BA_ "GenSigSendType" SG_ 661 FCAM_RIGHTLEFT_LINECURVATURE_EST 1;
BA_ "GenSigStartValue" SG_ 661 FCAM_RLANE_ROADEDG_CURVATURE_EST 65535;
BA_ "GenSigSendType" SG_ 661 FCAM_RLANE_ROADEDG_CURVATURE_EST 1;
BA_ "GenSigStartValue" SG_ 661 FCAM_LLANE_ROADEDG_DIST_ACTUAL 2047;
BA_ "GenSigSendType" SG_ 661 FCAM_LLANE_ROADEDG_DIST_ACTUAL 1;
BA_ "GenSigStartValue" SG_ 661 FCAM_RIGHTLEFT_LINE_DIST_ACTUAL 2047;
BA_ "GenSigSendType" SG_ 661 FCAM_RIGHTLEFT_LINE_DIST_ACTUAL 1;
BA_ "GenSigStartValue" SG_ 661 FCAM_RLANE_ROADEDG_DIST_ACTUAL 2047;
BA_ "GenSigSendType" SG_ 661 FCAM_RLANE_ROADEDG_DIST_ACTUAL 1;
BA_ "GenSigStartValue" SG_ 661 FCAM_LEFTRIGHT_LINEHEADINGANGLE 4095;
BA_ "GenSigSendType" SG_ 661 FCAM_LEFTRIGHT_LINEHEADINGANGLE 1;
BA_ "GenSigStartValue" SG_ 661 FCAM_LLANE_ROADEDG_HEADINGANGLE 4095;
BA_ "GenSigSendType" SG_ 661 FCAM_LLANE_ROADEDG_HEADINGANGLE 1;
BA_ "GenSigStartValue" SG_ 661 FCAM_RIGHTLEFT_LINEHEADINGANGLE 4095;
BA_ "GenSigSendType" SG_ 661 FCAM_RIGHTLEFT_LINEHEADINGANGLE 1;
BA_ "GenSigStartValue" SG_ 661 FCAM_RLANE_ROADEDG_HEADINGANGLE 4095;
BA_ "GenSigSendType" SG_ 661 FCAM_RLANE_ROADEDG_HEADINGANGLE 1;
BA_ "GenSigStartValue" SG_ 661 FCAM_RIGHTLEFT_LINE_LAT_DIST 63;
BA_ "GenSigSendType" SG_ 661 FCAM_RIGHTLEFT_LINE_LAT_DIST 1;
BA_ "GenSigSendType" SG_ 661 FCAM_LEFTRIGHT_LINEVIEW_RANGEEND 1;
BA_ "GenSigSendType" SG_ 661 FCAM_LEFTRIGHT_LINEVIEW_RANGESTR 1;
BA_ "GenSigSendType" SG_ 661 FCAM_LLANE_ROADEDG_CONFIDENC_MEA 1;
BA_ "GenSigSendType" SG_ 661 FCAM_LLANE_ROADEDG_VIEW_RANGEEND 1;
BA_ "GenSigSendType" SG_ 661 FCAM_LLINE_CONFIDENCE_MEA 1;
BA_ "GenSigSendType" SG_ 661 FCAM_NEXTLEFTLINE_CONFIDENCE_MEA 1;
BA_ "GenSigSendType" SG_ 661 FCAM_NEXTRIGHTLINE_CONFIDENC_MEA 1;
BA_ "GenSigSendType" SG_ 661 FCAM_RIGHTLEFT_CONFIDENCE_MEA 1;
BA_ "GenSigSendType" SG_ 661 FCAM_RLANE_ROADEDG_CONFIDENC_MEA 1;
BA_ "GenSigSendType" SG_ 661 FCAM_RLANE_ROADEDG_VIEW_RANGEEND 1;
BA_ "GenSigSendType" SG_ 661 FCAM_RLINE_CONFIDENCE_MEA 1;
BA_ "GenSigSendType" SG_ 661 FCAM_LEFTRIGHT_LINEDETECTIONSTS 1;
BA_ "GenSigSendType" SG_ 661 FCAM_LEFTRIGHT_LINEMARKERQUALITY 1;
BA_ "GenSigSendType" SG_ 661 FCAM_LEFTRIGHT_LINETYPE 1;
BA_ "GenSigSendType" SG_ 661 FCAM_RIGHTLEFT_LINETYPE 1;
BA_ "GenSigSendType" SG_ 661 FCAM_RIGHTLEFT_LINEDETECTIONSTS 1;
BA_ "GenSigSendType" SG_ 661 FCAM_RIGHTLEFT_LINECOLOR 1;
BA_ "GenSigSendType" SG_ 661 FCAM_LLANE_ROADEDG_MARKERQUALITY 1;
BA_ "GenSigSendType" SG_ 661 FCAM_RIGHTLEFT_LINEMARKERQUALITY 1;
BA_ "GenSigSendType" SG_ 661 FCAM_RLANE_ROADEDG_MARKERQUALITY 1;
BA_ "GenSigSendType" SG_ 661 FCAM_LLANE_ROADEDG_DET_STATUS 1;
BA_ "GenSigSendType" SG_ 661 FCAM_LLANE_ROADEDG_VIEW_RANSTART 1;
BA_ "GenSigSendType" SG_ 661 FCAM_RLANE_ROADEDG_VIEW_RANSTART 1;
BA_ "GenSigStartValue" SG_ 661 FCAM_LLANE_ROADEDGETYPE 5;
BA_ "GenSigSendType" SG_ 661 FCAM_LLANE_ROADEDGETYPE 1;
BA_ "GenSigSendType" SG_ 661 FCAM_LLINE_VALIDFORLKA 1;
BA_ "GenSigSendType" SG_ 661 FCAM_RIGHTLEFT_LINEVIEW_RANGEEND 1;
BA_ "GenSigSendType" SG_ 661 FCAM_RIGHTLEFT_LINEVIEW_RANGESTR 1;
BA_ "GenSigSendType" SG_ 661 FCAM_OBJECTCROSSING 1;
BA_ "GenSigSendType" SG_ 661 FCAM_RLANE_ROADEDG_DET_STATUS 1;
BA_ "GenSigStartValue" SG_ 661 FCAM_RLANE_ROADEDGETYPE 5;
BA_ "GenSigSendType" SG_ 661 FCAM_RLANE_ROADEDGETYPE 1;
BA_ "GenSigSendType" SG_ 661 FCAM_RLINE_VALIDFORLKA 1;
BA_ "GenSigSendType" SG_ 641 FREE_4 0;
BA_ "Event trans." SG_ 641 AEB_PREFILL_REQUEST 0;
BA_ "GenSigSendType" SG_ 641 AEB_PREFILL_REQUEST 0;
BA_ "GenSigStartValue" SG_ 641 AEB_STATE_A 2;
BA_ "GenSigSendType" SG_ 641 AEB_STATE_A 0;
BA_ "Event trans." SG_ 641 ADAS_LONGI_ACCEL_REQUEST 0;
BA_ "GenSigStartValue" SG_ 641 ADAS_LONGI_ACCEL_REQUEST 1200;
BA_ "GenSigSendType" SG_ 641 ADAS_LONGI_ACCEL_REQUEST 0;
BA_ "GenSigSendType" SG_ 641 E2E_ALIVE_LRCF_DATA_2 0;
BA_ "GenSigSendType" SG_ 641 E2E_CRC_LRCF_DATA_2 0;
BA_ "GenSigSendType" SG_ 641 DRIVER_STEERING_WHEEL_INTERACT 0;
BA_ "GenSigStartValue" SG_ 641 YAW_RATE_REQUEST_SETPOINT 1000;
BA_ "GenSigSendType" SG_ 641 YAW_RATE_REQUEST_SETPOINT 0;
BA_ "GenSigSendType" SG_ 641 TORQUE_FACTOR_REQUEST 0;
BA_ "GenSigSendType" SG_ 641 DST_WIDTH_EGO_LINE 0;
BA_ "GenSigSendType" SG_ 641 ACTIVATED_LATERAL_ASSIST_MODE 0;
BA_ "GenSigSendType" SG_ 641 PERCEPTION_SYSTEM_STATE 0;
BA_ "GenSigSendType" SG_ 641 LANE_ASSIST_STATE 0;
BA_ "GenSigSendType" SG_ 641 PERCEPTION_STATE 0;
BA_ "GenSigStartValue" SG_ 641 ACC_POTENTIAL_ACCELERATION_REQ 1100;
BA_ "GenSigSendType" SG_ 641 ACC_POTENTIAL_ACCELERATION_REQ 0;
BA_ "GenSigStartValue" SG_ 641 ACC_JERK_MIN_SETPOINT 25;
BA_ "GenSigSendType" SG_ 641 ACC_JERK_MIN_SETPOINT 0;
BA_ "Event trans." SG_ 641 ADAS_LONGI_ACCEL_TYPE 0;
BA_ "GenSigSendType" SG_ 641 ADAS_LONGI_ACCEL_TYPE 0;
BA_ "GenSigSendType" SG_ 641 LPA_PERCEPTION_STATE 0;
BA_ "GenSigSendType" SG_ 1153 FREE_4 0;
BA_ "Event trans." SG_ 1153 AEB_LIMITED 0;
BA_ "GenSigSendType" SG_ 1153 AEB_LIMITED 0;
BA_ "Event trans." SG_ 1153 FCW2_REQUEST 0;
BA_ "GenSigSendType" SG_ 1153 FCW2_REQUEST 0;
BA_ "GenSigSendType" SG_ 1153 FRONT_CAMERA_BLIND 0;
BA_ "GenSigSendType" SG_ 1153 FRONT_RADAR_BLIND 0;
BA_ "GenSigSendType" SG_ 1153 HMI_AEB_BRAKING_ACTIVE 0;
BA_ "GenSigSendType" SG_ 1153 FCW2_SIDEALERT 0;
BA_ "GenSigStartValue" SG_ 1153 FCW_STATE_A 2;
BA_ "GenSigSendType" SG_ 1153 FCW_STATE_A 0;
BA_ "GenSigSendType" SG_ 1153 EBF_ACCELERATION_TYPE 0;
BA_ "GenSigSendType" SG_ 1153 E2E_CRC_LRCF_DATA_3 0;
BA_ "GenSigSendType" SG_ 1153 E2E_ALIVE_LRCF_DATA_3 0;
BA_ "GenSigSendType" SG_ 1153 FCW1_TARGET_PRESENT 0;
BA_ "GenSigSendType" SG_ 1153 FCW1_TARGET_SPEED 0;
BA_ "GenSigSendType" SG_ 1153 FCW1_HEADWAY 0;
BA_ "GenSigSendType" SG_ 1153 AEB_HAPTIC_CRITICAL 0;
BA_ "GenSigSendType" SG_ 1153 AEB_DETECTION_LIMITED 0;
BA_ "GenSigSendType" SG_ 1153 DATA_TRANSFER_STATUS 0;
BA_ "Event trans." SG_ 1153 ERROR_TYPE 0;
BA_ "GenSigSendType" SG_ 1153 ERROR_TYPE 0;
BA_ "GenSigSendType" SG_ 1153 READINESS_STATUS 0;
BA_ "GenSigSendType" SG_ 1153 ERROR_REASON 0;
BA_ "Event trans." SG_ 1153 SAFETY_LRCF_READY_STATE 0;
BA_ "GenSigSendType" SG_ 1153 SAFETY_LRCF_READY_STATE 0;
BA_ "Event trans." SG_ 1153 LRCF_UPDATE_STATUS 0;
BA_ "GenSigSendType" SG_ 1153 LRCF_UPDATE_STATUS 0;
BA_ "GenSigSendType" SG_ 1409 LKA_STATE 0;
BA_ "GenSigSendType" SG_ 1409 RCTA_STATE 0;
BA_ "GenSigSendType" SG_ 1409 FREE_4 0;
BA_ "GenSigSendType" SG_ 1409 RCTA_WARNINGSTATE_LEFT 0;
BA_ "GenSigSendType" SG_ 1409 RCTA_WARNINGSTATE_RIGHT 0;
BA_ "GenSigSendType" SG_ 1409 BLINDSPOT_DETECTION_STATUS 0;
BA_ "GenSigSendType" SG_ 1409 BLINDSPOTDETECTIONLEFTALERTRQST 0;
BA_ "GenSigSendType" SG_ 1409 BLINDSPOTDETECTIONRIGHTALERTRQST 0;
BA_ "GenSigStartValue" SG_ 1409 FRONT_CAMERA_SPEED_LIMIT 254;
BA_ "GenSigSendType" SG_ 1409 FRONT_CAMERA_SPEED_LIMIT 0;
BA_ "GenSigStartValue" SG_ 1409 FRONT_CAMERA_TRAFFIC_SIGN_DIST 500;
BA_ "GenSigSendType" SG_ 1409 FRONT_CAMERA_TRAFFIC_SIGN_DIST 0;
BA_ "GenSigStartValue" SG_ 1409 FRONT_CAMERA_SPEED_LIMIT_AGE 509;
BA_ "GenSigSendType" SG_ 1409 FRONT_CAMERA_SPEED_LIMIT_AGE 0;
BA_ "GenSigSendType" SG_ 1409 FRONT_CAMERA_SPEED_LIMIT_SOURCE 0;
BA_ "GenSigSendType" SG_ 1409 FRONT_CAMERA_SPEED_LIMIT_SHAPE 0;
BA_ "GenSigSendType" SG_ 1409 FRONT_CAMERA_CONDSPEED_LIMIT 0;
BA_ "GenSigStartValue" SG_ 1409 FRONT_CAMERA_CONDSPEED_LIMIT_AGE 509;
BA_ "GenSigSendType" SG_ 1409 FRONT_CAMERA_CONDSPEED_LIMIT_AGE 0;
BA_ "GenSigSendType" SG_ 1409 FRONT_CAMERA_CONDSPEED_LIMIT_TYP 0;
BA_ "GenSigStartValue" SG_ 1409 FRONT_CAMERA_SIGN_STATUS 3;
BA_ "GenSigSendType" SG_ 1409 FRONT_CAMERA_SIGN_STATUS 0;
BA_ "GenSigSendType" SG_ 1409 FRONT_CAMERA_TRAFFICSIGN_RAW 0;
BA_ "GenSigSendType" SG_ 1409 FRONT_CAMERA_TRAFFICSIGN_RAW_SUP 0;
BA_ "GenSigSendType" SG_ 1409 FRONT_CAMERA_ROAD_TYPE_RAW 0;
BA_ "GenSigSendType" SG_ 1409 FRONT_CAMERA_ROAD_TYPE 0;
BA_ "GenSigSendType" SG_ 1409 FRONT_CAMERA_TRAFFIC_SIGN 0;
BA_ "GenSigSendType" SG_ 1409 LONGITUDINAL_DRIVING_STINFO 0;
BA_ "GenSigSendType" SG_ 1409 LAS_LEFT_LINE_STATE 0;
BA_ "GenSigSendType" SG_ 1409 LAS_RIGHT_LINE_STATE 0;
BA_ "GenSigSendType" SG_ 1409 LAS_INTERRUPT_ALERT 0;
BA_ "GenSigSendType" SG_ 1409 LAS_DRIVER_CONTROL_ALERT 0;
BA_ "GenSigSendType" SG_ 1409 HIGH_BEAM_ASSIST_REQ_FROM_CAMERA 0;
BA_ "GenSigSendType" SG_ 1409 HIGH_BEAM_ASSIST_CONDITION 0;
BA_ "GenSigSendType" SG_ 1409 HIGH_BEAM_ASSIST_FAULT 0;
BA_ "GenSigStartValue" SG_ 1409 LIGHTED_ZONE_DETECTED 3;
BA_ "GenSigSendType" SG_ 1409 LIGHTED_ZONE_DETECTED 0;
BA_ "GenSigSendType" SG_ 1409 LAS_FRONT_SENSOR_BLOCKAGE_STATUS 0;
BA_ "GenSigSendType" SG_ 1409 LAS_REAR_SENSOR_BLOKAGE_STS 0;
BA_ "GenSigSendType" SG_ 1409 LAS_HAPTIC_ALERT_REQ 0;
BA_ "GenSigSendType" SG_ 1409 E2E_CRC_LRCF_DATA_4 0;
BA_ "GenSigSendType" SG_ 1409 E2E_ALIVE_LRCF_DATA_4 0;
BA_ "GenSigSendType" SG_ 1409 VRU_IN_EXTENDED_FRONT_AREA 0;
BA_ "Manufacturer" "Stellantis";
BA_ "NmType" "NmAsr";
BA_ "BusType" "CAN FD";

BA_ "DBName" "FD CAN";
VAL_ 121 Rep_UCE 0 "NOT_ACKNOWLEDGED" 1 "ACKNOWLEDGED";
VAL_ 592 ESC_STATUS 0 "Disabled" 1 "Enabled" 2 "Reserved" 3 "Reserved" 4 "Reserved" 5 "Reserved" 6 "Reserved" 7 "Reserved";
VAL_ 592 TCS_STATUS 0 "Disabled" 1 "Enabled";
VAL_ 592 DTC_STATE 0 "Not Active" 1 "Active";
VAL_ 592 ESC_BRAKE_STATE 0 "Inactive" 1 "Active";
VAL_ 592 ESC_TCS_STATE 0 "Not Active" 1 "Active";
VAL_ 592 TCS_BRAKE_STATE 0 "Not Active" 1 "Active";
VAL_ 592 TCS_STATE 0 "Not Active" 1 "Active";
VAL_ 592 EPB_FAILSTATUS 0 "No Failure" 1 "Minor Failure" 2 "Major Failure" 3 "Reserved";
VAL_ 592 EPB_SECUREMENT_RELEASE_STATUS 0 "AUTHORIZED" 1 "NOT AUTHORIZED";
VAL_ 592 EPB_STATE 0 "Released" 1 "Applied" 2 "DynamicBrkESC" 3 "DynamicBrkEPB" 4 "Emergency_Braking" 5 "Applying" 6 "Re_Clamping" 7 "Adjuste_Mode" 8 "Releasing" 9 "Unknown" 10 "Initializing" 11 "Unavailable" 12 "Reserved" 13 "Reserved" 14 "Reserved" 15 "Reserved";
VAL_ 592 EPB_SWITCH_POSITION_STATE 0 "No request" 1 "Push" 2 "Pull" 3 "Fault";
VAL_ 592 VEHICLE_SECUREMENT_STATE 0 "NOT SECURE" 1 "SECURE" 2 "UNKNOWN" 3 "RESERVED";
VAL_ 592 EPB_WHEEL_TORQUE_LIMITATION_REQ 0 "No Request" 1 "Request";
VAL_ 592 BRAKE_EMERGENCY_SIGNAL_REQUEST 0 "No Request" 1 "Request";
VAL_ 592 BRAKE_ASSISTANCE_FAILSTATUS 0 "No Fault" 1 "Minor fault" 2 "Brake Assist fault" 3 "Brake System fault";
VAL_ 592 AUTO_HOLD_STATE 0 "Not Active" 1 "Active" 2 "Fault" 3 "Reserved" 4 "Reserved" 5 "Reserved" 6 "Reserved" 7 "Reserved";
VAL_ 592 AEB_BRAKING_STATUS 0 "Nominal" 1 "Limited" 2 "Inhibited" 3 "Unavailable" 4 "Fault" 5 "Reserved" 6 "Reserved" 7 "Reserved";
VAL_ 592 AEB_BRAKING_ACKNOWLEDGE 0 "Inactive" 1 "Prefill" 2 "Haptic" 3 "AEB" 4 "SBA" 5 "Hold" 6 "Reserved" 7 "Reserved";
VAL_ 592 LXA_SAFETY_DYNVHL_STATE 0 "Inactive" 1 "Active";
VAL_ 592 STEERING_COLLABORATI_YAWCTRL_REQ 0 "Unavailable" 1 "Available" 2 "Active" 3 "Fault";
VAL_ 592 STEERING_CONTROL_AUTOMATIC_REQ 0 "Unavailable" 1 "Available" 2 "Active" 3 "Fault";
VAL_ 592 STEERING_CONTROL_COLLABORATI_REQ 0 "Unavailable" 1 "Available" 2 "Active" 3 "Fault";
VAL_ 592 SBA_TRIGGER 0 "Unavailable" 1 "Inactive" 2 "Active" 3 "Fault";
VAL_ 592 ACC_MOTION_CONTROL_STATE 0 "Unavailable" 1 "Available" 2 "Active_Effective" 3 "Active_Not_Effective" 4 "Reserved" 5 "Active_Brake_Only" 7 "Fault" 6 "Reserved";
VAL_ 337 VEHICLE_MOTION_DIRECTION 0 "UNAVAILABLE" 1 "STANDSTILL" 2 "FORWARD" 3 "BACKWARD" 4 "FAULT" 5 "Reserved" 6 "Reserved" 7 "Reserved";
VAL_ 337 WHEEL_ROLLING_DIRECTION_FL 0 "Unavailable" 1 "Standstill" 2 "Forward" 3 "Backward";
VAL_ 337 WHEEL_ROLLING_DIRECTION_FR 0 "Unavailable" 1 "Standstill" 2 "Forward" 3 "Backward";
VAL_ 337 WHEEL_ROLLING_DIRECTION_RL 0 "Unavailable" 1 "Standstill" 2 "Forward" 3 "Backward";
VAL_ 337 WHEEL_ROLLING_DIRECTION_RR 0 "Unavailable" 1 "Standstill" 2 "Forward" 3 "Backward";
VAL_ 337 WHEEL_ROTATION_PULSE_FL_FAIL_STS 0 "NO_FAULT" 1 "FAULT";
VAL_ 337 WHEEL_ROTATION_PULSE_FR_FAIL_STS 0 "NO_FAULT" 1 "FAULT";
VAL_ 337 WHEEL_ROTATION_PULSE_RL_FAIL_STS 0 "NO_FAULT" 1 "FAULT";
VAL_ 337 WHEEL_ROTATION_PULSE_RR_FAIL_STS 0 "NO_FAULT" 1 "FAULT";
VAL_ 337 BRAKE_STATE 0 "Unavailable" 1 "Inactive" 2 "Active" 3 "Fault";
VAL_ 337 STOP_LIGHTS_ACTIVATION_REQUEST 0 "NO REQUEST" 1 "REQUEST";
VAL_ 337 SAFESTOP_BRAKING_STATE 0 "Unavailable" 1 "Inactive" 2 "Active" 3 "Vehicle Hold" 4 "Fault" 5 "Reserved" 6 "Reserved" 7 "Reserved";
VAL_ 337 BRAKE_PEDAL_PRESSED_STATE 0 "Unavailable" 1 "Released" 2 "Pressed" 3 "Fault";
VAL_ 337 BAS_STATE 0 "Inactive" 1 "Active";
VAL_ 337 ABS_STATE 0 "Inactive" 1 "Active";
VAL_ 337 EBD_STATE 0 "Inactive" 1 "Active";
VAL_ 337 ABS_WHEEL_FRONT_LEFT_STATE 0 "Not Active" 1 "Active";
VAL_ 337 ABS_WHEEL_FRONT_RIGHT_STATE 0 "Not Active" 1 "Active";
VAL_ 337 ABS_WHEEL_REAR_LEFT_STATE 0 "Not Active" 1 "Active";
VAL_ 337 ABS_WHEEL_REAR_RIGHT_STATE 0 "Not Active" 1 "Active";
VAL_ 337 ROAD_SLOPE_ACCURACY_STATE 0 "HIGH" 1 "MID" 2 "LOW" 3 "UNDEFINED";
VAL_ 337 EBD_FAILSTATUS 0 "NO FAULT" 1 "FAULT";
VAL_ 337 ABS_FAILSTATUS 0 "NO FAULT" 1 "FAULT";
VAL_ 340 STEERING_ASSIST_FAILSTATUS 0 "Nominal" 1 "Minor Fault" 2 "Important Fault" 3 "Major SBW Fault" 4 "Critical SBW Fault" 5 "Check Alert chain SBW " 6 "Overheating" 7 "Reserved";
VAL_ 340 STEERING_ASSIST_STATUS 0 "OFF" 1 "ON SBW" 2 "Easy Access SBW" 3 "Alignement SBW" 4 "Paired" 5 "Drive" 6 "Reserved" 7 "Reserved";
VAL_ 340 STEERING_POWERSUPPLY_BOOST_REQ 0 "No Request" 1 "Request level 1" 2 "Request level 2" 3 "Reserved";
VAL_ 340 LKA_STEERING_ACTUATION_STATE 0 "Inactive" 1 "Active";
VAL_ 340 LKA_STEERING_AVAILABILITY_STATE 0 "Available" 1 "Long Unavailability" 2 "Fault" 3 "Reserved";
VAL_ 340 LXA_STEERING_LIMITATION_STATE 0 "Inactive" 1 "Active";
VAL_ 340 LXA_STEERING_STATE 0 "Unavailable" 1 "Available" 2 "Active" 3 "Fault";
VAL_ 340 STEERINGWHEEL_ANGLE_CAL_FRT_STS 0 "Not calibrated" 1 "Calibration in progress" 2 "Calibrated and accurate" 3 "Reserved";
VAL_ 340 STEERINGWHEEL_ANGLE_REL_FRT_STE 0 "Initialization" 1 "Offset initialization request" 2 "Offset search authorization" 3 "Offset used" 4 "Fault" 5 "Reserved" 6 "Reserved" 7 "Reserved";
VAL_ 340 STEERINGWHEEL_ANGLE_FRONT_TYPE 0 "Unavailable" 1 "Absolute" 2 "Relative" 3 "Reserved";
VAL_ 1406 NM_Frames 0 "Initialization" 1 "One_frame" 2 "Two_frames" 3 "Three_frames";
VAL_ 1406 Status_DTC 0 "DISAPPEARANCE" 1 "APPEARANCE";
VAL_ 1406 DTC_Format_Identifier 0 "SAE_J2012_DA_DTCFormat_00" 1 "ISO_14229_1_DTCFormat" 2 "SAE_J1939_73_DTCFormat" 3 "ISO_11992_4_DTCFormat" 4 "SAE_J2012_DA_DTCFormat_04";
VAL_ 951 AEB_HAPTIC_REQUEST 0 "False" 1 "True";
VAL_ 951 ACC_MODE_CHOICE_REQ 0 "AccChoice" 1 "NccChoice" 2 "PaccChoice" 3 "Reserved";
VAL_ 951 ACC_AVAILABILITY_FOR_SWITCH 0 "ACC_AVAILABLE" 1 "ACC_UNAVAILABLE";
VAL_ 951 ACC_TAKEOVER_REQUEST 0 "No Request" 1 "Request after non critical failure" 2 "Request after critical failure" 3 "Reserved";
VAL_ 951 BLINDSPOTDETECTION_DRIVERREQUEST 0 "NotRequested" 1 "Requested ";
VAL_ 951 MAIN_LATERAL_ST_INFO 0 "Unavailable" 1 "Waiting" 2 "Suspended" 3 "InProgress" 4 "Defect" 5 "Reserved" 6 "Reserved" 7 "HandsOnWheelNeeded";
VAL_ 951 MAIN_LONGITUDINAL_STINFO 0 "LongiDisabled" 1 "LongiUnavailable" 2 "AccActive" 3 "LongiSuspended" 4 "AccBrakeOnly" 5 "AccActiveStop" 6 "NccActive" 7 "Reserved";
VAL_ 951 WPP_DRIVER_INHIBITION_REQUEST 0 "Inhibit" 1 "Enable";
VAL_ 951 AEB_HMI_READY 0 "FALSE" 1 "TRUE";
VAL_ 951 FCW_HMI_READY 0 "FALSE" 1 "TRUE";
VAL_ 951 FCW_HMI_SETTING 0 "CLOSE" 1 "NORMAL" 2 "FAR" 3 "Reserved";
VAL_ 951 AEB_DRIVER_ATTENTIVE 0 "FALSE" 1 "TRUE";
VAL_ 951 AEB_ROAD_FRICTION 0 "NORMAL" 1 "REDUCED";
VAL_ 951 AEB_HMI_LIMITATION 0 "NotUsed" 1 "NoDecel" 2 "DecelLimited" 3 "Nominal";
VAL_ 951 LONGITUDINAL_SPEED_SETPOINT 32767 "NoSpeed";
VAL_ 951 ELKS_SELECTION_REQ 0 "NotSelected" 1 "Selected";
VAL_ 951 FCW_SETTING 0 "REDUCED" 1 "CLOSE" 2 "NORMAL" 3 "FAR";
VAL_ 951 LRCF_CANCEL_REQ 0 "NO REQUEST" 1 "REQUEST";
VAL_ 951 LRCF_DCTYPE 0 "CAL" 1 "FW" 2 "CAL + FW" 3 "UNAVAILABLE";
VAL_ 951 LRCF_TRANSFER_READINESS_REQ 0 "NO_REQUEST" 1 "REQUEST";
VAL_ 951 LPA_STATE_INFO 0 "INHIBITED" 1 "WAITING" 2 "ACTIVE" 3 "DEFECT";
VAL_ 951 VHL_DL_OR_TX_ACTIVE 0 "Not_active" 1 "Download_active" 2 "Transfert_acive" 3 "Not_used";
VAL_ 951 OTA_UPDATE_STATUS 0 "No_FOTA_Event" 1 "Downloading_Package_from_Backend" 2 "Passing_Images_to_Big_Target_ECUs" 3 "Waiting_for_HMI_Acceptance" 4 "Installing_FOTA_Updated" 5 "Successful_FOTA_Update" 6 "FOTA_Failure_Rollback_Successful" 7 "FOTA_Failure_Complete" 8 "Build_Vehicle_Library" 9 "Check_Campaign_Availability" 10 "Check_Download_Conditions" 11 "Validate_Vehicle_Package" 12 "Double_Check_Manifest" 13 "Initiate_Authenticated_Diagnostic_session" 14 "Ready_State" 15 "Rollback";
VAL_ 951 ELKS_COCKPIT_FAILURE 0 "NoFailure" 1 "Failure";
VAL_ 951 ACC_MAIN_ST_INFO 0 "Unavailable" 1 "Waiting" 2 "Suspended" 3 "AccInProgress" 4 "NccInProgress" 5 "BrakeOnly" 6 "WaitingForBreakRelease" 7 "ActiveStopAutoGoAllowed" 8 "ActiStopAutoGoPrevented" 9 "Defect" 10 "Reserved" 11 "Reserved" 12 "Reserved" 13 "Reserved" 14 "Reserved" 15 "Reserved";
VAL_ 951 ALERT_SOUND_LOCALIZATION 0 "Wheel" 1 "Front Left" 2 "Front Right" 3 "Rear Left " 4 "Rear Right" 5 "Touch Screen" 6 "Magic touch" 7 "Front Center" 8 "Left Right" 9 "Center" 10 "Invalid" 11 "Reserved" 12 "Reserved" 13 "Reserved" 14 "Reserved" 15 "Reserved";
VAL_ 951 SL_SPEED_SETPOINT_DUA 0 "No Speed";
VAL_ 951 SL_ACTIVATION_REQUEST 0 "Deactivated" 1 "Activated";
VAL_ 951 CC_ACTIVATION_REQUEST 0 "Deactivated" 1 "Activated";
VAL_ 951 CC_SPEED_SETPOINT_DUA 0 "No Speed";
VAL_ 951 REGULATION_LONGI_TYPE 0 "None" 1 "SL" 2 "CC";
VAL_ 951 LPA_ST_INFO 0 "Inhibited" 1 "Waiting" 2 "Active" 3 "Defect";
VAL_ 951 DDMS_STATE 0 "Unavailable" 1 "DMS_INITIALIZATION" 2 "DMS_UNSELECTED" 3 "DMS_FULLY_OPERATIONAL" 4 "DMS_OPERATIONAL_FROZEN" 5 "DMS_OPERATIONAL_DEGRADED" 6 "DMS_FAULT" 7 "RESERVED";
VAL_ 951 DDMS_FOV_AREA 0 "Unavailable" 1 "TSA" 2 "DRTA" 3 "NDRTA" 4 "RESERVED_1" 5 "RESERVED_2" 6 "RESERVED_3" 7 "INVALID";
VAL_ 951 DDMS_EYE_STATUS 0 "Unavailable" 1 "OpenEyesDetected" 2 "ClosedEyesDetected" 3 "MicroSleepDetected" 4 "SleepDetected" 5 "RESERVED_1" 6 "RESERVED_2" 7 "INVALID";
VAL_ 951 DDMS_DROWSINESS_LEVEL 0 "Unavailable" 1 "Level1" 2 "Level2" 3 "Level3" 4 "Level4" 5 "RESERVED_1" 6 "RESERVED_2" 7 "INVALID";
VAL_ 951 DDMS_DISTRACTION_LEVEL 0 "Unavailable" 1 "Level1" 2 "Level2" 3 "Level3" 4 "Level4" 5 "RESERVED_1" 6 "RESERVED_2" 7 "INVALID";
VAL_ 951 DDM_SAFETY_MODE_REQUEST 0 "NotRequested" 1 "RequestedDueToDistraction" 2 "RequestedDueToDrowsiness" 3 "RESERVED";
VAL_ 1719 RCTA_DRIVER_INHIBITION_REQUEST 0 "Inhibit" 1 "Enable";
VAL_ 1719 ACC_TIV_SETPOINT 0 "NO_TIV" 1 "FAR_AWAY" 2 "NORMAL" 3 "CLOSE";
VAL_ 1719 MAIN_AUTOMATION_ST_INFO 0 "MAL_OFF" 1 "MAL_ACC" 2 "MAL_HIA" 3 "MAL_LPA" 4 "MAL_Drive" 5 "MAL_Stop_in_Lane" 6 "MAL_Safe_Stop" 7 "RESERVED";
VAL_ 633 ACC_STATE_INFO_FOR_CHASSIS 0 "Inactive" 1 "Active" 2 "ActiveBrakeOnly" 3 "ActiveStandstill";
VAL_ 633 PACC_BEVENT_IN_PROGRESS 0 "NO_REQUEST" 1 "REQUEST";
VAL_ 633 GPAC_BINHIB_ACCEL_BEND_REQ 0 "ACCBendStrategyON" 1 "ACCBendStrategyInhibitedByPACC";
VAL_ 1154 IHM_R2_POSITION 0 "None" 1 "Object_Position1" 2 "Object_Position2";
VAL_ 1154 FRONTCAM_EGO_OBJ_TYPE 0 "None" 1 "Car" 2 "Truck" 3 "Motorbike" 4 "Unknown" 5 "Reserved" 6 "Reserved" 7 "Reserved";
VAL_ 1154 FRONTCAM_EGO2_OBJ_TYPE 0 "None" 1 "Car" 2 "Truck" 3 "Motorbike" 4 "Unknown" 5 "Reserved" 6 "Reserved" 7 "Reserved";
VAL_ 1154 FRONTCAM_L1_OBJ_TYPE 0 "None" 1 "Car" 2 "Truck" 3 "Motorbike " 4 "Unknown" 5 "Reserved" 6 "Reserved" 7 "Reserved";
VAL_ 1154 FRONTCAM_L2_OBJ_TYPE 0 "None" 1 "Car" 2 "Truck" 3 "Motorbike" 4 "Unknown" 5 "Reserved" 6 "Reserved" 7 "Reserved";
VAL_ 1154 FRONTCAM_L3_OBJ_TYPE 0 "None" 1 "Car" 2 "Truck" 3 "Motorbike" 4 "Unknown" 5 "Reserved" 6 "Reserved" 7 "Reserved";
VAL_ 1154 FRONTCAM_R1_OBJ_TYPE 0 "None" 1 "Car" 2 "Truck" 3 "Motorbike" 4 "Unknown" 5 "Reserved" 6 "Reserved" 7 "Reserved";
VAL_ 1154 FRONTCAM_R2_OBJ_TYPE 0 "None" 1 "Car" 2 "Truck" 3 "Motorbike" 4 "Unknown" 5 "Reserved" 6 "Reserved" 7 "Reserved";
VAL_ 1154 FRONTCAM_R3_OBJ_TYPE 0 "None" 1 "Car" 2 "Truck" 3 "Motorbike" 4 "Unknown" 5 "Reserved" 6 "Reserved" 7 "Reserved";
VAL_ 1154 FRONTCAM_EGO_OBJ_CONFID_OBJ 0 "Low_None" 1 "Mid" 2 "High" 3 "Unavailable";
VAL_ 1154 FRONTCAM_EGO2_OBJ_CONFID_OBJ 0 "Low_None" 1 "Mid" 2 "High" 3 "Unavailable";
VAL_ 1154 FRONTCAM_L1_OBJ_CONFID_OBJ 0 "Low_None" 1 "Mid" 2 "High" 3 "Unavailable";
VAL_ 1154 FRONTCAM_L2_OBJ_CONFID_OBJ 0 "Low_None" 1 "Mid" 2 "High" 3 "Unavailable";
VAL_ 1154 FRONTCAM_L3_OBJ_CONFID_OBJ 0 "Low_None" 1 "Mid" 2 "High" 3 "Unavailable";
VAL_ 1154 FRONTCAM_R1_OBJ_CONFID_OBJ 0 "Low_None" 1 "Mid" 2 "High" 3 "Unavailable";
VAL_ 1154 FRONTCAM_R2_OBJ_CONFID_OBJ 0 "Low_None" 1 "Mid" 2 "High" 3 "Unavailable";
VAL_ 1154 FRONTCAM_R3_OBJ_CONFID_OBJ 0 "Low_None" 1 "Mid" 2 "High" 3 "Unavailable";
VAL_ 1154 IHM_EGO_POSITION 0 "None" 1 "Object_Position1 " 2 "Object_Position2" 3 "Object_Position3" 4 "Object_Position4" 5 "Object_Position5" 6 "Object_Position6" 7 "Object_Position7" 8 "Object_Position8" 9 "Object_Position9" 10 "Object_Position10" 11 "Object_Position11" 12 "Object_Position12" 13 "Object_Position13" 14 "Object_Position14" 15 "Object_Position15" 16 "Object_Position16" 17 "Object_Position17" 18 "Object_Position18" 19 "Object_Position19" 20 "Object_Position20" 21 "Object_Position21" 22 "Object_Position22" 23 "Object_Position23" 24 "Object_Position24" 25 "Object_Position25" 26 "Object_Position26" 27 "Object_Position27" 28 "Object_Position28" 29 "Object_Position29" 30 "Object_Position30" 31 "Object_Position31" 32 "Object_Position32" 33 "Object_Position33" 34 "Object_Position34" 35 "Object_Position35" 36 "Object_Position36" 37 "Object_Position37" 38 "Object_Position38" 39 "Object_Position39" 40 "Object_Position40" 41 "Object_Position41" 42 "Object_Position42" 43 "Object_Position43" 44 "Object_Position44" 45 "Object_Position45" 46 "Object_Position46" 47 "Object_Position47" 48 "Object_Position48" 49 "Object_Position49" 50 "Object_Position50" 51 "Object_Position51" 52 "Object_Position52" 53 "Object_Position53" 54 "Object_Position54" 55 "Object_Position55" 56 "Object_Position56" 57 "Object_Position57" 58 "Object_Position58" 59 "Object_Position59" 60 "Object_Position60" 61 "Object_Position61" 62 "Object_Position62" 63 "Object_Position63";
VAL_ 1154 IHM_L1_POSITION 0 "None" 1 "Object_Position1 " 2 "Object_Position2" 3 "Object_Position3" 4 "Object_Position4" 5 "Object_Position5" 6 "Object_Position6" 7 "Object_Position7" 8 "Object_Position8" 9 "Object_Position9" 10 "Object_Position10" 11 "Object_Position11" 12 "Object_Position12" 13 "Object_Position13" 14 "Object_Position14" 15 "Object_Position15" 16 "Object_Position16" 17 "Object_Position17" 18 "Object_Position18" 19 "Object_Position19" 20 "Object_Position20" 21 "Object_Position21" 22 "Object_Position22" 23 "Object_Position23" 24 "Object_Position24" 25 "Object_Position25" 26 "Object_Position26" 27 "Object_Position27" 28 "Object_Position28" 29 "Object_Position29" 30 "Object_Position30" 31 "Object_Position31" 32 "Object_Position32" 33 "Object_Position33" 34 "Object_Position34" 35 "Object_Position35" 36 "Object_Position36" 37 "Object_Position37" 38 "Object_Position38" 39 "Object_Position39" 40 "Object_Position40" 41 "Object_Position41" 42 "Object_Position42" 43 "Object_Position43" 44 "Object_Position44" 45 "Object_Position45" 46 "Object_Position46" 47 "Object_Position47" 48 "Object_Position48" 49 "Object_Position49" 50 "Object_Position50" 51 "Object_Position51" 52 "Object_Position52" 53 "Object_Position53" 54 "Object_Position54" 55 "Object_Position55" 56 "Object_Position56" 57 "Object_Position57" 58 "Object_Position58" 59 "Object_Position59" 60 "Object_Position60" 61 "Object_Position61" 62 "Object_Position62" 63 "Object_Position63";
VAL_ 1154 IHM_L2_POSITION 0 "None" 1 "Object_Position1 " 2 "Object_Position2" 3 "Object_Position3" 4 "Object_Position4" 5 "Object_Position5" 6 "Object_Position6" 7 "Object_Position7" 8 "Object_Position8" 9 "Object_Position9" 10 "Object_Position10" 11 "Object_Position11" 12 "Object_Position12" 13 "Object_Position13" 14 "Object_Position14" 15 "Object_Position15" 16 "Object_Position16" 17 "Object_Position17" 18 "Object_Position18" 19 "Object_Position19" 20 "Object_Position20" 21 "Object_Position21" 22 "Object_Position22" 23 "Object_Position23" 24 "Object_Position24" 25 "Object_Position25" 26 "Object_Position26" 27 "Object_Position27" 28 "Object_Position28" 29 "Object_Position29" 30 "Object_Position30" 31 "Object_Position31" 32 "Object_Position32" 33 "Object_Position33" 34 "Object_Position34" 35 "Object_Position35" 36 "Object_Position36" 37 "Object_Position37" 38 "Object_Position38" 39 "Object_Position39" 40 "Object_Position40" 41 "Object_Position41" 42 "Object_Position42" 43 "Object_Position43" 44 "Object_Position44" 45 "Object_Position45" 46 "Object_Position46" 47 "Object_Position47" 48 "Object_Position48" 49 "Object_Position49" 50 "Object_Position50" 51 "Object_Position51" 52 "Object_Position52" 53 "Object_Position53" 54 "Object_Position54" 55 "Object_Position55" 56 "Object_Position56" 57 "Object_Position57" 58 "Object_Position58" 59 "Object_Position59" 60 "Object_Position60" 61 "Object_Position61" 62 "Object_Position62" 63 "Object_Position63";
VAL_ 1154 IHM_R1_POSITION 0 "None" 1 "Object_Position1 " 2 "Object_Position2" 3 "Object_Position3" 4 "Object_Position4" 5 "Object_Position5" 6 "Object_Position6" 7 "Object_Position7" 8 "Object_Position8" 9 "Object_Position9" 10 "Object_Position10" 11 "Object_Position11" 12 "Object_Position12" 13 "Object_Position13" 14 "Object_Position14" 15 "Object_Position15" 16 "Object_Position16" 17 "Object_Position17" 18 "Object_Position18" 19 "Object_Position19" 20 "Object_Position20" 21 "Object_Position21" 22 "Object_Position22" 23 "Object_Position23" 24 "Object_Position24" 25 "Object_Position25" 26 "Object_Position26" 27 "Object_Position27" 28 "Object_Position28" 29 "Object_Position29" 30 "Object_Position30" 31 "Object_Position31" 32 "Object_Position32" 33 "Object_Position33" 34 "Object_Position34" 35 "Object_Position35" 36 "Object_Position36" 37 "Object_Position37" 38 "Object_Position38" 39 "Object_Position39" 40 "Object_Position40" 41 "Object_Position41" 42 "Object_Position42" 43 "Object_Position43" 44 "Object_Position44" 45 "Object_Position45" 46 "Object_Position46" 47 "Object_Position47" 48 "Object_Position48" 49 "Object_Position49" 50 "Object_Position50" 51 "Object_Position51" 52 "Object_Position52" 53 "Object_Position53" 54 "Object_Position54" 55 "Object_Position55" 56 "Object_Position56" 57 "Object_Position57" 58 "Object_Position58" 59 "Object_Position59" 60 "Object_Position60" 61 "Object_Position61" 62 "Object_Position62" 63 "Object_Position63";
VAL_ 661 FCAM_VRU5_TYPE 0 "None" 1 "Pedestrian" 2 "bicycle" 3 "Unknown";
VAL_ 661 FCAM_VRU1_TYPE 0 "None" 1 "Pedestrian" 2 "bicycle" 3 "Unknown";
VAL_ 661 FCAM_VRU2_TYPE 0 "None" 1 "Pedestrian" 2 "bicycle" 3 "Unknown";
VAL_ 661 FCAM_VRU3_TYPE 0 "None" 1 "Pedestrian" 2 "bicycle" 3 "Unknown";
VAL_ 661 FCAM_LEFTRIGHT_LINE_DIS_ACTUAL 2047 "Unavailable" 2046 "Invalid";
VAL_ 661 FCAM_LEFTRIGHT_LINECOLOR 0 "Unknown" 1 "White" 2 "Yellow_Red_Orange" 3 "Blue_Green";
VAL_ 661 FCAM_LEFTRIGHT_LINECURVATURE_EST 65534 "Invalid" 65535 "Unavailable";
VAL_ 661 FCAM_LEFTRIGHT_LINECURVATURE_DER 131070 "Invalid" 131071 "Unavaliable";
VAL_ 661 FCAM_LLANE_ROADEDG_CURVATURE_DER 131070 "Invalid" 131071 "Unavaliable";
VAL_ 661 FCAM_RIGHTLEFT_LINECURVATURE_DER 131070 "Invalid" 131071 "Unavaliable";
VAL_ 661 FCAM_RLANE_ROADEDG_CURVATURE_DER 131070 "Invalid" 131071 "Unavaliable";
VAL_ 661 FCAM_LLANE_ROADEDG_CURVATURE_EST 65534 "Invalid" 65535 "Unavailable";
VAL_ 661 FCAM_RIGHTLEFT_LINECURVATURE_EST 65534 "Invalid" 65535 "Unavailable";
VAL_ 661 FCAM_RLANE_ROADEDG_CURVATURE_EST 65534 "Invalid" 65535 "Unavailable";
VAL_ 661 FCAM_LLANE_ROADEDG_DIST_ACTUAL 2047 "Unavailable" 2046 "Invalid";
VAL_ 661 FCAM_RIGHTLEFT_LINE_DIST_ACTUAL 2047 "Unavailable" 2046 "Invalid";
VAL_ 661 FCAM_RLANE_ROADEDG_DIST_ACTUAL 2047 "Unavailable" 2046 "Invalid";
VAL_ 661 FCAM_LEFTRIGHT_LINEHEADINGANGLE 4094 "Invalid" 4095 "Unavailable";
VAL_ 661 FCAM_LLANE_ROADEDG_HEADINGANGLE 4094 "Invalid" 4095 "Unavailable";
VAL_ 661 FCAM_RIGHTLEFT_LINEHEADINGANGLE 4094 "Invalid" 4095 "Unavailable";
VAL_ 661 FCAM_RLANE_ROADEDG_HEADINGANGLE 4094 "Invalid" 4095 "Unavailable";
VAL_ 661 FCAM_LEFTRIGHT_LINEDETECTIONSTS 0 "NotValid" 1 "Valid";
VAL_ 661 FCAM_LEFTRIGHT_LINEMARKERQUALITY 0 "Not_available" 1 "Predicted" 2 "Detected";
VAL_ 661 FCAM_LEFTRIGHT_LINETYPE 0 "NotDetected" 1 "SingleDashed" 2 "SingleSolid" 3 "DoubleDashedDashed" 4 "DoubleDashedSolid" 5 "DoubleSolidDashed" 6 "DoubleSolidSolid" 7 "Unknown";
VAL_ 661 FCAM_RIGHTLEFT_LINETYPE 0 "NotDetected" 1 "SingleDashed" 2 "SingleSolid" 3 "DoubleDashedDashed" 4 "DoubleDashedSolid" 5 "DoubleSolidDashed" 6 "DoubleSolidSolid" 7 "Unknown";
VAL_ 661 FCAM_RIGHTLEFT_LINEDETECTIONSTS 0 "NotValid" 1 "Valid";
VAL_ 661 FCAM_RIGHTLEFT_LINECOLOR 0 "Unknown" 1 "White" 2 "Yellow_Red_Orange" 3 "Blue_Green";
VAL_ 661 FCAM_LLANE_ROADEDG_MARKERQUALITY 0 "Not_available" 1 "Predicted" 2 "Detected";
VAL_ 661 FCAM_RIGHTLEFT_LINEMARKERQUALITY 0 "Not_available" 1 "Predicted" 2 "Detected";
VAL_ 661 FCAM_RLANE_ROADEDG_MARKERQUALITY 0 "Not_available" 1 "Predicted" 2 "Detected";
VAL_ 661 FCAM_LLANE_ROADEDG_DET_STATUS 0 "NotValid" 1 "Valid";
VAL_ 661 FCAM_LLANE_ROADEDGETYPE 0 "Flat" 1 "Elevated_Structure" 2 "Curb" 3 "Cones_poles" 4 "Parking_cars" 5 "No_Roadegde" 6 "Reserved" 7 "Reserved";
VAL_ 661 FCAM_LLINE_VALIDFORLKA 0 "False" 1 "True";
VAL_ 661 FCAM_OBJECTCROSSING 0 "No_Change" 1 "Change_to_Left" 2 "Change_to_Right" 3 "Reserved";
VAL_ 661 FCAM_RLANE_ROADEDG_DET_STATUS 0 "NotValid" 1 "Valid";
VAL_ 661 FCAM_RLANE_ROADEDGETYPE 0 "Flat" 1 "Elevated_Structure" 2 "Curb" 3 "Cones_poles" 4 "Parking_cars" 5 "No_Roadegde" 6 "Reserved" 7 "Reserved";
VAL_ 661 FCAM_RLINE_VALIDFORLKA 0 "False" 1 "True";
VAL_ 641 AEB_PREFILL_REQUEST 0 "False" 1 "True";
VAL_ 641 AEB_STATE_A 0 "Unavailable" 1 "Fault" 2 "Init" 3 "Inhibited" 4 "Waiting" 5 "Ready" 6 "Reserved" 7 "Reserved";
VAL_ 641 DRIVER_STEERING_WHEEL_INTERACT 0 "Take_back_by_the_driver " 1 "Hands_Off " 2 "Hands_On " 3 "Positionning_mode" 4 "Incentive_mode" 5 "Reserved" 6 "Reserved" 7 "Reserved";
VAL_ 641 ACTIVATED_LATERAL_ASSIST_MODE 0 "LKA" 1 "LPA";
VAL_ 641 PERCEPTION_SYSTEM_STATE 0 "Perception redundant" 1 "Perception active" 2 "Perception temporarily inactive" 3 "Perception temporarily blind " 4 "Reserved" 5 "Reserved" 6 "Reserved" 7 "Reserved" 8 "Reserved" 9 "Reserved" 10 "Reserved" 11 "Reserved" 12 "Reserved" 13 "Reserved" 14 "Perception permanently inactive" 15 "Invalid";
VAL_ 641 LANE_ASSIST_STATE 0 "Unavailable" 1 "Unselected" 2 "Selected" 3 "Suspensed" 4 "Active" 5 "Defect" 6 "Reserved" 7 "Reserved";
VAL_ 641 PERCEPTION_STATE 0 "Perception redundant" 1 "Perception active" 2 "Perception temporarily inactive" 3 "Perception temporarily blind " 4 "Reserved" 5 "Reserved" 6 "Reserved" 7 "Reserved" 8 "Reserved" 9 "Reserved" 10 "Reserved" 11 "Reserved" 12 "Reserved" 13 "Reserved" 14 "Perception permanently inactive" 15 "Invalid";
VAL_ 641 ADAS_LONGI_ACCEL_TYPE 0 "NONE" 1 "ACC" 2 "AEB_RAD" 3 "AEB_CAM" 4 "AEB_FUS" 5 "AEB_XTD" 6 "AEB_LSX" 7 "SBA";
VAL_ 641 LPA_PERCEPTION_STATE 0 "UNAVAILABLE" 1 "DEFECT" 2 "ACTIVE" 3 "AVAILABLE";
VAL_ 1153 AEB_LIMITED 0 "False" 1 "True";
VAL_ 1153 FCW2_REQUEST 0 "False" 1 "True";
VAL_ 1153 FRONT_CAMERA_BLIND 0 "False" 1 "True";
VAL_ 1153 FRONT_RADAR_BLIND 0 "False" 1 "True";
VAL_ 1153 HMI_AEB_BRAKING_ACTIVE 0 "False" 1 "True";
VAL_ 1153 FCW2_SIDEALERT 0 "None" 1 "Left" 2 "Right" 3 "Reserved";
VAL_ 1153 FCW_STATE_A 0 "Unavailable" 1 "Fault" 2 "Init" 3 "Inhibited" 4 "Waiting" 5 "Ready" 6 "Reserved" 7 "Reserved";
VAL_ 1153 EBF_ACCELERATION_TYPE 0 "None" 1 "AEB_Rad" 2 "AEB_Cam" 3 "AEB_Fus" 4 "AEB_Xtd" 5 "AEB_LsX" 6 "SBA" 7 "Reserved";
VAL_ 1153 FCW1_TARGET_PRESENT 0 "FALSE" 1 "TRUE";
VAL_ 1153 AEB_HAPTIC_CRITICAL 0 "FALSE" 1 "TRUE";
VAL_ 1153 AEB_DETECTION_LIMITED 0 "FALSE" 1 "TRUE";
VAL_ 1153 DATA_TRANSFER_STATUS 0 "Unavailable" 1 "Sucess" 2 "Failed" 3 "Not_used";
VAL_ 1153 ERROR_TYPE 0 "No_error" 1 "Fatal_Error" 2 "No_fatal_error" 3 "Not_used";
VAL_ 1153 READINESS_STATUS 0 "Not_ready" 1 "Ready for transfer";
VAL_ 1153 ERROR_REASON 0 "No error" 1 "Fatal_Error" 2 "No_fatal_error" 3 "Not_used";
VAL_ 1153 SAFETY_LRCF_READY_STATE 0 "NOT_READY" 1 "READY";
VAL_ 1153 LRCF_UPDATE_STATUS 0 "NOT_UPDATING" 1 "UPDATE_IN_PROGRESS" 2 "UPDATE_COMPLETED" 3 "FAULT_UPDATE_FAILED";
VAL_ 1409 LKA_STATE 0 "Unselected" 1 "Selected" 2 "Active" 3 "Degraded" 4 "TemporaryUnavailable" 5 "Defect" 6 "Reserved6" 7 "Reserved7";
VAL_ 1409 RCTA_STATE 0 "Unavailable" 1 "Init" 2 "Waiting" 3 "Active" 4 "Failure" 5 "Inhibited" 6 "Invalid" 7 "Reserved7";
VAL_ 1409 RCTA_WARNINGSTATE_LEFT 0 "None" 1 "Level 1" 2 "Level 2" 3 "Level 3";
VAL_ 1409 RCTA_WARNINGSTATE_RIGHT 0 "None" 1 "Level 1" 2 "Level 2" 3 "Level 3";
VAL_ 1409 BLINDSPOT_DETECTION_STATUS 0 "INACTIVE" 1 "INHIBITED" 2 "BLOCKED_REAR" 3 "BLOCKED_FRONT" 4 "BLOCKED_BOTH" 5 "UNAVAILABLE" 6 "ACTIVE" 7 "FAULT";
VAL_ 1409 BLINDSPOTDETECTIONLEFTALERTRQST 0 "NO_REQUEST" 1 "NORMAL_REQUEST" 2 "CRITICAL_REQUEST" 3 "Reserved";
VAL_ 1409 BLINDSPOTDETECTIONRIGHTALERTRQST 0 "NO_REQUEST" 1 "NORMAL_REQUEST" 2 "CRITICAL_REQUEST" 3 "Reserved";
VAL_ 1409 FRONT_CAMERA_SPEED_LIMIT_SOURCE 0 "No Speed Limit" 1 "Explicit" 2 "Implicit" 3 "RoadType" 4 "LastKnown" 5 "Reserved" 6 "Reserved" 7 "Reserved";
VAL_ 1409 FRONT_CAMERA_SPEED_LIMIT_SHAPE 0 "not_detected" 1 "square" 2 "round" 3 "zone" 4 "Reserved" 5 "Reserved" 6 "Reserved" 7 "Reserved";
VAL_ 1409 FRONT_CAMERA_CONDSPEED_LIMIT_TYP 0 "No Speed Limit" 1 "Trailer" 2 "Rain" 3 "Snow" 4 "School" 5 "Time" 6 "Noise" 7 "Distance For Arrow" 8 "Night" 9 "Work" 10 "Zone" 11 "Arrow Left" 12 "Arrow Right" 13 "Advisory" 14 "Fog" 15 "Unknown" 16 "Reserved" 17 "Reserved" 18 "Reserved" 19 "Reserved" 20 "Reserved" 21 "Reserved" 22 "Reserved" 23 "Reserved" 24 "Reserved" 25 "Reserved" 26 "Reserved" 27 "Reserved" 28 "Reserved" 29 "Reserved" 30 "Reserved" 31 "Unknown";
VAL_ 1409 FRONT_CAMERA_SIGN_STATUS 0 "Normal operation" 1 "blocked" 2 "degraded" 3 "defect";
VAL_ 1409 FRONT_CAMERA_ROAD_TYPE_RAW 0 "Unknown" 1 "Highway" 2 "City" 3 "Rural";
VAL_ 1409 FRONT_CAMERA_ROAD_TYPE 0 "Unknown" 1 "Highway" 2 "Expressway" 3 "Rural" 4 "City" 5 "bicycle zone" 6 "pedestrian zone" 7 "school zone" 8 "shared space" 9 "Reserved" 10 "Reserved" 11 "Reserved" 12 "Reserved" 13 "Reserved" 14 "Reserved" 15 "Reserved";
VAL_ 1409 FRONT_CAMERA_TRAFFIC_SIGN 0 "No sign" 1 "No Entry" 2 "Stop" 3 "Yield" 4 "overtaking forbidden" 5 "overtaking allowed" 6 "Reserved" 7 "Reserved";
VAL_ 1409 LONGITUDINAL_DRIVING_STINFO 0 "Unavailable" 1 "Available" 2 "InProgress" 3 "Suspended" 4 "BrakeOnly" 5 "ActiveStop" 6 "GoRequest" 7 "NccInProgress" 8 "Reserved" 9 "Reserved" 10 "Reserved" 11 "Reserved" 12 "Reserved" 13 "Reserved" 14 "Reserved" 15 "Defect";
VAL_ 1409 LAS_LEFT_LINE_STATE 0 "NoLaneBoundariesDetected" 1 "LaneBoundariesDetected" 2 "LKAActive" 3 "LDWActive" 4 "LKAAndLDWActive" 5 "ALCAActive" 6 "LKAOActive" 7 "Reserved";
VAL_ 1409 LAS_RIGHT_LINE_STATE 0 "NoLaneBoundariesDetected" 1 "LaneBoundariesDetected" 2 "LKAActive" 3 "LDWActive" 4 "LKAAndLDWActive" 5 "ALCAActive" 6 "LKAOActive" 7 "Reserved";
VAL_ 1409 LAS_INTERRUPT_ALERT 0 "False" 1 "True";
VAL_ 1409 LAS_DRIVER_CONTROL_ALERT 0 "None" 1 "DriverInteractionReq" 2 "SystemLimitAbort" 3 "Reserved";
VAL_ 1409 HIGH_BEAM_ASSIST_REQ_FROM_CAMERA 0 "Low_beam_position" 1 "High_beam_position";
VAL_ 1409 HIGH_BEAM_ASSIST_CONDITION 0 "NOK" 1 "OK";
VAL_ 1409 HIGH_BEAM_ASSIST_FAULT 0 "Normal" 1 "Faulty";
VAL_ 1409 LIGHTED_ZONE_DETECTED 0 "False" 1 "True" 2 "Invalid" 3 "Unavailable" 4 "Reserved" 5 "Reserved" 6 "Reserved" 7 "Reserved";
VAL_ 1409 LAS_FRONT_SENSOR_BLOCKAGE_STATUS 0 "NoFrontBlockage" 1 "FrontCamBlockage" 2 "FrontRadarBlockage" 3 "FullFrontBlockage";
VAL_ 1409 LAS_REAR_SENSOR_BLOKAGE_STS 0 "No LAS rear sensor blockage" 1 "Left rear sensor blockage" 2 "Right rear sensor blockage" 3 "Multiple rear sensors blockage";
VAL_ 1409 LAS_HAPTIC_ALERT_REQ 0 "NotActive" 1 "SideIndependendActive" 2 "LeftActive" 3 "RightActive";
VAL_ 1409 VRU_IN_EXTENDED_FRONT_AREA 0 "NO_VRU_DETECT_IN_EXT_FRONT_AREA" 1 "VRU_DETECT_IN_EXT_FRONT_AREA";
